VERSION ""

NS_ :

BS_:

BU_: SCCM RF_HUB PTS ORC OCM IC HCP HALF ETM ESM ESC EPS ECM EBCM DIAGNOST DASM CBC AirSusp TCM DTCM ELSDM

BO_ 1026 NM_IC: 8 IC
 SG_ WakeupRsn_IC m2 : 32|8@1+ (1,0) [0|0] ""  EBCM,HCP,ESM,ESC,SCCM,EPS,IC,CBC,RF_HUB
 SG_ WakeupCnt_IC m2 : 40|8@1+ (1,0) [0|254] ""  EBCM,HCP,ESM,ESC,SCCM,EPS,IC,CBC,RF_HUB
 SG_ Nw_Id_IC : 56|8@1+ (1,0) [0|0] ""  EBCM,HCP,ESM,ESC,SCCM,EPS,IC,CBC,RF_HUB
 SG_ NM_Ud_Srv_IC M : 24|8@1+ (1,0) [0|0] ""  EBCM,HCP,ESM,ESC,SCCM,EPS,IC,CBC,RF_HUB
 SG_ NM_Ud_Launch_IC : 16|6@1+ (1,0) [0|0] ""  EBCM,HCP,ESM,ESC,SCCM,EPS,IC,CBC,RF_HUB
 SG_ NM_Successor_IC : 8|8@1+ (1,0) [0|63] ""  EBCM,HCP,ESM,ESC,SCCM,EPS,IC,CBC,RF_HUB
 SG_ NM_Sleep_Ind_IC : 23|1@1+ (1,0) [0|0] ""  EBCM,HCP,ESM,ESC,SCCM,EPS,IC,CBC,RF_HUB
 SG_ NM_Sleep_Ack_IC : 22|1@1+ (1,0) [0|0] ""  EBCM,HCP,ESM,ESC,SCCM,EPS,IC,CBC,RF_HUB
 SG_ NM_Mode_IC : 0|8@1+ (1,0) [0|0] ""  EBCM,HCP,ESM,ESC,SCCM,EPS,IC,CBC,RF_HUB
 SG_ Awake_NwSt_IC m15 : 32|1@1+ (1,0) [0|0] ""  EBCM,HCP,ESM,ESC,SCCM,EPS,IC,CBC,RF_HUB
 SG_ Awake_Diag_Actv_IC m15 : 33|1@1+ (1,0) [0|0] ""  EBCM,HCP,ESM,ESC,SCCM,EPS,IC,CBC,RF_HUB

BO_ 1025 NM_CBC: 8 CBC
 SG_ WakeupRsn_CBC m2 : 32|8@1+ (1,0) [0|0] ""  EBCM,HCP,ESM,ESC,SCCM,EPS,IC,CBC,RF_HUB
 SG_ WakeupCnt_CBC m2 : 40|8@1+ (1,0) [0|254] ""  EBCM,HCP,ESM,ESC,SCCM,EPS,IC,CBC,RF_HUB
 SG_ Nw_Id_CBC : 56|8@1+ (1,0) [0|0] ""  EBCM,HCP,ESM,ESC,SCCM,EPS,IC,CBC,RF_HUB
 SG_ NM_Ud_Srv_CBC M : 24|8@1+ (1,0) [0|0] ""  EBCM,HCP,ESM,ESC,SCCM,EPS,IC,CBC,RF_HUB
 SG_ NM_Ud_Launch_CBC : 16|6@1+ (1,0) [0|0] ""  EBCM,HCP,ESM,ESC,SCCM,EPS,IC,CBC,RF_HUB
 SG_ NM_Successor_CBC : 8|8@1+ (1,0) [0|63] ""  EBCM,HCP,ESM,ESC,SCCM,EPS,IC,CBC,RF_HUB
 SG_ NM_Sleep_Ind_CBC : 23|1@1+ (1,0) [0|0] ""  EBCM,HCP,ESM,ESC,SCCM,EPS,IC,CBC,RF_HUB
 SG_ NM_Sleep_Ack_CBC : 22|1@1+ (1,0) [0|0] ""  EBCM,HCP,ESM,ESC,SCCM,EPS,IC,CBC,RF_HUB
 SG_ NM_Mode_CBC : 0|8@1+ (1,0) [0|0] ""  EBCM,HCP,ESM,ESC,SCCM,EPS,IC,CBC,RF_HUB
 SG_ Awake_NwSt_CBC m15 : 32|1@1+ (1,0) [0|0] ""  EBCM,HCP,ESM,ESC,SCCM,EPS,IC,CBC,RF_HUB
 SG_ Awake_Diag_Actv_CBC m15 : 33|1@1+ (1,0) [0|0] ""  EBCM,HCP,ESM,ESC,SCCM,EPS,IC,CBC,RF_HUB

BO_ 1024 NM_RF_HUB: 8 RF_HUB
 SG_ WakeupRsn_RF_HUB m2 : 32|8@1+ (1,0) [0|0] ""  EBCM,HCP,ESM,ESC,SCCM,EPS,IC,CBC,RF_HUB
 SG_ WakeupCnt_RF_HUB m2 : 40|8@1+ (1,0) [0|254] ""  EBCM,HCP,ESM,ESC,SCCM,EPS,IC,CBC,RF_HUB
 SG_ Nw_Id_RF_HUB : 56|8@1+ (1,0) [0|0] ""  EBCM,HCP,ESM,ESC,SCCM,EPS,IC,CBC,RF_HUB
 SG_ NM_Ud_Srv_RF_HUB M : 24|8@1+ (1,0) [0|0] ""  EBCM,HCP,ESM,ESC,SCCM,EPS,IC,CBC,RF_HUB
 SG_ NM_Ud_Launch_RF_HUB : 16|6@1+ (1,0) [0|0] ""  EBCM,HCP,ESM,ESC,SCCM,EPS,IC,CBC,RF_HUB
 SG_ NM_Successor_RF_HUB : 8|8@1+ (1,0) [0|63] ""  EBCM,HCP,ESM,ESC,SCCM,EPS,IC,CBC,RF_HUB
 SG_ NM_Sleep_Ind_RF_HUB : 23|1@1+ (1,0) [0|0] ""  EBCM,HCP,ESM,ESC,SCCM,EPS,IC,CBC,RF_HUB
 SG_ NM_Sleep_Ack_RF_HUB : 22|1@1+ (1,0) [0|0] ""  EBCM,HCP,ESM,ESC,SCCM,EPS,IC,CBC,RF_HUB
 SG_ NM_Mode_RF_HUB : 0|8@1+ (1,0) [0|0] ""  EBCM,HCP,ESM,ESC,SCCM,EPS,IC,CBC,RF_HUB
 SG_ Awake_NwSt_RF_HUB m15 : 32|1@1+ (1,0) [0|0] ""  EBCM,HCP,ESM,ESC,SCCM,EPS,IC,CBC,RF_HUB
 SG_ Awake_Diag_Actv_RF_HUB m15 : 33|1@1+ (1,0) [0|0] ""  EBCM,HCP,ESM,ESC,SCCM,EPS,IC,CBC,RF_HUB

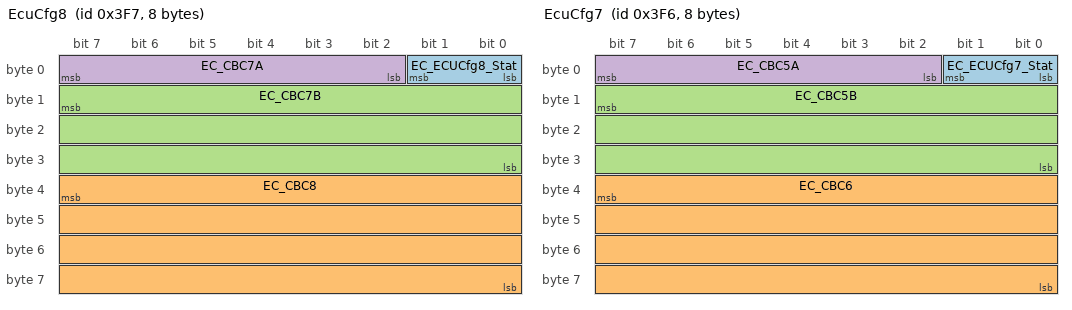
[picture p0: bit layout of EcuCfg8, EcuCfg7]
BO_ 1015 EcuCfg8: 8 CBC
 SG_ EC_ECUCfg8_Stat : 0|2@1+ (1,0) [0|0] ""  RF_HUB
 SG_ EC_CBC8 : 39|32@0+ (1,0) [0|0] ""  RF_HUB
 SG_ EC_CBC7B : 15|24@0+ (1,0) [0|0] ""  RF_HUB
 SG_ EC_CBC7A : 2|6@1+ (1,0) [0|0] ""  RF_HUB

BO_ 1014 EcuCfg7: 8 CBC
 SG_ EC_ECUCfg7_Stat : 0|2@1+ (1,0) [0|0] ""  RF_HUB
 SG_ EC_CBC6 : 39|32@0+ (1,0) [0|0] ""  RF_HUB
 SG_ EC_CBC5B : 15|24@0+ (1,0) [0|0] ""  RF_HUB
 SG_ EC_CBC5A : 2|6@1+ (1,0) [0|0] ""  RF_HUB

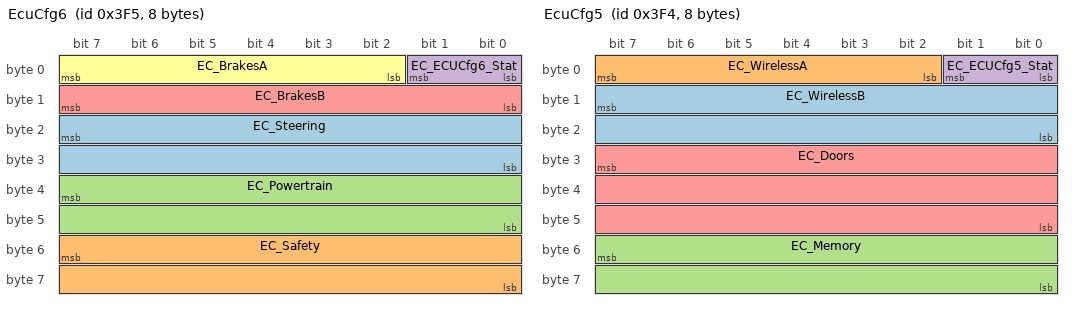
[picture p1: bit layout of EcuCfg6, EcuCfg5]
BO_ 1013 EcuCfg6: 8 CBC
 SG_ EC_Steering : 23|16@0+ (1,0) [0|0] ""  RF_HUB,EPS
 SG_ EC_Safety : 55|16@0+ (1,0) [0|0] ""  ORC,RF_HUB
 SG_ EC_Powertrain : 39|16@0+ (1,0) [0|0] ""  RF_HUB
 SG_ EC_ECUCfg6_Stat : 0|2@1+ (1,0) [0|0] ""  RF_HUB,ORC,ESC,ECM
 SG_ EC_BrakesB : 8|8@1+ (1,0) [0|0] ""  ESC,RF_HUB
 SG_ EC_BrakesA : 2|6@1+ (1,0) [0|0] ""  ESC,RF_HUB

BO_ 1012 EcuCfg5: 8 CBC
 SG_ EC_WirelessB : 15|16@0+ (1,0) [0|0] ""  RF_HUB
 SG_ EC_WirelessA : 2|6@1+ (1,0) [0|0] ""  RF_HUB
 SG_ EC_Memory : 55|16@0+ (1,0) [0|0] ""  RF_HUB,OCM
 SG_ EC_ECUCfg5_Stat : 0|2@1+ (1,0) [0|0] ""  RF_HUB,OCM
 SG_ EC_Doors : 31|24@0+ (1,0) [0|0] ""  RF_HUB

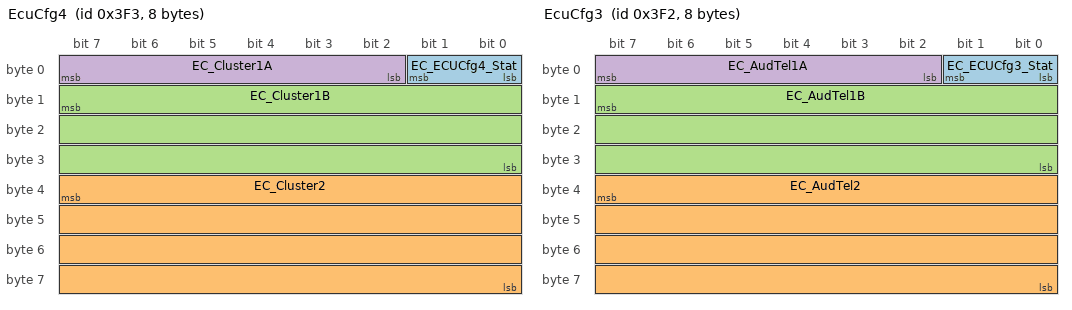
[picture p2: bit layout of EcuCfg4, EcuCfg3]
BO_ 1011 EcuCfg4: 8 CBC
 SG_ EC_ECUCfg4_Stat : 0|2@1+ (1,0) [0|0] ""  IC,RF_HUB
 SG_ EC_Cluster2 : 39|32@0+ (1,0) [0|0] ""  RF_HUB
 SG_ EC_Cluster1B : 15|24@0+ (1,0) [0|0] ""  RF_HUB,IC
 SG_ EC_Cluster1A : 2|6@1+ (1,0) [0|0] ""  IC,RF_HUB

BO_ 1010 EcuCfg3: 8 CBC
 SG_ EC_ECUCfg3_Stat : 0|2@1+ (1,0) [0|0] ""  RF_HUB
 SG_ EC_AudTel2 : 39|32@0+ (1,0) [0|0] ""  RF_HUB
 SG_ EC_AudTel1B : 15|24@0+ (1,0) [0|0] ""  RF_HUB
 SG_ EC_AudTel1A : 2|6@1+ (1,0) [0|0] ""  RF_HUB

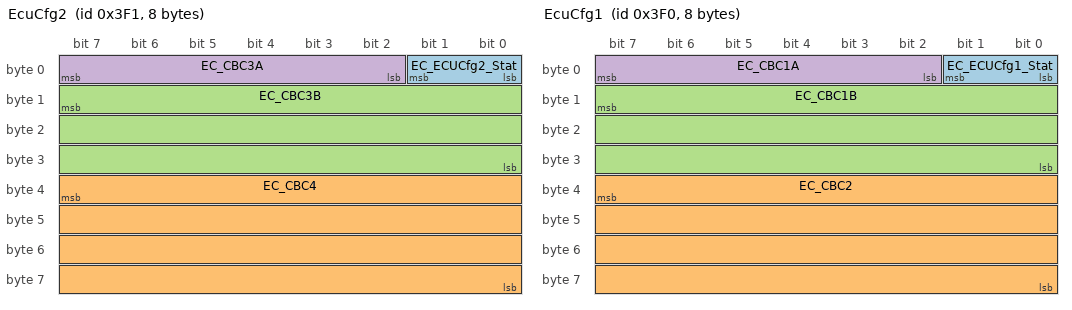
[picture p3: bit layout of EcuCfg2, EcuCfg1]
BO_ 1009 EcuCfg2: 8 CBC
 SG_ EC_ECUCfg2_Stat : 0|2@1+ (1,0) [0|0] ""  RF_HUB
 SG_ EC_CBC4 : 39|32@0+ (1,0) [0|0] ""  RF_HUB
 SG_ EC_CBC3B : 15|24@0+ (1,0) [0|0] ""  RF_HUB
 SG_ EC_CBC3A : 2|6@1+ (1,0) [0|0] ""  RF_HUB

BO_ 1008 EcuCfg1: 8 CBC
 SG_ EC_ECUCfg1_Stat : 0|2@1+ (1,0) [0|0] ""  RF_HUB
 SG_ EC_CBC2 : 39|32@0+ (1,0) [0|0] ""  RF_HUB
 SG_ EC_CBC1B : 15|24@0+ (1,0) [0|0] ""  RF_HUB
 SG_ EC_CBC1A : 2|6@1+ (1,0) [0|0] ""  RF_HUB

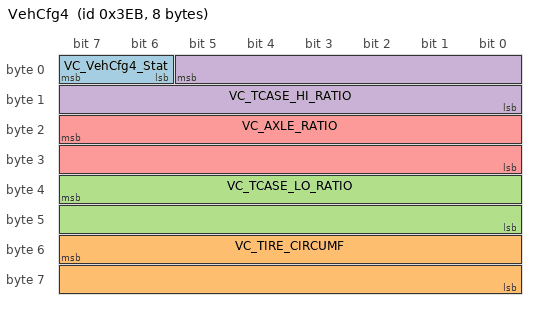
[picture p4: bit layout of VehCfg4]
BO_ 1003 VehCfg4: 8 CBC
 SG_ VC_VehCfg4_Stat : 6|2@1+ (1,0) [0|0] ""  RF_HUB,PTS,ORC,HCP,HALF,ESC,ECM,DASM
 SG_ VC_TIRE_CIRCUMF : 55|16@0+ (1,0) [0|65534] "mm"  RF_HUB,PTS,ORC,HALF,ESC,EPS
 SG_ VC_TCASE_LO_RATIO : 39|16@0+ (0.001,0) [0|65.534] ""  RF_HUB,ESC
 SG_ VC_TCASE_HI_RATIO : 5|14@0+ (0.001,0) [0|16.382] ""  RF_HUB,ESC
 SG_ VC_AXLE_RATIO : 23|16@0+ (0.001,0) [0|65.534] ""  RF_HUB,ESC,DASM

BO_ 1002 VehCfg3: 8 CBC
 SG_ VC_WIN_EXPR_FEAT : 24|2@1+ (1,0) [0|0] ""  RF_HUB
 SG_ VC_WHL_BASE : 12|2@1+ (1,0) [0|0] ""  RF_HUB,IC
 SG_ VC_VehCfg3_Stat : 0|2@1+ (1,0) [0|0] ""  SCCM,RF_HUB,PTS,ORC,IC,HCP,HALF,ESC,ECM,DASM
 SG_ VC_VEH_BRAND : 44|4@1+ (1,0) [0|0] ""  RF_HUB,PTS,HALF
 SG_ VC_TEMP_DISP : 39|1@1+ (1,0) [0|0] ""  IC,RF_HUB
 SG_ VC_TcaseTyp : 8|4@1+ (1,0) [0|0] ""  ESC,RF_HUB
 SG_ VC_SunShade_Present : 7|1@1+ (1,0) [0|0] ""  RF_HUB
 SG_ VC_SRT_PRSNT : 30|1@1+ (1,0) [0|0] ""  RF_HUB,ORC
 SG_ VC_SPORT_PRSNT : 60|1@1+ (1,0) [0|0] ""  RF_HUB
 SG_ VC_SecLkPrsnt : 52|1@1+ (1,0) [0|0] ""  RF_HUB
 SG_ VC_RKE_PRSNT : 6|1@1+ (1,0) [0|0] ""  RF_HUB
 SG_ VC_PWR_RT_SLDR : 4|1@1+ (1,0) [0|0] ""  RF_HUB
 SG_ VC_PWR_LT_SLDR : 5|1@1+ (1,0) [0|0] ""  RF_HUB
 SG_ VC_PWR_LFT_GT : 3|1@1+ (1,0) [0|0] ""  RF_HUB
 SG_ VC_Prem_TPM : 58|1@1+ (1,0) [0|0] ""  ORC,IC,RF_HUB
 SG_ VC_POLICE : 2|1@1+ (1,0) [0|0] ""  RF_HUB,ORC
 SG_ VC_PE_Prsnt : 62|1@1+ (1,0) [0|0] ""  RF_HUB
 SG_ VC_PDDL_PRSNT : 59|1@1+ (1,0) [0|0] ""  RF_HUB
 SG_ VC_Liftgate_Trunk : 53|2@1+ (1,0) [0|0] ""  IC,RF_HUB
 SG_ VC_KG_Prsnt : 63|1@1+ (1,0) [0|0] ""  RF_HUB,IC
 SG_ VC_IntEC_MIRR : 49|1@1+ (1,0) [0|0] ""  RF_HUB
 SG_ VC_HVAC_Config : 40|4@1+ (1,0) [0|0] ""  RF_HUB
 SG_ VC_HID_HL : 51|1@1+ (1,0) [0|0] ""  RF_HUB
 SG_ VC_FUEL_CAP : 16|8@1+ (1,36) [36|290] "liters"  IC,RF_HUB
 SG_ VC_FOBIKsafeENBL : 14|1@1+ (1,0) [0|0] ""  RF_HUB
 SG_ VC_FCW : 56|1@1+ (1,0) [0|0] ""  HALF,ORC,DASM,ESC,RF_HUB
 SG_ VC_ESCL_PRSNT : 50|1@1+ (1,0) [0|0] ""  RF_HUB
 SG_ VC_ELV_Prsnt : 15|1@1+ (1,0) [0|0] ""  RF_HUB
 SG_ VC_DualFuelSens : 29|1@1+ (1,0) [0|0] ""  IC,RF_HUB
 SG_ VC_DSBL_CLK_DISP : 31|1@1+ (1,0) [0|0] ""  RF_HUB
 SG_ VC_DrAlrPrsnt : 28|1@1+ (1,0) [0|0] ""  RF_HUB
 SG_ VC_CMS : 55|1@1+ (1,0) [0|0] ""  HALF,ORC,DASM,ESC,RF_HUB
 SG_ VC_CMP_DISP : 48|1@1+ (1,0) [0|0] ""  IC,RF_HUB
 SG_ VC_ChassisType : 32|7@1+ (1,0) [0|126] ""  RF_HUB,HALF,ESC
 SG_ VC_Base_TPM : 57|1@1+ (1,0) [0|0] ""  ORC,IC,RF_HUB
 SG_ VC_AutoParkPrsnt : 61|1@1+ (1,0) [0|0] ""  RF_HUB
 SG_ VC_AUTO_HL : 27|1@1+ (1,0) [0|0] ""  RF_HUB
 SG_ VC_ADJ_PDL_PRSNT : 26|1@1+ (1,0) [0|0] ""  RF_HUB

BO_ 1001 VehCfg2: 8 CBC
 SG_ VC_VehCfg2_Stat : 0|2@1+ (1,0) [0|0] ""  SCCM,RF_HUB,ORC,IC,HCP,ESC,ECM,DASM
 SG_ VC_ThatchamPrsnt : 4|1@1+ (1,0) [0|0] ""  RF_HUB
 SG_ VC_SpecialPKG_IC : 16|8@1+ (1,0) [0|0] ""  RF_HUB,ORC
 SG_ VC_SKIM_PRSNT : 10|1@1+ (1,0) [0|0] ""  RF_HUB
 SG_ VC_ShftInd_Prsnt : 30|2@1+ (1,0) [0|0] ""  RF_HUB
 SG_ VC_SecPrkPrsnt : 29|1@1+ (1,0) [0|0] ""  RF_HUB
 SG_ VC_RunFlatTirePrsnt : 5|1@1+ (1,0) [0|0] ""  RF_HUB
 SG_ VC_RainSnsPrsnt : 9|1@1+ (1,0) [0|0] ""  RF_HUB
 SG_ VC_PwrIvtrTyp : 2|2@1+ (1,0) [0|0] ""  RF_HUB
 SG_ VC_PADS_Prsnt : 8|1@1+ (1,0) [0|0] ""  ORC,RF_HUB
 SG_ VC_OffRoad : 15|1@1+ (1,0) [0|0] ""  RF_HUB
 SG_ VC_MemoryDRVMD_Prsnt : 26|1@1+ (1,0) [0|0] ""  RF_HUB
 SG_ VC_MaxLdPressRrTr : 32|8@1+ (1,0) [0|126] "psi"  IC,RF_HUB
 SG_ VC_MaxLdPressFtTr : 40|8@1+ (1,0) [0|126] "psi"  IC,RF_HUB
 SG_ VC_MaseratiMd : 6|2@1+ (1,0) [0|0] ""  RF_HUB
 SG_ VC_LgtLdPressRrTr : 48|8@1+ (1,0) [0|126] "psi"  RF_HUB
 SG_ VC_LgtLdPressFtTr : 56|8@1+ (1,0) [0|126] "psi"  RF_HUB
 SG_ VC_FULL_SPARE : 14|1@1+ (1,0) [0|0] ""  RF_HUB
 SG_ VC_FG_PRSNT : 13|1@1+ (1,0) [0|0] ""  RF_HUB
 SG_ VC_ESCDrvMd_Prsnt : 27|1@1+ (1,0) [0|0] ""  RF_HUB
 SG_ VC_EngPowerDrvMd_Prsnt : 28|1@1+ (1,0) [0|0] ""  RF_HUB
 SG_ VC_ECO_Indicator : 24|1@1+ (1,0) [0|0] ""  RF_HUB
 SG_ VC_DRVMD_Prsnt : 25|1@1+ (1,0) [0|0] ""  RF_HUB
 SG_ VC_CRUISE_PRSNT : 12|1@1+ (1,0) [0|0] ""  SCCM,RF_HUB,ORC,HCP,DASM
 SG_ VC_AC_Prsnt : 11|1@1+ (1,0) [0|0] ""  RF_HUB

BO_ 1000 VehCfg1: 8 CBC
 SG_ VC_XWD : 24|2@1+ (1,0) [0|0] ""  RF_HUB,ORC,HALF,ESM,ESC,DASM
 SG_ VC_VehCfg1_Stat : 0|2@1+ (1,0) [0|0] ""  EBCM,HCP,HALF,OCM,ORC,ESM,ECM,DASM,ESC,SCCM,EPS,PTS,IC,RF_HUB
 SG_ VC_VEH_LINE : 8|8@1+ (1,0) [0|0] ""  EBCM,HCP,HALF,OCM,ORC,ESM,ECM,DASM,ESC,SCCM,EPS,PTS,IC,RF_HUB
 SG_ VC_SSC_Prsnt : 63|1@1+ (1,0) [0|0] ""  RF_HUB
 SG_ VC_SpecialPKG : 48|8@1+ (1,0) [1|254] ""  RF_HUB
 SG_ VC_ShftrTyp : 40|4@1+ (1,0) [0|0] ""  RF_HUB,IC,HCP,ESM
 SG_ VC_SCR_Prsnt : 57|1@1+ (1,0) [0|0] ""  RF_HUB
 SG_ VC_RVCM_Prsnt : 60|1@1+ (1,0) [0|0] ""  RF_HUB
 SG_ VC_RemStPrsnt : 23|1@1+ (1,0) [0|0] ""  RF_HUB,IC,HCP
 SG_ VC_PTS_DispTyp : 44|3@1+ (1,0) [0|0] ""  RF_HUB
 SG_ VC_PTS_Config : 58|2@1+ (1,0) [0|0] ""  RF_HUB,IC
 SG_ VC_PP_Prsnt : 47|1@1+ (1,0) [0|0] ""  RF_HUB
 SG_ VC_MODEL_YEAR : 2|6@1+ (1,2000) [2000|2062] "model-year"  EBCM,HCP,HALF,OCM,ORC,ESM,ECM,DASM,ESC,SCCM,EPS,PTS,IC,RF_HUB
 SG_ VC_MAX_VEH_SPD : 32|8@1+ (2,0) [0|506] "kph"  RF_HUB
 SG_ VC_LHD_RHD : 21|2@1+ (1,0) [0|0] ""  RF_HUB,PTS,IC,HALF,ESM,ESC
 SG_ VC_HdRstPrsnt : 56|1@1+ (1,0) [0|0] ""  RF_HUB
 SG_ VC_HDC_Prsnt : 62|1@1+ (1,0) [0|0] ""  RF_HUB
 SG_ VC_EmodePrsnt : 26|1@1+ (1,0) [0|0] ""  RF_HUB
 SG_ VC_COUNTRY : 16|5@1+ (1,0) [0|0] ""  EBCM,HCP,HALF,OCM,ORC,ESM,ECM,DASM,ESC,SCCM,EPS,PTS,IC,RF_HUB
 SG_ VC_CHMCM_Prsnt : 61|1@1+ (1,0) [0|0] ""  RF_HUB
 SG_ VC_BODY_STYLE : 28|4@1+ (1,0) [0|0] ""  EBCM,HCP,HALF,OCM,ORC,ESM,ECM,DASM,ESC,SCCM,EPS,PTS,IC,RF_HUB
 SG_ VC_AUTO_HB : 27|1@1+ (1,0) [0|0] ""  RF_HUB,HALF

BO_ 996 NET_CFG_PT: 8 CBC
 SG_ NetCfg_VSIM_C : 5|1@1+ (1,0) [0|0] ""  RF_HUB
 SG_ NetCfg_TPM : 26|1@1+ (1,0) [0|0] ""  RF_HUB,IC
 SG_ NetCfg_TCM : 25|1@1+ (1,0) [0|0] ""  RF_HUB,ORC,ESM
 SG_ NetCfg_SCCM : 23|1@1+ (1,0) [0|0] ""  RF_HUB,EPS,DASM
 SG_ NetCfg_RF_HUB : 14|1@1+ (1,0) [0|0] ""  RF_HUB,IC
 SG_ NetCfg_PTS : 20|1@1+ (1,0) [0|0] ""  RF_HUB,IC,ESC,EPS
 SG_ NetCfg_PASS_PT : 27|1@1+ (1,0) [0|0] ""  RF_HUB
 SG_ NetCfg_ORC : 19|1@1+ (1,0) [0|0] ""  RF_HUB,DASM
 SG_ NetCfg_OCM : 30|1@1+ (1,0) [0|0] ""  ORC,RF_HUB
 SG_ NetCfg_ITBM : 29|1@1+ (1,0) [0|0] ""  RF_HUB
 SG_ NetCfg_IC : 15|1@1+ (1,0) [0|0] ""  RF_HUB,EPS,DASM
 SG_ NetCfg_HCP : 38|1@1+ (1,0) [0|0] ""  RF_HUB,PTS,EPS
 SG_ NetCfg_HaLF : 31|1@1+ (1,0) [0|0] ""  RF_HUB,HALF,DASM
 SG_ NetCfg_FDCM : 17|1@1+ (1,0) [0|0] ""  RF_HUB
 SG_ NetCfg_ESM : 11|1@1+ (1,0) [0|0] ""  RF_HUB
 SG_ NetCfg_ESL : 37|1@1+ (1,0) [0|0] ""  RF_HUB
 SG_ NetCfg_ESC : 12|1@1+ (1,0) [0|0] ""  RF_HUB
 SG_ NetCfg_EPS : 10|1@1+ (1,0) [0|0] ""  RF_HUB,ORC,IC,HALF
 SG_ NetCfg_EPPM : 18|1@1+ (1,0) [0|0] ""  RF_HUB
 SG_ NetCfg_EPB : 13|1@1+ (1,0) [0|0] ""  RF_HUB
 SG_ NetCfg_ELSD : 24|1@1+ (1,0) [0|0] ""  RF_HUB
 SG_ NetCfg_ECM : 9|1@1+ (1,0) [0|0] ""  RF_HUB,EPS,DASM
 SG_ NetCfg_DTCM : 8|1@1+ (1,0) [0|0] ""  RF_HUB,DASM
 SG_ NetCfg_DASM : 16|1@1+ (1,0) [0|0] ""  SCCM,RF_HUB,IC,ESC,ECM,DASM
 SG_ NetCfg_CBC_PT : 7|1@1+ (1,0) [0|0] ""  RF_HUB,EPS
 SG_ NetCfg_BSMO : 36|1@1+ (1,0) [0|0] ""  RF_HUB,IC,EPS
 SG_ NetCfg_ASCM : 6|1@1+ (1,0) [0|0] ""  RF_HUB,HALF,DASM
 SG_ NetCfg_ANC : 39|1@1+ (1,0) [0|0] ""  RF_HUB
 SG_ NetCfg_AHLM : 4|1@1+ (1,0) [0|0] ""  RF_HUB
 SG_ NetCfg_AFLS : 28|1@1+ (1,0) [0|0] ""  RF_HUB
 SG_ NetCfg_ADCM : 3|1@1+ (1,0) [0|0] ""  RF_HUB
 SG_ NetCfg_ACC : 2|1@1+ (1,0) [0|0] ""  RF_HUB
 SG_ NET_CFG_STAT_PT : 0|2@1+ (1,0) [0|0] ""  SCCM,RF_HUB,PTS,ORC,OCM,IC,HCP,HALF,ESC,ECM,EBCM,DASM

BO_ 995 NET_CFG_INT: 8 CBC
 SG_ NetCfg_VTM : 13|1@1+ (1,0) [0|0] ""  RF_HUB
 SG_ NetCfg_VSIM : 22|1@1+ (1,0) [0|0] ""  RF_HUB
 SG_ NetCfg_VRM : 36|1@1+ (1,0) [0|0] ""  RF_HUB
 SG_ NetCfg_VES3_I : 29|1@1+ (1,0) [0|0] ""  RF_HUB
 SG_ NetCfg_VES2_I : 28|1@1+ (1,0) [0|0] ""  RF_HUB
 SG_ NetCfg_TTM : 47|1@1+ (1,0) [0|0] ""  RF_HUB
 SG_ NetCfg_TMM : 33|1@1+ (1,0) [0|0] ""  RF_HUB
 SG_ NetCfg_TGW : 20|1@1+ (1,0) [0|0] ""  RF_HUB,HALF
 SG_ NetCfg_TBM : 38|1@1+ (1,0) [0|0] ""  RF_HUB
 SG_ NetCfg_RBSS : 2|1@1+ (1,0) [0|0] ""  RF_HUB
 SG_ NetCfg_RBC : 18|1@1+ (1,0) [0|0] ""  RF_HUB
 SG_ NetCfg_PTCM : 17|1@1+ (1,0) [0|0] ""  RF_HUB
 SG_ NetCfg_PSD_RT : 15|1@1+ (1,0) [0|0] ""  RF_HUB
 SG_ NetCfg_PSD_LT : 14|1@1+ (1,0) [0|0] ""  RF_HUB
 SG_ NetCfg_PLG : 12|1@1+ (1,0) [0|0] ""  RF_HUB
 SG_ NetCfg_MSM_PASS : 35|1@1+ (1,0) [0|0] ""  RF_HUB
 SG_ NetCfg_MSM : 11|1@1+ (1,0) [0|0] ""  RF_HUB
 SG_ NetCfg_ITM : 23|1@1+ (1,0) [0|0] ""  RF_HUB
 SG_ NetCfg_ICS_R : 34|1@1+ (1,0) [0|0] ""  RF_HUB
 SG_ NetCfg_ICS_I : 27|1@1+ (1,0) [0|0] ""  RF_HUB
 SG_ NetCfg_HVAC_R : 31|1@1+ (1,0) [0|0] ""  RF_HUB
 SG_ NetCfg_HVAC : 10|1@1+ (1,0) [0|0] ""  RF_HUB
 SG_ NetCfg_HFM_CTM : 26|1@1+ (1,0) [0|0] ""  RF_HUB
 SG_ NetCfg_FSM : 16|1@1+ (1,0) [0|0] ""  RF_HUB
 SG_ NetCfg_DVD_CDM : 25|1@1+ (1,0) [0|0] ""  RF_HUB
 SG_ NetCfg_DTV : 19|1@1+ (1,0) [0|0] ""  RF_HUB
 SG_ NetCfg_DCSD : 37|1@1+ (1,0) [0|0] ""  RF_HUB
 SG_ NetCfg_DCM_RR : 9|1@1+ (1,0) [0|0] ""  RF_HUB
 SG_ NetCfg_DCM_RL : 8|1@1+ (1,0) [0|0] ""  RF_HUB
 SG_ NetCfg_DCM_PASS : 7|1@1+ (1,0) [0|0] ""  RF_HUB
 SG_ NetCfg_DCM_DR : 6|1@1+ (1,0) [0|0] ""  RF_HUB
 SG_ NetCfg_CVPM : 32|1@1+ (1,0) [0|0] ""  RF_HUB
 SG_ NetCfg_CSWM : 5|1@1+ (1,0) [0|0] ""  RF_HUB
 SG_ NetCfg_CRSM : 30|1@1+ (1,0) [0|0] ""  RF_HUB
 SG_ NetCfg_CLOCK : 21|1@1+ (1,0) [0|0] ""  RF_HUB
 SG_ NetCfg_CBC_IN : 4|1@1+ (1,0) [0|0] ""  RF_HUB
 SG_ NetCfg_BSM : 3|1@1+ (1,0) [0|0] ""  RF_HUB,IC,DASM
 SG_ NetCfg_ANC_I : 39|1@1+ (1,0) [0|0] ""  RF_HUB
 SG_ NetCfg_AMP_I : 24|1@1+ (1,0) [0|0] ""  RF_HUB
 SG_ NET_CFG_STAT_INT : 0|2@1+ (1,0) [0|0] ""  IC,RF_HUB

CM_ SG_ 1026 WakeupRsn_IC "Wakeup reason IC";
CM_ SG_ 1026 WakeupCnt_IC "Counter for module wakeup states during network sleep";
CM_ SG_ 1026 Nw_Id_IC "Network identification no.";
CM_ SG_ 1026 NM_Ud_Srv_IC "Network management userdata service no.";
CM_ SG_ 1026 NM_Ud_Launch_IC "Network management userdata launch type";
CM_ SG_ 1026 NM_Successor_IC "Network management logical successor";
CM_ SG_ 1026 NM_Sleep_Ind_IC "Network management sleep indication; True = [1]";
CM_ SG_ 1026 NM_Sleep_Ack_IC "Network management sleep acknowledge; True = [1]";
CM_ SG_ 1026 NM_Mode_IC "Network management mode";
CM_ SG_ 1026 Awake_NwSt_IC "Stay awake for network startup; True = [1]";
CM_ SG_ 1026 Awake_Diag_Actv_IC "Stay awake for diagnostics active; True = [1]";
CM_ SG_ 1025 WakeupRsn_CBC "Wakeup reason CBC";
CM_ SG_ 1025 WakeupCnt_CBC "Counter for module wakeup states during network sleep";
CM_ SG_ 1025 Nw_Id_CBC "Network identification no.";
CM_ SG_ 1025 NM_Ud_Srv_CBC "Network management userdata service no.";
CM_ SG_ 1025 NM_Ud_Launch_CBC "Network management userdata launch type";
CM_ SG_ 1025 NM_Successor_CBC "Network management logical successor";
CM_ SG_ 1025 NM_Sleep_Ind_CBC "Network management sleep indication; True = [1]";
CM_ SG_ 1025 NM_Sleep_Ack_CBC "Network management sleep acknowledge; True = [1]";
CM_ SG_ 1025 NM_Mode_CBC "Network management mode";
CM_ SG_ 1025 Awake_NwSt_CBC "Stay awake for network startup; True = [1]";
CM_ SG_ 1025 Awake_Diag_Actv_CBC "Stay awake for diagnostics active; True = [1]";
CM_ SG_ 1024 WakeupRsn_RF_HUB "Wakeup reason RF_HUB";
CM_ SG_ 1024 WakeupCnt_RF_HUB "Counter for module wakeup states during network sleep";
CM_ SG_ 1024 Nw_Id_RF_HUB "Network identification no.";
CM_ SG_ 1024 NM_Ud_Srv_RF_HUB "Network management userdata service no.";
CM_ SG_ 1024 NM_Ud_Launch_RF_HUB "Network management userdata launch type";
CM_ SG_ 1024 NM_Successor_RF_HUB "Network management logical successor";
CM_ SG_ 1024 NM_Sleep_Ind_RF_HUB "Network management sleep indication; True = [1]";
CM_ SG_ 1024 NM_Sleep_Ack_RF_HUB "Network management sleep acknowledge; True = [1]";
CM_ SG_ 1024 NM_Mode_RF_HUB "Network management mode";
CM_ SG_ 1024 Awake_NwSt_RF_HUB "Stay awake for network startup; True = [1]";
CM_ SG_ 1024 Awake_Diag_Actv_RF_HUB "Stay awake for diagnostics active; True = [1]";
CM_ SG_ 1015 EC_ECUCfg8_Stat "ECU Configuration messages status 8";
CM_ SG_ 1015 EC_CBC8 "CBC ecu configuration 8";
CM_ SG_ 1015 EC_CBC7B "CBC ecu configuration 7B";
CM_ SG_ 1015 EC_CBC7A "CBC ecu configuration 7A";
CM_ SG_ 1014 EC_ECUCfg7_Stat "ECU Configuration messages status 7";
CM_ SG_ 1014 EC_CBC6 "CBC ecu configuration 6";
CM_ SG_ 1014 EC_CBC5B "CBC ecu configuration 5B";
CM_ SG_ 1014 EC_CBC5A "CBC ecu configuration 5A";
CM_ SG_ 1013 EC_Steering "Steering ecu configuration";
CM_ SG_ 1013 EC_Safety "Safety ecu configuration";
CM_ SG_ 1013 EC_Powertrain "Powertrain ecu configuration";
CM_ SG_ 1013 EC_ECUCfg6_Stat "ECU Configuration messages status 6";
CM_ SG_ 1013 EC_BrakesB "Brake system ecu configurationB";
CM_ SG_ 1013 EC_BrakesA "Brake system ecu configurationA";
CM_ SG_ 1012 EC_WirelessB "Wireless ecu configurationB";
CM_ SG_ 1012 EC_WirelessA "Wireless ecu configurationA";
CM_ SG_ 1012 EC_Memory "Memory ecu configuration";
CM_ SG_ 1012 EC_ECUCfg5_Stat "ECU Configuration messages status 5";
CM_ SG_ 1012 EC_Doors "Doors ecu configuration";
CM_ SG_ 1011 EC_ECUCfg4_Stat "ECU Configuration messages status 4";
CM_ SG_ 1011 EC_Cluster2 "Instrument cluster ecu configuration 2";
CM_ SG_ 1011 EC_Cluster1B "Instrument cluster ecu configuration 1B";
CM_ SG_ 1011 EC_Cluster1A "Instrument cluster ecu configuration 1A";
CM_ SG_ 1010 EC_ECUCfg3_Stat "ECU Configuration messages status 3";
CM_ SG_ 1010 EC_AudTel2 "Audio and telematics ecu configuration 2";
CM_ SG_ 1010 EC_AudTel1B "Audio and telematics ecu configuration 1B";
CM_ SG_ 1010 EC_AudTel1A "Audio and telematics ecu configuration 1A";
CM_ SG_ 1009 EC_ECUCfg2_Stat "ECU Configuration messages status 2";
CM_ SG_ 1009 EC_CBC4 "CBC ecu configuration 4";
CM_ SG_ 1009 EC_CBC3B "CBC ecu configuration 3B";
CM_ SG_ 1009 EC_CBC3A "CBC ecu configuration 3A";
CM_ SG_ 1008 EC_ECUCfg1_Stat "ECU Configuration messages status 1";
CM_ SG_ 1008 EC_CBC2 "CBC ecu configuration 2";
CM_ SG_ 1008 EC_CBC1B "CBC ecu configuration 1B";
CM_ SG_ 1008 EC_CBC1A "CBC ecu configuration 1A";
CM_ SG_ 1003 VC_VehCfg4_Stat "Configuration messages status 4";
CM_ SG_ 1003 VC_TIRE_CIRCUMF "Dynamic tire circumference (all or rear)";
CM_ SG_ 1003 VC_TCASE_LO_RATIO "Transfer case low range reduction ratio";
CM_ SG_ 1003 VC_TCASE_HI_RATIO "Transfer case high ratio";
CM_ SG_ 1003 VC_AXLE_RATIO "Axle ratio";
CM_ SG_ 1002 VC_WIN_EXPR_FEAT "Window express feature configuration";
CM_ SG_ 1002 VC_WHL_BASE "Wheel base";
CM_ SG_ 1002 VC_VehCfg3_Stat "Configuration messages status 3";
CM_ SG_ 1002 VC_VEH_BRAND "Vehicle brand type";
CM_ SG_ 1002 VC_TEMP_DISP "Display outside temperature present; present = [1]";
CM_ SG_ 1002 VC_TcaseTyp "Tcase type";
CM_ SG_ 1002 VC_SunShade_Present "Vehicle equipped w/SunShade (1=present)";
CM_ SG_ 1002 VC_SRT_PRSNT "Vehicle is an SRT; present = [1]";
CM_ SG_ 1002 VC_SPORT_PRSNT "Sport mode is present; present = [1]";
CM_ SG_ 1002 VC_SecLkPrsnt "Secondary Lock Present; [1] = True";
CM_ SG_ 1002 VC_RKE_PRSNT "RKE system present; present = [1]";
CM_ SG_ 1002 VC_PWR_RT_SLDR "Power right sliding door present; present = [1]";
CM_ SG_ 1002 VC_PWR_LT_SLDR "Power left sliding door present; present = [1]";
CM_ SG_ 1002 VC_PWR_LFT_GT "Power lift gate present; present = [1]";
CM_ SG_ 1002 VC_Prem_TPM "Premium TPM system present; present = [1]";
CM_ SG_ 1002 VC_POLICE "Police lighting feature; present = [1]";
CM_ SG_ 1002 VC_PE_Prsnt "Feature passive entry is present; present = [1]";
CM_ SG_ 1002 VC_PDDL_PRSNT "Paddle shift feature is present; present = [1]";
CM_ SG_ 1002 VC_Liftgate_Trunk "Liftgate or trunk";
CM_ SG_ 1002 VC_KG_Prsnt "Feature keyless go is present; present = [1]";
CM_ SG_ 1002 VC_IntEC_MIRR "Vehicle is equipped with an interior EC mirror; present = [1]";
CM_ SG_ 1002 VC_HVAC_Config "HVAC Configuration";
CM_ SG_ 1002 VC_HID_HL "High intensity discharge head lamps; present = [1]";
CM_ SG_ 1002 VC_FUEL_CAP "Fuel capacity";
CM_ SG_ 1002 VC_FOBIKsafeENBL "Feature FOBIK safe is enabled; present = [1]";
CM_ SG_ 1002 VC_FCW "Forward Collision Warning present; present = [1]";
CM_ SG_ 1002 VC_ESCL_PRSNT "ESCL system present; enabled=[1], disabled=[0]";
CM_ SG_ 1002 VC_ELV_Prsnt "ELV system present; enabled=[1], disabled=[0]";
CM_ SG_ 1002 VC_DualFuelSens "Vehicle equipped with two fuel sending units; present = [1]";
CM_ SG_ 1002 VC_DSBL_CLK_DISP "Disable display of radio clock; 1 = clock display disabled";
CM_ SG_ 1002 VC_DrAlrPrsnt "Door alert feature present; present = [1]";
CM_ SG_ 1002 VC_CMS "Collision Mitigation System present; present = [1]";
CM_ SG_ 1002 VC_CMP_DISP "Display compass heading present; present = [1]";
CM_ SG_ 1002 VC_ChassisType "Chassis type (including suspension, brakes, and tires)";
CM_ SG_ 1002 VC_Base_TPM "Base TPM system present; present = [1]";
CM_ SG_ 1002 VC_AutoParkPrsnt "Automatic transmission parking feature is present; present = [1]";
CM_ SG_ 1002 VC_AUTO_HL "Auto headlamp feature present; present = [1]";
CM_ SG_ 1002 VC_ADJ_PDL_PRSNT "Adjustable pedal system present (non-memory); present = [1]";
CM_ SG_ 1001 VC_VehCfg2_Stat "Configuration messages status 2";
CM_ SG_ 1001 VC_ThatchamPrsnt "Thatcham present; present = [1]";
CM_ SG_ 1001 VC_SpecialPKG_IC "Special sales code package";
CM_ SG_ 1001 VC_SKIM_PRSNT "SKIM system present; present = [1]";
CM_ SG_ 1001 VC_ShftInd_Prsnt "Configuration for performance & gear shift indication";
CM_ SG_ 1001 VC_SecPrkPrsnt "Secure park feature present; present = [1]";
CM_ SG_ 1001 VC_RunFlatTirePrsnt "Run flat tires present; present = [1]";
CM_ SG_ 1001 VC_RainSnsPrsnt "Rain sensor present; present = [1]";
CM_ SG_ 1001 VC_PwrIvtrTyp "Power inverter type";
CM_ SG_ 1001 VC_PADS_Prsnt "Pass. airbag disable switch present; present = [1]";
CM_ SG_ 1001 VC_OffRoad "Off road capable; present = [1]";
CM_ SG_ 1001 VC_MemoryDRVMD_Prsnt "Memory drive mode sub-feature configuration (1 = Present)";
CM_ SG_ 1001 VC_MaxLdPressRrTr "Max Load Inflation Pressure Rear Tire";
CM_ SG_ 1001 VC_MaxLdPressFtTr "Max Load Inflation Pressure Front Tire";
CM_ SG_ 1001 VC_MaseratiMd "Maserati vehicle mode";
CM_ SG_ 1001 VC_LgtLdPressRrTr "Light Load Inflation Pressure Rear Tire";
CM_ SG_ 1001 VC_LgtLdPressFtTr "Light Load Inflation Pressure Front Tire";
CM_ SG_ 1001 VC_FULL_SPARE "Full size spare; present = [1]";
CM_ SG_ 1001 VC_FG_PRSNT "Flipper glass present; present = [1]";
CM_ SG_ 1001 VC_ESCDrvMd_Prsnt "ESC drive mode sub-feature configuration (1 = Present)";
CM_ SG_ 1001 VC_EngPowerDrvMd_Prsnt "ECM drive mode sub-feature configuration (1 = Present)";
CM_ SG_ 1001 VC_ECO_Indicator "ECO Indicator present on vehicle; True = [1]";
CM_ SG_ 1001 VC_DRVMD_Prsnt "Drive mode feature configuration (1 = Present)";
CM_ SG_ 1001 VC_CRUISE_PRSNT "Cruise feature is present; present = [1]";
CM_ SG_ 1001 VC_AC_Prsnt "Vehicle is equipped with air conditioning; present = [1]";
CM_ SG_ 1000 VC_XWD "Drive configuration";
CM_ SG_ 1000 VC_VehCfg1_Stat "Configuration messages status 1";
CM_ SG_ 1000 VC_VEH_LINE "Vehicle line";
CM_ SG_ 1000 VC_SSC_Prsnt "Select speed control feature is present; present = [1]";
CM_ SG_ 1000 VC_SpecialPKG "Special sales code package";
CM_ SG_ 1000 VC_ShftrTyp "Shifter type";
CM_ SG_ 1000 VC_SCR_Prsnt "Urea/SCR system present; present = [1]";
CM_ SG_ 1000 VC_RVCM_Prsnt "Rear view camera (1=present)";
CM_ SG_ 1000 VC_RemStPrsnt "Remote start present; present = [1]";
CM_ SG_ 1000 VC_PTS_DispTyp "PTS display type and location";
CM_ SG_ 1000 VC_PTS_Config "Parktronics system configuration";
CM_ SG_ 1000 VC_PP_Prsnt "Performance Pages Present (1=present)";
CM_ SG_ 1000 VC_MODEL_YEAR "Model year";
CM_ SG_ 1000 VC_MAX_VEH_SPD "Maximum vehicle speed";
CM_ SG_ 1000 VC_LHD_RHD "Left/right hand drive";
CM_ SG_ 1000 VC_HdRstPrsnt "Headrest present; present = [1]";
CM_ SG_ 1000 VC_HDC_Prsnt "Hill descent feature is present; present = [1]";
CM_ SG_ 1000 VC_EmodePrsnt "E-Mode feature present; True = [1]";
CM_ SG_ 1000 VC_COUNTRY "Country Code";
CM_ SG_ 1000 VC_CHMCM_Prsnt "CHMSL camera (1=present)";
CM_ SG_ 1000 VC_BODY_STYLE "Body style";
CM_ SG_ 1000 VC_AUTO_HB "Auto Highbeam feature present; present = [1]";
CM_ SG_ 996 NetCfg_VSIM_C "Vehicle System Interface Module (1=present)";
CM_ SG_ 996 NetCfg_TPM "Tire Pressure Monitor (1=present)";
CM_ SG_ 996 NetCfg_TCM "Automatic Transmission Controller (1=present)";
CM_ SG_ 996 NetCfg_SCCM "Steering Column Control Module (1=present)";
CM_ SG_ 996 NetCfg_RF_HUB "RF Hub Node (1=present)";
CM_ SG_ 996 NetCfg_PTS "Parktronics System (1=present)";
CM_ SG_ 996 NetCfg_PASS_PT "Personal Assistant Safety System Module PT Bus (1=present)";
CM_ SG_ 996 NetCfg_ORC "Occupant Restraint Controller (1=present)";
CM_ SG_ 996 NetCfg_OCM "Occupant Classification Module (1=present)";
CM_ SG_ 996 NetCfg_ITBM "Integrated Trailer Brake Module (1=present)";
CM_ SG_ 996 NetCfg_IC "Instrument Cluster (1=present)";
CM_ SG_ 996 NetCfg_HCP "Hybrid Control Processor (1=present)";
CM_ SG_ 996 NetCfg_HaLF "Haptic Lane Feedback module (1=present)";
CM_ SG_ 996 NetCfg_FDCM "Final Drive Control Module (1=present)";
CM_ SG_ 996 NetCfg_ESM "Electronic Shift Module (1=present)";
CM_ SG_ 996 NetCfg_ESL "Electric Steering Lock (1=present)";
CM_ SG_ 996 NetCfg_ESC "Electronic Stability Module / Anti-Lock Brake (1=present)";
CM_ SG_ 996 NetCfg_EPS "Electric Power Steering (1=present)";
CM_ SG_ 996 NetCfg_EPPM "Elect. Pedestrian protection module (1=present)";
CM_ SG_ 996 NetCfg_EPB "Electric Park Brake Module (1=present)";
CM_ SG_ 996 NetCfg_ELSD "Electric Limited Slip Differential (1=present)";
CM_ SG_ 996 NetCfg_ECM "Engine Control Module (1=present)";
CM_ SG_ 996 NetCfg_DTCM "Drivetrain Control Module (1=present)";
CM_ SG_ 996 NetCfg_DASM "Driver Assistance System Module (1=present)";
CM_ SG_ 996 NetCfg_CBC_PT "Common Body Controller PT Bus (1=present)";
CM_ SG_ 996 NetCfg_BSMO "Brake System Module - OBD (1=present)";
CM_ SG_ 996 NetCfg_ASCM "Air Suspension Control Module (1=present)";
CM_ SG_ 996 NetCfg_ANC "Active Noise Cancellation (1=present)";
CM_ SG_ 996 NetCfg_AHLM "Automatic Headlamp Leveling Module (1=present)";
CM_ SG_ 996 NetCfg_AFLS "Advanced Front Lighting System (1=present)";
CM_ SG_ 996 NetCfg_ADCM "Active Damping Control Module (1=present)";
CM_ SG_ 996 NetCfg_ACC "Active Cruise Control (1=present)";
CM_ SG_ 996 NET_CFG_STAT_PT "Network configuration status";
CM_ SG_ 995 NetCfg_VTM "Vehicle theft / tax module (1=present)";
CM_ SG_ 995 NetCfg_VSIM "Vehicle System Interface Module (1=present)";
CM_ SG_ 995 NetCfg_VRM "Video Routing Module (1=present)";
CM_ SG_ 995 NetCfg_VES3_I "CAN I Video Ent. System screen 1 Module (1=present)";
CM_ SG_ 995 NetCfg_VES2_I "CAN I Video Ent. System screen 2 Module (1=present)";
CM_ SG_ 995 NetCfg_TTM "0= Not Present;  1= Present";
CM_ SG_ 995 NetCfg_TMM "CAN I Track Mapping Module (1=present)";
CM_ SG_ 995 NetCfg_TGW "Telematics gateway (1=present)";
CM_ SG_ 995 NetCfg_TBM "Telematics Box Module (1=present)";
CM_ SG_ 995 NetCfg_RBSS "Right Blind-Spot Module (1=present)";
CM_ SG_ 995 NetCfg_RBC "Rear Body Controller Module (1=present)";
CM_ SG_ 995 NetCfg_PTCM "Power Top Control Module (1=present)";
CM_ SG_ 995 NetCfg_PSD_RT "Power Sliding Door Right Module (1=present)";
CM_ SG_ 995 NetCfg_PSD_LT "Power Sliding Door Left Module (1=present)";
CM_ SG_ 995 NetCfg_PLG "Power Liftgate Module (1=present)";
CM_ SG_ 995 NetCfg_MSM_PASS "CAN I Memory Seat Module Passenger (1=present)";
CM_ SG_ 995 NetCfg_MSM "Memory Seat Module (1=present)";
CM_ SG_ 995 NetCfg_ITM "Intrusion module (1=present)";
CM_ SG_ 995 NetCfg_ICS_R "CAN I Integrated rear Center Stack Module (1=present)";
CM_ SG_ 995 NetCfg_ICS_I "CAN I Integrated Center Stack Module (1=present)";
CM_ SG_ 995 NetCfg_HVAC_R "CAN I Rear Heating Ventilation Air Conditioning (1=present)";
CM_ SG_ 995 NetCfg_HVAC "Heating Ventilation Air Conditioning (1=present)";
CM_ SG_ 995 NetCfg_HFM_CTM "Convergence Telematics Module (1=present)";
CM_ SG_ 995 NetCfg_FSM "Folding Seat Module (1=present)";
CM_ SG_ 995 NetCfg_DVD_CDM "CAN I in-dash disc player module (1=present)";
CM_ SG_ 995 NetCfg_DTV "Digital TV Module (1=present)";
CM_ SG_ 995 NetCfg_DCSD "Disassociated Center Stack Display Module (1=present)";
CM_ SG_ 995 NetCfg_DCM_RR "Door Control Module Rear Right (1=present)";
CM_ SG_ 995 NetCfg_DCM_RL "Door Control Module Rear Left (1=present)";
CM_ SG_ 995 NetCfg_DCM_PASS "Door Control Module Passenger (1=present)";
CM_ SG_ 995 NetCfg_DCM_DR "Door Control Module Driver (1=present)";
CM_ SG_ 995 NetCfg_CVPM "CAN I Central Vision Processing Module (1=present)";
CM_ SG_ 995 NetCfg_CSWM "Comfot Seats and Wheel Module (1=present)";
CM_ SG_ 995 NetCfg_CRSM "CAN I Comfort Rear Seat Module (1=present)";
CM_ SG_ 995 NetCfg_CLOCK "CAN I Clock Module (1=present)";
CM_ SG_ 995 NetCfg_CBC_IN "Common Body Controller Int Bus (1=present)";
CM_ SG_ 995 NetCfg_BSM "Blind-Spot Module (1=present)";
CM_ SG_ 995 NetCfg_ANC_I "Active Noise Cancellation interior (1=present)";
CM_ SG_ 995 NetCfg_AMP_I "CAN I Amplifier Module (1=present)";
CM_ SG_ 995 NET_CFG_STAT_INT "Network configuration status";
BA_DEF_ SG_  "GenSigTimeout_CBC" INT 0 65535;
BA_DEF_ SG_  "GenSigTimeout_EPS" INT 0 65535;
BA_DEF_ SG_  "GenSigTimeout_ESM" INT 0 65535;
BA_DEF_ SG_  "GenSigTimeout_ETM" INT 0 65535;
BA_DEF_ SG_  "GenSigTimeout_HaLF" INT 0 65535;
BA_DEF_ SG_  "GenSigTimeout_IC" INT 0 65535;
BA_DEF_ SG_  "GenSigTimeout_OCM" INT 0 65535;
BA_DEF_ SG_  "GenSigTimeout_ORC" INT 0 65535;
BA_DEF_ SG_  "GenSigTimeout_PTS" INT 0 65535;
BA_DEF_ SG_  "GenSigTimeout_RF_HUB" INT 0 65535;
BA_DEF_ SG_  "GenSigTimeout_SCCM" INT 0 65535;
BA_DEF_ BO_  "GenMsgStartValue" STRING ;
BA_DEF_ SG_  "GenSigSNA" STRING ;
BA_DEF_ SG_  "RID" STRING ;
BA_DEF_ SG_  "FlexKomIsMotorola" ENUM  "nein","ja";
BA_DEF_ SG_  "FlexKomSigLaenge" INT 0 64;
BA_DEF_ SG_  "FlexKomSigStartPos" INT 0 63;
BA_DEF_ SG_  "FlexKomComment" STRING ;
BA_DEF_ SG_  "FlexKomSigName" STRING ;
BA_DEF_ SG_  "FlexKomSID" INT 0 2147483647;
BA_DEF_ SG_  "GenSigStartValue" HEX 0 -1;
BA_DEF_ SG_  "FlexKomSigStartValue" STRING ;
BA_DEF_ SG_  "GenSigCycleTime" INT 0 65535;
BA_DEF_ SG_  "GenSigSendType" ENUM  "cyclicX","spontanX","cyclicIfActiveX","spontanWithDelay","cyclicAndSpontanX","cyclicAndSpontanWithDelay","spontanWithRepitition","cyclicIfActiveAndSpontanWD","cyclicIfActiveFast","cyclicWithRepeatOnDemand","none";
BA_DEF_ BO_  "GenMsgNrOfRepetitions" INT 0 65535;
BA_DEF_ BO_  "GenMsgDelayTime" INT 0 65535;
BA_DEF_ BO_  "GenMsgStartDelayTime" INT 0 65535;
BA_DEF_ BO_  "GenMsgCycleTime" INT 0 65535;
BA_DEF_ BO_  "GenMsgSendType" ENUM  "cyclicX","spontanX","cyclicIfActiveX","spontanWithDelay","cyclicAndSpontanX","cyclicAndSpontanWithDelay","spontanWithRepitition","cyclicIfActiveAndSpontanWD","cyclicIfActiveFast","cyclicWithRepeatOnDemand","none";
BA_DEF_ BO_  "DiagResponse" ENUM  "nein","ja";
BA_DEF_ BO_  "DiagRequest" ENUM  "nein","ja";
BA_DEF_ BO_  "DiagState" ENUM  "nein","ja";
BA_DEF_ BO_  "App-Botschaft" ENUM  "nein","ja";
BA_DEF_ BO_  "NWM-Botschaft" ENUM  "nein","ja";
BA_DEF_DEF_  "GenSigTimeout_CBC" 0;
BA_DEF_DEF_  "GenSigTimeout_EPS" 0;
BA_DEF_DEF_  "GenSigTimeout_ESM" 0;
BA_DEF_DEF_  "GenSigTimeout_ETM" 0;
BA_DEF_DEF_  "GenSigTimeout_HaLF" 0;
BA_DEF_DEF_  "GenSigTimeout_IC" 0;
BA_DEF_DEF_  "GenSigTimeout_OCM" 0;
BA_DEF_DEF_  "GenSigTimeout_ORC" 0;
BA_DEF_DEF_  "GenSigTimeout_PTS" 0;
BA_DEF_DEF_  "GenSigTimeout_RF_HUB" 0;
BA_DEF_DEF_  "GenSigTimeout_SCCM" 0;
BA_DEF_DEF_  "GenMsgStartValue" "";
BA_DEF_DEF_  "GenSigSNA" "";
BA_DEF_DEF_  "RID" "";
BA_DEF_DEF_  "FlexKomIsMotorola" "nein";
BA_DEF_DEF_  "FlexKomSigLaenge" 0;
BA_DEF_DEF_  "FlexKomSigStartPos" 0;
BA_DEF_DEF_  "FlexKomComment" "";
BA_DEF_DEF_  "FlexKomSigName" "";
BA_DEF_DEF_  "FlexKomSID" 0;
BA_DEF_DEF_  "GenSigStartValue" 0;
BA_DEF_DEF_  "FlexKomSigStartValue" "";
BA_DEF_DEF_  "GenSigCycleTime" 0;
BA_DEF_DEF_  "GenSigSendType" "cyclicX";
BA_DEF_DEF_  "GenMsgNrOfRepetitions" 0;
BA_DEF_DEF_  "GenMsgDelayTime" 0;
BA_DEF_DEF_  "GenMsgStartDelayTime" 0;
BA_DEF_DEF_  "GenMsgCycleTime" 0;
BA_DEF_DEF_  "GenMsgSendType" "cyclicX";
BA_DEF_DEF_  "DiagResponse" "nein";
BA_DEF_DEF_  "DiagRequest" "nein";
BA_DEF_DEF_  "DiagState" "nein";
BA_DEF_DEF_  "App-Botschaft" "nein";
BA_DEF_DEF_  "NWM-Botschaft" "nein";
BA_ "GenMsgStartValue" BO_ 1026 "FFFFFFFF000000FFh";
BA_ "GenMsgNrOfRepetitions" BO_ 1026 2;
BA_ "GenMsgDelayTime" BO_ 1026 20;
BA_ "NWM-Botschaft" BO_ 1026 1;
BA_ "GenSigSNA" SG_ 1026 WakeupRsn_IC "FFh";
BA_ "FlexKomIsMotorola" SG_ 1026 WakeupRsn_IC 1;
BA_ "FlexKomComment" SG_ 1026 WakeupRsn_IC "Mode 2 of NM_Ud_Srv";
BA_ "FlexKomSigName" SG_ 1026 WakeupRsn_IC "Wakeup_IC";
BA_ "FlexKomSigLaenge" SG_ 1026 WakeupRsn_IC 24;
BA_ "FlexKomSigStartPos" SG_ 1026 WakeupRsn_IC 39;
BA_ "FlexKomSID" SG_ 1026 WakeupRsn_IC 482;
BA_ "GenSigStartValue" SG_ 1026 WakeupRsn_IC 255;
BA_ "FlexKomSigStartValue" SG_ 1026 WakeupRsn_IC "FFFF00h";
BA_ "GenSigSNA" SG_ 1026 WakeupCnt_IC "FFh";
BA_ "FlexKomIsMotorola" SG_ 1026 WakeupCnt_IC 1;
BA_ "FlexKomComment" SG_ 1026 WakeupCnt_IC "Mode 2 of NM_Ud_Srv";
BA_ "FlexKomSigName" SG_ 1026 WakeupCnt_IC "Wakeup_IC";
BA_ "FlexKomSigLaenge" SG_ 1026 WakeupCnt_IC 24;
BA_ "FlexKomSigStartPos" SG_ 1026 WakeupCnt_IC 39;
BA_ "FlexKomSID" SG_ 1026 WakeupCnt_IC 482;
BA_ "GenSigStartValue" SG_ 1026 WakeupCnt_IC 255;
BA_ "FlexKomSigStartValue" SG_ 1026 WakeupCnt_IC "FFFF00h";
BA_ "GenSigSNA" SG_ 1026 Nw_Id_IC "FFh";
BA_ "FlexKomIsMotorola" SG_ 1026 Nw_Id_IC 1;
BA_ "FlexKomComment" SG_ 1026 Nw_Id_IC "Network identification no.";
BA_ "FlexKomSigName" SG_ 1026 Nw_Id_IC "Nw_Id";
BA_ "FlexKomSigLaenge" SG_ 1026 Nw_Id_IC 8;
BA_ "FlexKomSigStartPos" SG_ 1026 Nw_Id_IC 63;
BA_ "FlexKomSID" SG_ 1026 Nw_Id_IC 535;
BA_ "GenSigStartValue" SG_ 1026 Nw_Id_IC 255;
BA_ "FlexKomSigStartValue" SG_ 1026 Nw_Id_IC "FFh";
BA_ "GenSigSNA" SG_ 1026 NM_Ud_Srv_IC "FFh";
BA_ "FlexKomIsMotorola" SG_ 1026 NM_Ud_Srv_IC 1;
BA_ "FlexKomComment" SG_ 1026 NM_Ud_Srv_IC "Network management state";
BA_ "FlexKomSigName" SG_ 1026 NM_Ud_Srv_IC "NM";
BA_ "FlexKomSigLaenge" SG_ 1026 NM_Ud_Srv_IC 32;
BA_ "FlexKomSigStartPos" SG_ 1026 NM_Ud_Srv_IC 7;
BA_ "FlexKomSID" SG_ 1026 NM_Ud_Srv_IC 472;
BA_ "GenSigStartValue" SG_ 1026 NM_Ud_Srv_IC 255;
BA_ "FlexKomSigStartValue" SG_ 1026 NM_Ud_Srv_IC "FFFFFFFFh";
BA_ "GenSigSNA" SG_ 1026 NM_Ud_Launch_IC "3Fh";
BA_ "FlexKomIsMotorola" SG_ 1026 NM_Ud_Launch_IC 1;
BA_ "FlexKomComment" SG_ 1026 NM_Ud_Launch_IC "Network management state";
BA_ "FlexKomSigName" SG_ 1026 NM_Ud_Launch_IC "NM";
BA_ "FlexKomSigLaenge" SG_ 1026 NM_Ud_Launch_IC 32;
BA_ "FlexKomSigStartPos" SG_ 1026 NM_Ud_Launch_IC 7;
BA_ "FlexKomSID" SG_ 1026 NM_Ud_Launch_IC 472;
BA_ "GenSigStartValue" SG_ 1026 NM_Ud_Launch_IC 63;
BA_ "FlexKomSigStartValue" SG_ 1026 NM_Ud_Launch_IC "FFFFFFFFh";
BA_ "GenSigSNA" SG_ 1026 NM_Successor_IC "FFh";
BA_ "FlexKomIsMotorola" SG_ 1026 NM_Successor_IC 1;
BA_ "FlexKomComment" SG_ 1026 NM_Successor_IC "Network management state";
BA_ "FlexKomSigName" SG_ 1026 NM_Successor_IC "NM";
BA_ "FlexKomSigLaenge" SG_ 1026 NM_Successor_IC 32;
BA_ "FlexKomSigStartPos" SG_ 1026 NM_Successor_IC 7;
BA_ "FlexKomSID" SG_ 1026 NM_Successor_IC 472;
BA_ "GenSigStartValue" SG_ 1026 NM_Successor_IC 255;
BA_ "FlexKomSigStartValue" SG_ 1026 NM_Successor_IC "FFFFFFFFh";
BA_ "GenSigSNA" SG_ 1026 NM_Sleep_Ind_IC "1h";
BA_ "FlexKomIsMotorola" SG_ 1026 NM_Sleep_Ind_IC 1;
BA_ "FlexKomComment" SG_ 1026 NM_Sleep_Ind_IC "Network management state";
BA_ "FlexKomSigName" SG_ 1026 NM_Sleep_Ind_IC "NM";
BA_ "FlexKomSigLaenge" SG_ 1026 NM_Sleep_Ind_IC 32;
BA_ "FlexKomSigStartPos" SG_ 1026 NM_Sleep_Ind_IC 7;
BA_ "FlexKomSID" SG_ 1026 NM_Sleep_Ind_IC 472;
BA_ "GenSigStartValue" SG_ 1026 NM_Sleep_Ind_IC 1;
BA_ "FlexKomSigStartValue" SG_ 1026 NM_Sleep_Ind_IC "FFFFFFFFh";
BA_ "GenSigSNA" SG_ 1026 NM_Sleep_Ack_IC "1h";
BA_ "FlexKomIsMotorola" SG_ 1026 NM_Sleep_Ack_IC 1;
BA_ "FlexKomComment" SG_ 1026 NM_Sleep_Ack_IC "Network management state";
BA_ "FlexKomSigName" SG_ 1026 NM_Sleep_Ack_IC "NM";
BA_ "FlexKomSigLaenge" SG_ 1026 NM_Sleep_Ack_IC 32;
BA_ "FlexKomSigStartPos" SG_ 1026 NM_Sleep_Ack_IC 7;
BA_ "FlexKomSID" SG_ 1026 NM_Sleep_Ack_IC 472;
BA_ "GenSigStartValue" SG_ 1026 NM_Sleep_Ack_IC 1;
BA_ "FlexKomSigStartValue" SG_ 1026 NM_Sleep_Ack_IC "FFFFFFFFh";
BA_ "GenSigSNA" SG_ 1026 NM_Mode_IC "FFh";
BA_ "FlexKomIsMotorola" SG_ 1026 NM_Mode_IC 1;
BA_ "FlexKomComment" SG_ 1026 NM_Mode_IC "Network management state";
BA_ "FlexKomSigName" SG_ 1026 NM_Mode_IC "NM";
BA_ "FlexKomSigLaenge" SG_ 1026 NM_Mode_IC 32;
BA_ "FlexKomSigStartPos" SG_ 1026 NM_Mode_IC 7;
BA_ "FlexKomSID" SG_ 1026 NM_Mode_IC 472;
BA_ "GenSigStartValue" SG_ 1026 NM_Mode_IC 255;
BA_ "FlexKomSigStartValue" SG_ 1026 NM_Mode_IC "FFFFFFFFh";
BA_ "GenSigSNA" SG_ 1026 Awake_NwSt_IC "0h";
BA_ "FlexKomIsMotorola" SG_ 1026 Awake_NwSt_IC 1;
BA_ "FlexKomComment" SG_ 1026 Awake_NwSt_IC "Mode 15 of NM_Ud_Srv";
BA_ "FlexKomSigName" SG_ 1026 Awake_NwSt_IC "Awake_IC";
BA_ "FlexKomSigLaenge" SG_ 1026 Awake_NwSt_IC 24;
BA_ "FlexKomSigStartPos" SG_ 1026 Awake_NwSt_IC 39;
BA_ "FlexKomSID" SG_ 1026 Awake_NwSt_IC 512;
BA_ "FlexKomSigStartValue" SG_ 1026 Awake_NwSt_IC "000000h";
BA_ "GenSigSNA" SG_ 1026 Awake_Diag_Actv_IC "0h";
BA_ "FlexKomIsMotorola" SG_ 1026 Awake_Diag_Actv_IC 1;
BA_ "FlexKomComment" SG_ 1026 Awake_Diag_Actv_IC "Mode 15 of NM_Ud_Srv";
BA_ "FlexKomSigName" SG_ 1026 Awake_Diag_Actv_IC "Awake_IC";
BA_ "FlexKomSigLaenge" SG_ 1026 Awake_Diag_Actv_IC 24;
BA_ "FlexKomSigStartPos" SG_ 1026 Awake_Diag_Actv_IC 39;
BA_ "FlexKomSID" SG_ 1026 Awake_Diag_Actv_IC 512;
BA_ "FlexKomSigStartValue" SG_ 1026 Awake_Diag_Actv_IC "000000h";
BA_ "GenMsgStartValue" BO_ 1025 "FFFFFFFF000000FFh";
BA_ "GenMsgNrOfRepetitions" BO_ 1025 2;
BA_ "GenMsgDelayTime" BO_ 1025 20;
BA_ "NWM-Botschaft" BO_ 1025 1;
BA_ "GenSigSNA" SG_ 1025 WakeupRsn_CBC "FFh";
BA_ "FlexKomIsMotorola" SG_ 1025 WakeupRsn_CBC 1;
BA_ "FlexKomComment" SG_ 1025 WakeupRsn_CBC "Mode 2 of NM_Ud_Srv";
BA_ "FlexKomSigName" SG_ 1025 WakeupRsn_CBC "Wakeup_CBC";
BA_ "FlexKomSigLaenge" SG_ 1025 WakeupRsn_CBC 24;
BA_ "FlexKomSigStartPos" SG_ 1025 WakeupRsn_CBC 39;
BA_ "FlexKomSID" SG_ 1025 WakeupRsn_CBC 474;
BA_ "GenSigStartValue" SG_ 1025 WakeupRsn_CBC 255;
BA_ "FlexKomSigStartValue" SG_ 1025 WakeupRsn_CBC "FFFF00h";
BA_ "GenSigSNA" SG_ 1025 WakeupCnt_CBC "FFh";
BA_ "FlexKomIsMotorola" SG_ 1025 WakeupCnt_CBC 1;
BA_ "FlexKomComment" SG_ 1025 WakeupCnt_CBC "Mode 2 of NM_Ud_Srv";
BA_ "FlexKomSigName" SG_ 1025 WakeupCnt_CBC "Wakeup_CBC";
BA_ "FlexKomSigLaenge" SG_ 1025 WakeupCnt_CBC 24;
BA_ "FlexKomSigStartPos" SG_ 1025 WakeupCnt_CBC 39;
BA_ "FlexKomSID" SG_ 1025 WakeupCnt_CBC 474;
BA_ "GenSigStartValue" SG_ 1025 WakeupCnt_CBC 255;
BA_ "FlexKomSigStartValue" SG_ 1025 WakeupCnt_CBC "FFFF00h";
BA_ "GenSigSNA" SG_ 1025 Nw_Id_CBC "FFh";
BA_ "FlexKomIsMotorola" SG_ 1025 Nw_Id_CBC 1;
BA_ "FlexKomComment" SG_ 1025 Nw_Id_CBC "Network identification no.";
BA_ "FlexKomSigName" SG_ 1025 Nw_Id_CBC "Nw_Id";
BA_ "FlexKomSigLaenge" SG_ 1025 Nw_Id_CBC 8;
BA_ "FlexKomSigStartPos" SG_ 1025 Nw_Id_CBC 63;
BA_ "FlexKomSID" SG_ 1025 Nw_Id_CBC 535;
BA_ "GenSigStartValue" SG_ 1025 Nw_Id_CBC 255;
BA_ "FlexKomSigStartValue" SG_ 1025 Nw_Id_CBC "FFh";
BA_ "GenSigSNA" SG_ 1025 NM_Ud_Srv_CBC "FFh";
BA_ "FlexKomIsMotorola" SG_ 1025 NM_Ud_Srv_CBC 1;
BA_ "FlexKomComment" SG_ 1025 NM_Ud_Srv_CBC "Network management state";
BA_ "FlexKomSigName" SG_ 1025 NM_Ud_Srv_CBC "NM";
BA_ "FlexKomSigLaenge" SG_ 1025 NM_Ud_Srv_CBC 32;
BA_ "FlexKomSigStartPos" SG_ 1025 NM_Ud_Srv_CBC 7;
BA_ "FlexKomSID" SG_ 1025 NM_Ud_Srv_CBC 472;
BA_ "GenSigStartValue" SG_ 1025 NM_Ud_Srv_CBC 255;
BA_ "FlexKomSigStartValue" SG_ 1025 NM_Ud_Srv_CBC "FFFFFFFFh";
BA_ "GenSigSNA" SG_ 1025 NM_Ud_Launch_CBC "3Fh";
BA_ "FlexKomIsMotorola" SG_ 1025 NM_Ud_Launch_CBC 1;
BA_ "FlexKomComment" SG_ 1025 NM_Ud_Launch_CBC "Network management state";
BA_ "FlexKomSigName" SG_ 1025 NM_Ud_Launch_CBC "NM";
BA_ "FlexKomSigLaenge" SG_ 1025 NM_Ud_Launch_CBC 32;
BA_ "FlexKomSigStartPos" SG_ 1025 NM_Ud_Launch_CBC 7;
BA_ "FlexKomSID" SG_ 1025 NM_Ud_Launch_CBC 472;
BA_ "GenSigStartValue" SG_ 1025 NM_Ud_Launch_CBC 63;
BA_ "FlexKomSigStartValue" SG_ 1025 NM_Ud_Launch_CBC "FFFFFFFFh";
BA_ "GenSigSNA" SG_ 1025 NM_Successor_CBC "FFh";
BA_ "FlexKomIsMotorola" SG_ 1025 NM_Successor_CBC 1;
BA_ "FlexKomComment" SG_ 1025 NM_Successor_CBC "Network management state";
BA_ "FlexKomSigName" SG_ 1025 NM_Successor_CBC "NM";
BA_ "FlexKomSigLaenge" SG_ 1025 NM_Successor_CBC 32;
BA_ "FlexKomSigStartPos" SG_ 1025 NM_Successor_CBC 7;
BA_ "FlexKomSID" SG_ 1025 NM_Successor_CBC 472;
BA_ "GenSigStartValue" SG_ 1025 NM_Successor_CBC 255;
BA_ "FlexKomSigStartValue" SG_ 1025 NM_Successor_CBC "FFFFFFFFh";
BA_ "GenSigSNA" SG_ 1025 NM_Sleep_Ind_CBC "1h";
BA_ "FlexKomIsMotorola" SG_ 1025 NM_Sleep_Ind_CBC 1;
BA_ "FlexKomComment" SG_ 1025 NM_Sleep_Ind_CBC "Network management state";
BA_ "FlexKomSigName" SG_ 1025 NM_Sleep_Ind_CBC "NM";
BA_ "FlexKomSigLaenge" SG_ 1025 NM_Sleep_Ind_CBC 32;
BA_ "FlexKomSigStartPos" SG_ 1025 NM_Sleep_Ind_CBC 7;
BA_ "FlexKomSID" SG_ 1025 NM_Sleep_Ind_CBC 472;
BA_ "GenSigStartValue" SG_ 1025 NM_Sleep_Ind_CBC 1;
BA_ "FlexKomSigStartValue" SG_ 1025 NM_Sleep_Ind_CBC "FFFFFFFFh";
BA_ "GenSigSNA" SG_ 1025 NM_Sleep_Ack_CBC "1h";
BA_ "FlexKomIsMotorola" SG_ 1025 NM_Sleep_Ack_CBC 1;
BA_ "FlexKomComment" SG_ 1025 NM_Sleep_Ack_CBC "Network management state";
BA_ "FlexKomSigName" SG_ 1025 NM_Sleep_Ack_CBC "NM";
BA_ "FlexKomSigLaenge" SG_ 1025 NM_Sleep_Ack_CBC 32;
BA_ "FlexKomSigStartPos" SG_ 1025 NM_Sleep_Ack_CBC 7;
BA_ "FlexKomSID" SG_ 1025 NM_Sleep_Ack_CBC 472;
BA_ "GenSigStartValue" SG_ 1025 NM_Sleep_Ack_CBC 1;
BA_ "FlexKomSigStartValue" SG_ 1025 NM_Sleep_Ack_CBC "FFFFFFFFh";
BA_ "GenSigSNA" SG_ 1025 NM_Mode_CBC "FFh";
BA_ "FlexKomIsMotorola" SG_ 1025 NM_Mode_CBC 1;
BA_ "FlexKomComment" SG_ 1025 NM_Mode_CBC "Network management state";
BA_ "FlexKomSigName" SG_ 1025 NM_Mode_CBC "NM";
BA_ "FlexKomSigLaenge" SG_ 1025 NM_Mode_CBC 32;
BA_ "FlexKomSigStartPos" SG_ 1025 NM_Mode_CBC 7;
BA_ "FlexKomSID" SG_ 1025 NM_Mode_CBC 472;
BA_ "GenSigStartValue" SG_ 1025 NM_Mode_CBC 255;
BA_ "FlexKomSigStartValue" SG_ 1025 NM_Mode_CBC "FFFFFFFFh";
BA_ "GenSigSNA" SG_ 1025 Awake_NwSt_CBC "0h";
BA_ "FlexKomIsMotorola" SG_ 1025 Awake_NwSt_CBC 1;
BA_ "FlexKomComment" SG_ 1025 Awake_NwSt_CBC "Mode 15 of NM_Ud_Srv";
BA_ "FlexKomSigName" SG_ 1025 Awake_NwSt_CBC "Awake_CBC";
BA_ "FlexKomSigLaenge" SG_ 1025 Awake_NwSt_CBC 24;
BA_ "FlexKomSigStartPos" SG_ 1025 Awake_NwSt_CBC 39;
BA_ "FlexKomSID" SG_ 1025 Awake_NwSt_CBC 504;
BA_ "FlexKomSigStartValue" SG_ 1025 Awake_NwSt_CBC "000000h";
BA_ "GenSigSNA" SG_ 1025 Awake_Diag_Actv_CBC "0h";
BA_ "FlexKomIsMotorola" SG_ 1025 Awake_Diag_Actv_CBC 1;
BA_ "FlexKomComment" SG_ 1025 Awake_Diag_Actv_CBC "Mode 15 of NM_Ud_Srv";
BA_ "FlexKomSigName" SG_ 1025 Awake_Diag_Actv_CBC "Awake_CBC";
BA_ "FlexKomSigLaenge" SG_ 1025 Awake_Diag_Actv_CBC 24;
BA_ "FlexKomSigStartPos" SG_ 1025 Awake_Diag_Actv_CBC 39;
BA_ "FlexKomSID" SG_ 1025 Awake_Diag_Actv_CBC 504;
BA_ "FlexKomSigStartValue" SG_ 1025 Awake_Diag_Actv_CBC "000000h";
BA_ "GenMsgStartValue" BO_ 1024 "FFFFFFFF000000FFh";
BA_ "GenMsgNrOfRepetitions" BO_ 1024 2;
BA_ "GenMsgDelayTime" BO_ 1024 20;
BA_ "NWM-Botschaft" BO_ 1024 1;
BA_ "GenSigSNA" SG_ 1024 WakeupRsn_RF_HUB "FFh";
BA_ "FlexKomIsMotorola" SG_ 1024 WakeupRsn_RF_HUB 1;
BA_ "FlexKomComment" SG_ 1024 WakeupRsn_RF_HUB "Mode 2 of NM_Ud_Srv";
BA_ "FlexKomSigName" SG_ 1024 WakeupRsn_RF_HUB "Wakeup_RF_HUB";
BA_ "FlexKomSigLaenge" SG_ 1024 WakeupRsn_RF_HUB 24;
BA_ "FlexKomSigStartPos" SG_ 1024 WakeupRsn_RF_HUB 39;
BA_ "FlexKomSID" SG_ 1024 WakeupRsn_RF_HUB 620;
BA_ "GenSigStartValue" SG_ 1024 WakeupRsn_RF_HUB 255;
BA_ "FlexKomSigStartValue" SG_ 1024 WakeupRsn_RF_HUB "FFFF00h";
BA_ "GenSigSNA" SG_ 1024 WakeupCnt_RF_HUB "FFh";
BA_ "FlexKomIsMotorola" SG_ 1024 WakeupCnt_RF_HUB 1;
BA_ "FlexKomComment" SG_ 1024 WakeupCnt_RF_HUB "Mode 2 of NM_Ud_Srv";
BA_ "FlexKomSigName" SG_ 1024 WakeupCnt_RF_HUB "Wakeup_RF_HUB";
BA_ "FlexKomSigLaenge" SG_ 1024 WakeupCnt_RF_HUB 24;
BA_ "FlexKomSigStartPos" SG_ 1024 WakeupCnt_RF_HUB 39;
BA_ "FlexKomSID" SG_ 1024 WakeupCnt_RF_HUB 620;
BA_ "GenSigStartValue" SG_ 1024 WakeupCnt_RF_HUB 255;
BA_ "FlexKomSigStartValue" SG_ 1024 WakeupCnt_RF_HUB "FFFF00h";
BA_ "GenSigSNA" SG_ 1024 Nw_Id_RF_HUB "FFh";
BA_ "FlexKomIsMotorola" SG_ 1024 Nw_Id_RF_HUB 1;
BA_ "FlexKomComment" SG_ 1024 Nw_Id_RF_HUB "Network identification no.";
BA_ "FlexKomSigName" SG_ 1024 Nw_Id_RF_HUB "Nw_Id";
BA_ "FlexKomSigLaenge" SG_ 1024 Nw_Id_RF_HUB 8;
BA_ "FlexKomSigStartPos" SG_ 1024 Nw_Id_RF_HUB 63;
BA_ "FlexKomSID" SG_ 1024 Nw_Id_RF_HUB 535;
BA_ "GenSigStartValue" SG_ 1024 Nw_Id_RF_HUB 255;
BA_ "FlexKomSigStartValue" SG_ 1024 Nw_Id_RF_HUB "FFh";
BA_ "GenSigSNA" SG_ 1024 NM_Ud_Srv_RF_HUB "FFh";
BA_ "FlexKomIsMotorola" SG_ 1024 NM_Ud_Srv_RF_HUB 1;
BA_ "FlexKomComment" SG_ 1024 NM_Ud_Srv_RF_HUB "Network management state";
BA_ "FlexKomSigName" SG_ 1024 NM_Ud_Srv_RF_HUB "NM";
BA_ "FlexKomSigLaenge" SG_ 1024 NM_Ud_Srv_RF_HUB 32;
BA_ "FlexKomSigStartPos" SG_ 1024 NM_Ud_Srv_RF_HUB 7;
BA_ "FlexKomSID" SG_ 1024 NM_Ud_Srv_RF_HUB 472;
BA_ "GenSigStartValue" SG_ 1024 NM_Ud_Srv_RF_HUB 255;
BA_ "FlexKomSigStartValue" SG_ 1024 NM_Ud_Srv_RF_HUB "FFFFFFFFh";
BA_ "GenSigSNA" SG_ 1024 NM_Ud_Launch_RF_HUB "3Fh";
BA_ "FlexKomIsMotorola" SG_ 1024 NM_Ud_Launch_RF_HUB 1;
BA_ "FlexKomComment" SG_ 1024 NM_Ud_Launch_RF_HUB "Network management state";
BA_ "FlexKomSigName" SG_ 1024 NM_Ud_Launch_RF_HUB "NM";
BA_ "FlexKomSigLaenge" SG_ 1024 NM_Ud_Launch_RF_HUB 32;
BA_ "FlexKomSigStartPos" SG_ 1024 NM_Ud_Launch_RF_HUB 7;
BA_ "FlexKomSID" SG_ 1024 NM_Ud_Launch_RF_HUB 472;
BA_ "GenSigStartValue" SG_ 1024 NM_Ud_Launch_RF_HUB 63;
BA_ "FlexKomSigStartValue" SG_ 1024 NM_Ud_Launch_RF_HUB "FFFFFFFFh";
BA_ "GenSigSNA" SG_ 1024 NM_Successor_RF_HUB "FFh";
BA_ "FlexKomIsMotorola" SG_ 1024 NM_Successor_RF_HUB 1;
BA_ "FlexKomComment" SG_ 1024 NM_Successor_RF_HUB "Network management state";
BA_ "FlexKomSigName" SG_ 1024 NM_Successor_RF_HUB "NM";
BA_ "FlexKomSigLaenge" SG_ 1024 NM_Successor_RF_HUB 32;
BA_ "FlexKomSigStartPos" SG_ 1024 NM_Successor_RF_HUB 7;
BA_ "FlexKomSID" SG_ 1024 NM_Successor_RF_HUB 472;
BA_ "GenSigStartValue" SG_ 1024 NM_Successor_RF_HUB 255;
BA_ "FlexKomSigStartValue" SG_ 1024 NM_Successor_RF_HUB "FFFFFFFFh";
BA_ "GenSigSNA" SG_ 1024 NM_Sleep_Ind_RF_HUB "1h";
BA_ "FlexKomIsMotorola" SG_ 1024 NM_Sleep_Ind_RF_HUB 1;
BA_ "FlexKomComment" SG_ 1024 NM_Sleep_Ind_RF_HUB "Network management state";
BA_ "FlexKomSigName" SG_ 1024 NM_Sleep_Ind_RF_HUB "NM";
BA_ "FlexKomSigLaenge" SG_ 1024 NM_Sleep_Ind_RF_HUB 32;
BA_ "FlexKomSigStartPos" SG_ 1024 NM_Sleep_Ind_RF_HUB 7;
BA_ "FlexKomSID" SG_ 1024 NM_Sleep_Ind_RF_HUB 472;
BA_ "GenSigStartValue" SG_ 1024 NM_Sleep_Ind_RF_HUB 1;
BA_ "FlexKomSigStartValue" SG_ 1024 NM_Sleep_Ind_RF_HUB "FFFFFFFFh";
BA_ "GenSigSNA" SG_ 1024 NM_Sleep_Ack_RF_HUB "1h";
BA_ "FlexKomIsMotorola" SG_ 1024 NM_Sleep_Ack_RF_HUB 1;
BA_ "FlexKomComment" SG_ 1024 NM_Sleep_Ack_RF_HUB "Network management state";
BA_ "FlexKomSigName" SG_ 1024 NM_Sleep_Ack_RF_HUB "NM";
BA_ "FlexKomSigLaenge" SG_ 1024 NM_Sleep_Ack_RF_HUB 32;
BA_ "FlexKomSigStartPos" SG_ 1024 NM_Sleep_Ack_RF_HUB 7;
BA_ "FlexKomSID" SG_ 1024 NM_Sleep_Ack_RF_HUB 472;
BA_ "GenSigStartValue" SG_ 1024 NM_Sleep_Ack_RF_HUB 1;
BA_ "FlexKomSigStartValue" SG_ 1024 NM_Sleep_Ack_RF_HUB "FFFFFFFFh";
BA_ "GenSigSNA" SG_ 1024 NM_Mode_RF_HUB "FFh";
BA_ "FlexKomIsMotorola" SG_ 1024 NM_Mode_RF_HUB 1;
BA_ "FlexKomComment" SG_ 1024 NM_Mode_RF_HUB "Network management state";
BA_ "FlexKomSigName" SG_ 1024 NM_Mode_RF_HUB "NM";
BA_ "FlexKomSigLaenge" SG_ 1024 NM_Mode_RF_HUB 32;
BA_ "FlexKomSigStartPos" SG_ 1024 NM_Mode_RF_HUB 7;
BA_ "FlexKomSID" SG_ 1024 NM_Mode_RF_HUB 472;
BA_ "GenSigStartValue" SG_ 1024 NM_Mode_RF_HUB 255;
BA_ "FlexKomSigStartValue" SG_ 1024 NM_Mode_RF_HUB "FFFFFFFFh";
BA_ "GenSigSNA" SG_ 1024 Awake_NwSt_RF_HUB "0h";
BA_ "FlexKomIsMotorola" SG_ 1024 Awake_NwSt_RF_HUB 1;
BA_ "FlexKomComment" SG_ 1024 Awake_NwSt_RF_HUB "Mode 15 of NM_Ud_Srv";
BA_ "FlexKomSigName" SG_ 1024 Awake_NwSt_RF_HUB "Awake_RF_HUB";
BA_ "FlexKomSigLaenge" SG_ 1024 Awake_NwSt_RF_HUB 24;
BA_ "FlexKomSigStartPos" SG_ 1024 Awake_NwSt_RF_HUB 39;
BA_ "FlexKomSID" SG_ 1024 Awake_NwSt_RF_HUB 619;
BA_ "FlexKomSigStartValue" SG_ 1024 Awake_NwSt_RF_HUB "000000h";
BA_ "GenSigSNA" SG_ 1024 Awake_Diag_Actv_RF_HUB "0h";
BA_ "FlexKomIsMotorola" SG_ 1024 Awake_Diag_Actv_RF_HUB 1;
BA_ "FlexKomComment" SG_ 1024 Awake_Diag_Actv_RF_HUB "Mode 15 of NM_Ud_Srv";
BA_ "FlexKomSigName" SG_ 1024 Awake_Diag_Actv_RF_HUB "Awake_RF_HUB";
BA_ "FlexKomSigLaenge" SG_ 1024 Awake_Diag_Actv_RF_HUB 24;
BA_ "FlexKomSigStartPos" SG_ 1024 Awake_Diag_Actv_RF_HUB 39;
BA_ "FlexKomSID" SG_ 1024 Awake_Diag_Actv_RF_HUB 619;
BA_ "FlexKomSigStartValue" SG_ 1024 Awake_Diag_Actv_RF_HUB "000000h";
BA_ "GenMsgStartDelayTime" BO_ 1015 80;
BA_ "GenMsgStartValue" BO_ 1015 "0300000000000000h";
BA_ "GenMsgNrOfRepetitions" BO_ 1015 2;
BA_ "GenMsgDelayTime" BO_ 1015 20;
BA_ "GenMsgCycleTime" BO_ 1015 2000;
BA_ "GenSigSNA" SG_ 1015 EC_ECUCfg8_Stat "3h";
BA_ "FlexKomIsMotorola" SG_ 1015 EC_ECUCfg8_Stat 1;
BA_ "FlexKomComment" SG_ 1015 EC_ECUCfg8_Stat "ECU Configuration messages status 8";
BA_ "FlexKomSigName" SG_ 1015 EC_ECUCfg8_Stat "EC_ECUCfg8_Stat";
BA_ "FlexKomSigLaenge" SG_ 1015 EC_ECUCfg8_Stat 2;
BA_ "FlexKomSigStartPos" SG_ 1015 EC_ECUCfg8_Stat 1;
BA_ "FlexKomSID" SG_ 1015 EC_ECUCfg8_Stat 1101;
BA_ "GenSigStartValue" SG_ 1015 EC_ECUCfg8_Stat 3;
BA_ "FlexKomSigStartValue" SG_ 1015 EC_ECUCfg8_Stat "03h";
BA_ "GenSigCycleTime" SG_ 1015 EC_ECUCfg8_Stat 2000;
BA_ "GenSigSNA" SG_ 1015 EC_CBC8 "0h";
BA_ "FlexKomIsMotorola" SG_ 1015 EC_CBC8 1;
BA_ "FlexKomComment" SG_ 1015 EC_CBC8 "CBC ecu configuration 8";
BA_ "FlexKomSigName" SG_ 1015 EC_CBC8 "EC_CBC8";
BA_ "FlexKomSigLaenge" SG_ 1015 EC_CBC8 32;
BA_ "FlexKomSigStartPos" SG_ 1015 EC_CBC8 39;
BA_ "FlexKomSID" SG_ 1015 EC_CBC8 1104;
BA_ "FlexKomSigStartValue" SG_ 1015 EC_CBC8 "00000000h";
BA_ "GenSigCycleTime" SG_ 1015 EC_CBC8 2000;
BA_ "GenSigSNA" SG_ 1015 EC_CBC7B "0h";
BA_ "FlexKomIsMotorola" SG_ 1015 EC_CBC7B 1;
BA_ "FlexKomComment" SG_ 1015 EC_CBC7B "CBC ecu configuration 7";
BA_ "FlexKomSigName" SG_ 1015 EC_CBC7B "EC_CBC7";
BA_ "FlexKomSigLaenge" SG_ 1015 EC_CBC7B 32;
BA_ "FlexKomSigStartPos" SG_ 1015 EC_CBC7B 7;
BA_ "FlexKomSID" SG_ 1015 EC_CBC7B 1106;
BA_ "FlexKomSigStartValue" SG_ 1015 EC_CBC7B "00000000h";
BA_ "GenSigCycleTime" SG_ 1015 EC_CBC7B 2000;
BA_ "GenSigSNA" SG_ 1015 EC_CBC7A "0h";
BA_ "FlexKomIsMotorola" SG_ 1015 EC_CBC7A 1;
BA_ "FlexKomComment" SG_ 1015 EC_CBC7A "CBC ecu configuration 7";
BA_ "FlexKomSigName" SG_ 1015 EC_CBC7A "EC_CBC7";
BA_ "FlexKomSigLaenge" SG_ 1015 EC_CBC7A 32;
BA_ "FlexKomSigStartPos" SG_ 1015 EC_CBC7A 7;
BA_ "FlexKomSID" SG_ 1015 EC_CBC7A 1106;
BA_ "FlexKomSigStartValue" SG_ 1015 EC_CBC7A "00000000h";
BA_ "GenSigCycleTime" SG_ 1015 EC_CBC7A 2000;
BA_ "GenMsgStartDelayTime" BO_ 1014 150;
BA_ "GenMsgStartValue" BO_ 1014 "0300000000000000h";
BA_ "GenMsgNrOfRepetitions" BO_ 1014 2;
BA_ "GenMsgDelayTime" BO_ 1014 20;
BA_ "GenMsgCycleTime" BO_ 1014 2000;
BA_ "GenSigSNA" SG_ 1014 EC_ECUCfg7_Stat "3h";
BA_ "FlexKomIsMotorola" SG_ 1014 EC_ECUCfg7_Stat 1;
BA_ "FlexKomComment" SG_ 1014 EC_ECUCfg7_Stat "ECU Configuration messages status 7";
BA_ "FlexKomSigName" SG_ 1014 EC_ECUCfg7_Stat "EC_ECUCfg7_Stat";
BA_ "FlexKomSigLaenge" SG_ 1014 EC_ECUCfg7_Stat 2;
BA_ "FlexKomSigStartPos" SG_ 1014 EC_ECUCfg7_Stat 1;
BA_ "FlexKomSID" SG_ 1014 EC_ECUCfg7_Stat 1102;
BA_ "GenSigStartValue" SG_ 1014 EC_ECUCfg7_Stat 3;
BA_ "FlexKomSigStartValue" SG_ 1014 EC_ECUCfg7_Stat "03h";
BA_ "GenSigCycleTime" SG_ 1014 EC_ECUCfg7_Stat 2000;
BA_ "GenSigSNA" SG_ 1014 EC_CBC6 "0h";
BA_ "FlexKomIsMotorola" SG_ 1014 EC_CBC6 1;
BA_ "FlexKomComment" SG_ 1014 EC_CBC6 "CBC ecu configuration 6";
BA_ "FlexKomSigName" SG_ 1014 EC_CBC6 "EC_CBC6";
BA_ "FlexKomSigLaenge" SG_ 1014 EC_CBC6 32;
BA_ "FlexKomSigStartPos" SG_ 1014 EC_CBC6 39;
BA_ "FlexKomSID" SG_ 1014 EC_CBC6 1103;
BA_ "FlexKomSigStartValue" SG_ 1014 EC_CBC6 "00000000h";
BA_ "GenSigCycleTime" SG_ 1014 EC_CBC6 2000;
BA_ "GenSigSNA" SG_ 1014 EC_CBC5B "0h";
BA_ "FlexKomIsMotorola" SG_ 1014 EC_CBC5B 1;
BA_ "FlexKomComment" SG_ 1014 EC_CBC5B "CBC ecu configuration 5";
BA_ "FlexKomSigName" SG_ 1014 EC_CBC5B "EC_CBC5";
BA_ "FlexKomSigLaenge" SG_ 1014 EC_CBC5B 32;
BA_ "FlexKomSigStartPos" SG_ 1014 EC_CBC5B 7;
BA_ "FlexKomSID" SG_ 1014 EC_CBC5B 1105;
BA_ "FlexKomSigStartValue" SG_ 1014 EC_CBC5B "00000000h";
BA_ "GenSigCycleTime" SG_ 1014 EC_CBC5B 2000;
BA_ "GenSigSNA" SG_ 1014 EC_CBC5A "0h";
BA_ "FlexKomIsMotorola" SG_ 1014 EC_CBC5A 1;
BA_ "FlexKomComment" SG_ 1014 EC_CBC5A "CBC ecu configuration 5";
BA_ "FlexKomSigName" SG_ 1014 EC_CBC5A "EC_CBC5";
BA_ "FlexKomSigLaenge" SG_ 1014 EC_CBC5A 32;
BA_ "FlexKomSigStartPos" SG_ 1014 EC_CBC5A 7;
BA_ "FlexKomSID" SG_ 1014 EC_CBC5A 1105;
BA_ "FlexKomSigStartValue" SG_ 1014 EC_CBC5A "00000000h";
BA_ "GenSigCycleTime" SG_ 1014 EC_CBC5A 2000;
BA_ "GenMsgStartDelayTime" BO_ 1013 60;
BA_ "GenMsgStartValue" BO_ 1013 "0300000000000000h";
BA_ "GenMsgNrOfRepetitions" BO_ 1013 2;
BA_ "GenMsgDelayTime" BO_ 1013 20;
BA_ "GenMsgCycleTime" BO_ 1013 2000;
BA_ "GenMsgSendType" BO_ 1013 5;
BA_ "GenSigSNA" SG_ 1013 EC_Steering "0h";
BA_ "FlexKomIsMotorola" SG_ 1013 EC_Steering 1;
BA_ "FlexKomComment" SG_ 1013 EC_Steering "Steering ecu configuration";
BA_ "FlexKomSigName" SG_ 1013 EC_Steering "EC_Steering";
BA_ "FlexKomSigLaenge" SG_ 1013 EC_Steering 16;
BA_ "FlexKomSigStartPos" SG_ 1013 EC_Steering 23;
BA_ "FlexKomSID" SG_ 1013 EC_Steering 1982;
BA_ "GenSigTimeout_ORC" SG_ 1013 EC_Steering 7000;
BA_ "GenSigTimeout_EPS" SG_ 1013 EC_Steering 21000;
BA_ "FlexKomSigStartValue" SG_ 1013 EC_Steering "0000h";
BA_ "GenSigCycleTime" SG_ 1013 EC_Steering 2000;
BA_ "GenSigSendType" SG_ 1013 EC_Steering 5;
BA_ "GenSigSNA" SG_ 1013 EC_Safety "0h";
BA_ "FlexKomIsMotorola" SG_ 1013 EC_Safety 1;
BA_ "FlexKomComment" SG_ 1013 EC_Safety "Safety ecu configuration";
BA_ "FlexKomSigName" SG_ 1013 EC_Safety "EC_Safety";
BA_ "FlexKomSigLaenge" SG_ 1013 EC_Safety 16;
BA_ "FlexKomSigStartPos" SG_ 1013 EC_Safety 55;
BA_ "FlexKomSID" SG_ 1013 EC_Safety 892;
BA_ "GenSigTimeout_ORC" SG_ 1013 EC_Safety 7000;
BA_ "FlexKomSigStartValue" SG_ 1013 EC_Safety "0000h";
BA_ "GenSigCycleTime" SG_ 1013 EC_Safety 2000;
BA_ "GenSigSendType" SG_ 1013 EC_Safety 5;
BA_ "GenSigSNA" SG_ 1013 EC_Powertrain "0h";
BA_ "FlexKomIsMotorola" SG_ 1013 EC_Powertrain 1;
BA_ "FlexKomComment" SG_ 1013 EC_Powertrain "Powertrain ecu configuration";
BA_ "FlexKomSigName" SG_ 1013 EC_Powertrain "EC_Powertrain";
BA_ "FlexKomSigLaenge" SG_ 1013 EC_Powertrain 16;
BA_ "FlexKomSigStartPos" SG_ 1013 EC_Powertrain 39;
BA_ "FlexKomSID" SG_ 1013 EC_Powertrain 890;
BA_ "FlexKomSigStartValue" SG_ 1013 EC_Powertrain "0000h";
BA_ "GenSigCycleTime" SG_ 1013 EC_Powertrain 2000;
BA_ "GenSigSendType" SG_ 1013 EC_Powertrain 5;
BA_ "GenSigSNA" SG_ 1013 EC_ECUCfg6_Stat "3h";
BA_ "FlexKomIsMotorola" SG_ 1013 EC_ECUCfg6_Stat 1;
BA_ "FlexKomComment" SG_ 1013 EC_ECUCfg6_Stat "ECU Configuration messages status 6";
BA_ "FlexKomSigName" SG_ 1013 EC_ECUCfg6_Stat "EC_ECUCfg6_Stat";
BA_ "FlexKomSigLaenge" SG_ 1013 EC_ECUCfg6_Stat 2;
BA_ "FlexKomSigStartPos" SG_ 1013 EC_ECUCfg6_Stat 1;
BA_ "FlexKomSID" SG_ 1013 EC_ECUCfg6_Stat 1063;
BA_ "GenSigTimeout_ORC" SG_ 1013 EC_ECUCfg6_Stat 7000;
BA_ "GenSigTimeout_EPS" SG_ 1013 EC_ECUCfg6_Stat 21000;
BA_ "GenSigStartValue" SG_ 1013 EC_ECUCfg6_Stat 3;
BA_ "FlexKomSigStartValue" SG_ 1013 EC_ECUCfg6_Stat "03h";
BA_ "GenSigCycleTime" SG_ 1013 EC_ECUCfg6_Stat 2000;
BA_ "GenSigSendType" SG_ 1013 EC_ECUCfg6_Stat 5;
BA_ "GenSigSNA" SG_ 1013 EC_BrakesB "0h";
BA_ "FlexKomIsMotorola" SG_ 1013 EC_BrakesB 1;
BA_ "FlexKomComment" SG_ 1013 EC_BrakesB "Brake system ecu configuration";
BA_ "FlexKomSigName" SG_ 1013 EC_BrakesB "EC_Brakes";
BA_ "FlexKomSigLaenge" SG_ 1013 EC_BrakesB 16;
BA_ "FlexKomSigStartPos" SG_ 1013 EC_BrakesB 7;
BA_ "FlexKomSID" SG_ 1013 EC_BrakesB 889;
BA_ "FlexKomSigStartValue" SG_ 1013 EC_BrakesB "0000h";
BA_ "GenSigCycleTime" SG_ 1013 EC_BrakesB 2000;
BA_ "GenSigSendType" SG_ 1013 EC_BrakesB 5;
BA_ "GenSigSNA" SG_ 1013 EC_BrakesA "0h";
BA_ "FlexKomIsMotorola" SG_ 1013 EC_BrakesA 1;
BA_ "FlexKomComment" SG_ 1013 EC_BrakesA "Brake system ecu configuration";
BA_ "FlexKomSigName" SG_ 1013 EC_BrakesA "EC_Brakes";
BA_ "FlexKomSigLaenge" SG_ 1013 EC_BrakesA 16;
BA_ "FlexKomSigStartPos" SG_ 1013 EC_BrakesA 7;
BA_ "FlexKomSID" SG_ 1013 EC_BrakesA 889;
BA_ "FlexKomSigStartValue" SG_ 1013 EC_BrakesA "0000h";
BA_ "GenSigCycleTime" SG_ 1013 EC_BrakesA 2000;
BA_ "GenSigSendType" SG_ 1013 EC_BrakesA 5;
BA_ "GenMsgStartDelayTime" BO_ 1012 50;
BA_ "GenMsgStartValue" BO_ 1012 "0300000000000000h";
BA_ "GenMsgNrOfRepetitions" BO_ 1012 2;
BA_ "GenMsgDelayTime" BO_ 1012 20;
BA_ "GenMsgCycleTime" BO_ 1012 2000;
BA_ "GenMsgSendType" BO_ 1012 5;
BA_ "GenSigSNA" SG_ 1012 EC_WirelessB "0h";
BA_ "FlexKomIsMotorola" SG_ 1012 EC_WirelessB 1;
BA_ "FlexKomComment" SG_ 1012 EC_WirelessB "Wireless ecu configuration";
BA_ "FlexKomSigName" SG_ 1012 EC_WirelessB "EC_Wireless";
BA_ "FlexKomSigLaenge" SG_ 1012 EC_WirelessB 24;
BA_ "FlexKomSigStartPos" SG_ 1012 EC_WirelessB 7;
BA_ "FlexKomSID" SG_ 1012 EC_WirelessB 895;
BA_ "FlexKomSigStartValue" SG_ 1012 EC_WirelessB "000000h";
BA_ "GenSigCycleTime" SG_ 1012 EC_WirelessB 2000;
BA_ "GenSigSendType" SG_ 1012 EC_WirelessB 5;
BA_ "GenSigSNA" SG_ 1012 EC_WirelessA "0h";
BA_ "FlexKomIsMotorola" SG_ 1012 EC_WirelessA 1;
BA_ "FlexKomComment" SG_ 1012 EC_WirelessA "Wireless ecu configuration";
BA_ "FlexKomSigName" SG_ 1012 EC_WirelessA "EC_Wireless";
BA_ "FlexKomSigLaenge" SG_ 1012 EC_WirelessA 24;
BA_ "FlexKomSigStartPos" SG_ 1012 EC_WirelessA 7;
BA_ "FlexKomSID" SG_ 1012 EC_WirelessA 895;
BA_ "FlexKomSigStartValue" SG_ 1012 EC_WirelessA "000000h";
BA_ "GenSigCycleTime" SG_ 1012 EC_WirelessA 2000;
BA_ "GenSigSendType" SG_ 1012 EC_WirelessA 5;
BA_ "GenSigSNA" SG_ 1012 EC_Memory "0h";
BA_ "FlexKomIsMotorola" SG_ 1012 EC_Memory 1;
BA_ "FlexKomComment" SG_ 1012 EC_Memory "Memory ecu configuration";
BA_ "FlexKomSigName" SG_ 1012 EC_Memory "EC_Memory";
BA_ "FlexKomSigLaenge" SG_ 1012 EC_Memory 16;
BA_ "FlexKomSigStartPos" SG_ 1012 EC_Memory 55;
BA_ "FlexKomSID" SG_ 1012 EC_Memory 894;
BA_ "FlexKomSigStartValue" SG_ 1012 EC_Memory "0000h";
BA_ "GenSigCycleTime" SG_ 1012 EC_Memory 2000;
BA_ "GenSigSendType" SG_ 1012 EC_Memory 5;
BA_ "GenSigSNA" SG_ 1012 EC_ECUCfg5_Stat "3h";
BA_ "FlexKomIsMotorola" SG_ 1012 EC_ECUCfg5_Stat 1;
BA_ "FlexKomComment" SG_ 1012 EC_ECUCfg5_Stat "ECU Configuration messages status 5";
BA_ "FlexKomSigName" SG_ 1012 EC_ECUCfg5_Stat "EC_ECUCfg5_Stat";
BA_ "FlexKomSigLaenge" SG_ 1012 EC_ECUCfg5_Stat 2;
BA_ "FlexKomSigStartPos" SG_ 1012 EC_ECUCfg5_Stat 1;
BA_ "FlexKomSID" SG_ 1012 EC_ECUCfg5_Stat 1062;
BA_ "GenSigStartValue" SG_ 1012 EC_ECUCfg5_Stat 3;
BA_ "FlexKomSigStartValue" SG_ 1012 EC_ECUCfg5_Stat "03h";
BA_ "GenSigCycleTime" SG_ 1012 EC_ECUCfg5_Stat 2000;
BA_ "GenSigSendType" SG_ 1012 EC_ECUCfg5_Stat 5;
BA_ "GenSigSNA" SG_ 1012 EC_Doors "0h";
BA_ "FlexKomIsMotorola" SG_ 1012 EC_Doors 1;
BA_ "FlexKomComment" SG_ 1012 EC_Doors "Doors ecu configuration";
BA_ "FlexKomSigName" SG_ 1012 EC_Doors "EC_Doors";
BA_ "FlexKomSigLaenge" SG_ 1012 EC_Doors 24;
BA_ "FlexKomSigStartPos" SG_ 1012 EC_Doors 31;
BA_ "FlexKomSID" SG_ 1012 EC_Doors 893;
BA_ "FlexKomSigStartValue" SG_ 1012 EC_Doors "000000h";
BA_ "GenSigCycleTime" SG_ 1012 EC_Doors 2000;
BA_ "GenSigSendType" SG_ 1012 EC_Doors 5;
BA_ "GenMsgStartDelayTime" BO_ 1011 40;
BA_ "GenMsgStartValue" BO_ 1011 "0300000000000000h";
BA_ "GenMsgNrOfRepetitions" BO_ 1011 2;
BA_ "GenMsgDelayTime" BO_ 1011 20;
BA_ "GenMsgCycleTime" BO_ 1011 2000;
BA_ "GenMsgSendType" BO_ 1011 5;
BA_ "GenSigSNA" SG_ 1011 EC_ECUCfg4_Stat "3h";
BA_ "FlexKomIsMotorola" SG_ 1011 EC_ECUCfg4_Stat 1;
BA_ "FlexKomComment" SG_ 1011 EC_ECUCfg4_Stat "ECU Configuration messages status 4";
BA_ "FlexKomSigName" SG_ 1011 EC_ECUCfg4_Stat "EC_ECUCfg4_Stat";
BA_ "FlexKomSigLaenge" SG_ 1011 EC_ECUCfg4_Stat 2;
BA_ "FlexKomSigStartPos" SG_ 1011 EC_ECUCfg4_Stat 1;
BA_ "FlexKomSID" SG_ 1011 EC_ECUCfg4_Stat 1061;
BA_ "GenSigTimeout_IC" SG_ 1011 EC_ECUCfg4_Stat 21000;
BA_ "GenSigStartValue" SG_ 1011 EC_ECUCfg4_Stat 3;
BA_ "FlexKomSigStartValue" SG_ 1011 EC_ECUCfg4_Stat "03h";
BA_ "GenSigCycleTime" SG_ 1011 EC_ECUCfg4_Stat 2000;
BA_ "GenSigSendType" SG_ 1011 EC_ECUCfg4_Stat 5;
BA_ "GenSigSNA" SG_ 1011 EC_Cluster2 "0h";
BA_ "FlexKomIsMotorola" SG_ 1011 EC_Cluster2 1;
BA_ "FlexKomComment" SG_ 1011 EC_Cluster2 "Instrument cluster ecu configuration 2";
BA_ "FlexKomSigName" SG_ 1011 EC_Cluster2 "EC_Cluster2";
BA_ "FlexKomSigLaenge" SG_ 1011 EC_Cluster2 32;
BA_ "FlexKomSigStartPos" SG_ 1011 EC_Cluster2 39;
BA_ "FlexKomSID" SG_ 1011 EC_Cluster2 903;
BA_ "GenSigTimeout_IC" SG_ 1011 EC_Cluster2 21000;
BA_ "FlexKomSigStartValue" SG_ 1011 EC_Cluster2 "00000000h";
BA_ "GenSigCycleTime" SG_ 1011 EC_Cluster2 2000;
BA_ "GenSigSendType" SG_ 1011 EC_Cluster2 5;
BA_ "GenSigSNA" SG_ 1011 EC_Cluster1B "0h";
BA_ "FlexKomIsMotorola" SG_ 1011 EC_Cluster1B 1;
BA_ "FlexKomComment" SG_ 1011 EC_Cluster1B "Instrument cluster ecu configuration 1";
BA_ "FlexKomSigName" SG_ 1011 EC_Cluster1B "EC_Cluster1";
BA_ "FlexKomSigLaenge" SG_ 1011 EC_Cluster1B 32;
BA_ "FlexKomSigStartPos" SG_ 1011 EC_Cluster1B 7;
BA_ "FlexKomSID" SG_ 1011 EC_Cluster1B 896;
BA_ "GenSigTimeout_IC" SG_ 1011 EC_Cluster1B 21000;
BA_ "FlexKomSigStartValue" SG_ 1011 EC_Cluster1B "00000000h";
BA_ "GenSigCycleTime" SG_ 1011 EC_Cluster1B 2000;
BA_ "GenSigSendType" SG_ 1011 EC_Cluster1B 5;
BA_ "GenSigSNA" SG_ 1011 EC_Cluster1A "0h";
BA_ "FlexKomIsMotorola" SG_ 1011 EC_Cluster1A 1;
BA_ "FlexKomComment" SG_ 1011 EC_Cluster1A "Instrument cluster ecu configuration 1";
BA_ "FlexKomSigName" SG_ 1011 EC_Cluster1A "EC_Cluster1";
BA_ "FlexKomSigLaenge" SG_ 1011 EC_Cluster1A 32;
BA_ "FlexKomSigStartPos" SG_ 1011 EC_Cluster1A 7;
BA_ "FlexKomSID" SG_ 1011 EC_Cluster1A 896;
BA_ "GenSigTimeout_IC" SG_ 1011 EC_Cluster1A 21000;
BA_ "FlexKomSigStartValue" SG_ 1011 EC_Cluster1A "00000000h";
BA_ "GenSigCycleTime" SG_ 1011 EC_Cluster1A 2000;
BA_ "GenSigSendType" SG_ 1011 EC_Cluster1A 5;
BA_ "GenMsgStartDelayTime" BO_ 1010 30;
BA_ "GenMsgStartValue" BO_ 1010 "0300000000000000h";
BA_ "GenMsgNrOfRepetitions" BO_ 1010 2;
BA_ "GenMsgDelayTime" BO_ 1010 20;
BA_ "GenMsgCycleTime" BO_ 1010 2000;
BA_ "GenMsgSendType" BO_ 1010 5;
BA_ "GenSigSNA" SG_ 1010 EC_ECUCfg3_Stat "3h";
BA_ "FlexKomIsMotorola" SG_ 1010 EC_ECUCfg3_Stat 1;
BA_ "FlexKomComment" SG_ 1010 EC_ECUCfg3_Stat "ECU Configuration messages status 3";
BA_ "FlexKomSigName" SG_ 1010 EC_ECUCfg3_Stat "EC_ECUCfg3_Stat";
BA_ "FlexKomSigLaenge" SG_ 1010 EC_ECUCfg3_Stat 2;
BA_ "FlexKomSigStartPos" SG_ 1010 EC_ECUCfg3_Stat 1;
BA_ "FlexKomSID" SG_ 1010 EC_ECUCfg3_Stat 1060;
BA_ "GenSigStartValue" SG_ 1010 EC_ECUCfg3_Stat 3;
BA_ "FlexKomSigStartValue" SG_ 1010 EC_ECUCfg3_Stat "03h";
BA_ "GenSigCycleTime" SG_ 1010 EC_ECUCfg3_Stat 2000;
BA_ "GenSigSendType" SG_ 1010 EC_ECUCfg3_Stat 5;
BA_ "GenSigSNA" SG_ 1010 EC_AudTel2 "0h";
BA_ "FlexKomIsMotorola" SG_ 1010 EC_AudTel2 1;
BA_ "FlexKomComment" SG_ 1010 EC_AudTel2 "Audio and telematics ecu configuration 2";
BA_ "FlexKomSigName" SG_ 1010 EC_AudTel2 "EC_AudTel2";
BA_ "FlexKomSigLaenge" SG_ 1010 EC_AudTel2 32;
BA_ "FlexKomSigStartPos" SG_ 1010 EC_AudTel2 39;
BA_ "FlexKomSID" SG_ 1010 EC_AudTel2 898;
BA_ "FlexKomSigStartValue" SG_ 1010 EC_AudTel2 "00000000h";
BA_ "GenSigCycleTime" SG_ 1010 EC_AudTel2 2000;
BA_ "GenSigSendType" SG_ 1010 EC_AudTel2 5;
BA_ "GenSigSNA" SG_ 1010 EC_AudTel1B "0h";
BA_ "FlexKomIsMotorola" SG_ 1010 EC_AudTel1B 1;
BA_ "FlexKomComment" SG_ 1010 EC_AudTel1B "Audio and telematics ecu configuration 1";
BA_ "FlexKomSigName" SG_ 1010 EC_AudTel1B "EC_AudTel1";
BA_ "FlexKomSigLaenge" SG_ 1010 EC_AudTel1B 32;
BA_ "FlexKomSigStartPos" SG_ 1010 EC_AudTel1B 7;
BA_ "FlexKomSID" SG_ 1010 EC_AudTel1B 897;
BA_ "FlexKomSigStartValue" SG_ 1010 EC_AudTel1B "00000000h";
BA_ "GenSigCycleTime" SG_ 1010 EC_AudTel1B 2000;
BA_ "GenSigSendType" SG_ 1010 EC_AudTel1B 5;
BA_ "GenSigSNA" SG_ 1010 EC_AudTel1A "0h";
BA_ "FlexKomIsMotorola" SG_ 1010 EC_AudTel1A 1;
BA_ "FlexKomComment" SG_ 1010 EC_AudTel1A "Audio and telematics ecu configuration 1";
BA_ "FlexKomSigName" SG_ 1010 EC_AudTel1A "EC_AudTel1";
BA_ "FlexKomSigLaenge" SG_ 1010 EC_AudTel1A 32;
BA_ "FlexKomSigStartPos" SG_ 1010 EC_AudTel1A 7;
BA_ "FlexKomSID" SG_ 1010 EC_AudTel1A 897;
BA_ "FlexKomSigStartValue" SG_ 1010 EC_AudTel1A "00000000h";
BA_ "GenSigCycleTime" SG_ 1010 EC_AudTel1A 2000;
BA_ "GenSigSendType" SG_ 1010 EC_AudTel1A 5;
BA_ "GenMsgStartDelayTime" BO_ 1009 150;
BA_ "GenMsgStartValue" BO_ 1009 "0300000000000000h";
BA_ "GenMsgNrOfRepetitions" BO_ 1009 2;
BA_ "GenMsgDelayTime" BO_ 1009 20;
BA_ "GenMsgCycleTime" BO_ 1009 2000;
BA_ "GenSigSNA" SG_ 1009 EC_ECUCfg2_Stat "3h";
BA_ "FlexKomIsMotorola" SG_ 1009 EC_ECUCfg2_Stat 1;
BA_ "FlexKomComment" SG_ 1009 EC_ECUCfg2_Stat "ECU Configuration messages status 2";
BA_ "FlexKomSigName" SG_ 1009 EC_ECUCfg2_Stat "EC_ECUCfg2_Stat";
BA_ "FlexKomSigLaenge" SG_ 1009 EC_ECUCfg2_Stat 2;
BA_ "FlexKomSigStartPos" SG_ 1009 EC_ECUCfg2_Stat 1;
BA_ "FlexKomSID" SG_ 1009 EC_ECUCfg2_Stat 1059;
BA_ "GenSigStartValue" SG_ 1009 EC_ECUCfg2_Stat 3;
BA_ "FlexKomSigStartValue" SG_ 1009 EC_ECUCfg2_Stat "03h";
BA_ "GenSigCycleTime" SG_ 1009 EC_ECUCfg2_Stat 2000;
BA_ "GenSigSNA" SG_ 1009 EC_CBC4 "0h";
BA_ "FlexKomIsMotorola" SG_ 1009 EC_CBC4 1;
BA_ "FlexKomComment" SG_ 1009 EC_CBC4 "CBC ecu configuration 4";
BA_ "FlexKomSigName" SG_ 1009 EC_CBC4 "EC_CBC4";
BA_ "FlexKomSigLaenge" SG_ 1009 EC_CBC4 32;
BA_ "FlexKomSigStartPos" SG_ 1009 EC_CBC4 39;
BA_ "FlexKomSID" SG_ 1009 EC_CBC4 902;
BA_ "FlexKomSigStartValue" SG_ 1009 EC_CBC4 "00000000h";
BA_ "GenSigCycleTime" SG_ 1009 EC_CBC4 2000;
BA_ "GenSigSNA" SG_ 1009 EC_CBC3B "0h";
BA_ "FlexKomIsMotorola" SG_ 1009 EC_CBC3B 1;
BA_ "FlexKomComment" SG_ 1009 EC_CBC3B "CBC ecu configuration 3";
BA_ "FlexKomSigName" SG_ 1009 EC_CBC3B "EC_CBC3";
BA_ "FlexKomSigLaenge" SG_ 1009 EC_CBC3B 32;
BA_ "FlexKomSigStartPos" SG_ 1009 EC_CBC3B 7;
BA_ "FlexKomSID" SG_ 1009 EC_CBC3B 901;
BA_ "FlexKomSigStartValue" SG_ 1009 EC_CBC3B "00000000h";
BA_ "GenSigCycleTime" SG_ 1009 EC_CBC3B 2000;
BA_ "GenSigSNA" SG_ 1009 EC_CBC3A "0h";
BA_ "FlexKomIsMotorola" SG_ 1009 EC_CBC3A 1;
BA_ "FlexKomComment" SG_ 1009 EC_CBC3A "CBC ecu configuration 3";
BA_ "FlexKomSigName" SG_ 1009 EC_CBC3A "EC_CBC3";
BA_ "FlexKomSigLaenge" SG_ 1009 EC_CBC3A 32;
BA_ "FlexKomSigStartPos" SG_ 1009 EC_CBC3A 7;
BA_ "FlexKomSID" SG_ 1009 EC_CBC3A 901;
BA_ "FlexKomSigStartValue" SG_ 1009 EC_CBC3A "00000000h";
BA_ "GenSigCycleTime" SG_ 1009 EC_CBC3A 2000;
BA_ "GenMsgStartDelayTime" BO_ 1008 140;
BA_ "GenMsgStartValue" BO_ 1008 "0300000000000000h";
BA_ "GenMsgNrOfRepetitions" BO_ 1008 2;
BA_ "GenMsgDelayTime" BO_ 1008 20;
BA_ "GenMsgCycleTime" BO_ 1008 2000;
BA_ "GenSigSNA" SG_ 1008 EC_ECUCfg1_Stat "3h";
BA_ "FlexKomIsMotorola" SG_ 1008 EC_ECUCfg1_Stat 1;
BA_ "FlexKomComment" SG_ 1008 EC_ECUCfg1_Stat "ECU Configuration messages status 1";
BA_ "FlexKomSigName" SG_ 1008 EC_ECUCfg1_Stat "EC_ECUCfg1_Stat";
BA_ "FlexKomSigLaenge" SG_ 1008 EC_ECUCfg1_Stat 2;
BA_ "FlexKomSigStartPos" SG_ 1008 EC_ECUCfg1_Stat 1;
BA_ "FlexKomSID" SG_ 1008 EC_ECUCfg1_Stat 1058;
BA_ "GenSigStartValue" SG_ 1008 EC_ECUCfg1_Stat 3;
BA_ "FlexKomSigStartValue" SG_ 1008 EC_ECUCfg1_Stat "03h";
BA_ "GenSigCycleTime" SG_ 1008 EC_ECUCfg1_Stat 2000;
BA_ "GenSigSNA" SG_ 1008 EC_CBC2 "0h";
BA_ "FlexKomIsMotorola" SG_ 1008 EC_CBC2 1;
BA_ "FlexKomComment" SG_ 1008 EC_CBC2 "CBC ecu configuration 2";
BA_ "FlexKomSigName" SG_ 1008 EC_CBC2 "EC_CBC2";
BA_ "FlexKomSigLaenge" SG_ 1008 EC_CBC2 32;
BA_ "FlexKomSigStartPos" SG_ 1008 EC_CBC2 39;
BA_ "FlexKomSID" SG_ 1008 EC_CBC2 900;
BA_ "FlexKomSigStartValue" SG_ 1008 EC_CBC2 "00000000h";
BA_ "GenSigCycleTime" SG_ 1008 EC_CBC2 2000;
BA_ "GenSigSNA" SG_ 1008 EC_CBC1B "0h";
BA_ "FlexKomIsMotorola" SG_ 1008 EC_CBC1B 1;
BA_ "FlexKomComment" SG_ 1008 EC_CBC1B "CBC ecu configuration 1";
BA_ "FlexKomSigName" SG_ 1008 EC_CBC1B "EC_CBC1";
BA_ "FlexKomSigLaenge" SG_ 1008 EC_CBC1B 32;
BA_ "FlexKomSigStartPos" SG_ 1008 EC_CBC1B 7;
BA_ "FlexKomSID" SG_ 1008 EC_CBC1B 899;
BA_ "FlexKomSigStartValue" SG_ 1008 EC_CBC1B "00000000h";
BA_ "GenSigCycleTime" SG_ 1008 EC_CBC1B 2000;
BA_ "GenSigSNA" SG_ 1008 EC_CBC1A "0h";
BA_ "FlexKomIsMotorola" SG_ 1008 EC_CBC1A 1;
BA_ "FlexKomComment" SG_ 1008 EC_CBC1A "CBC ecu configuration 1";
BA_ "FlexKomSigName" SG_ 1008 EC_CBC1A "EC_CBC1";
BA_ "FlexKomSigLaenge" SG_ 1008 EC_CBC1A 32;
BA_ "FlexKomSigStartPos" SG_ 1008 EC_CBC1A 7;
BA_ "FlexKomSID" SG_ 1008 EC_CBC1A 899;
BA_ "FlexKomSigStartValue" SG_ 1008 EC_CBC1A "00000000h";
BA_ "GenSigCycleTime" SG_ 1008 EC_CBC1A 2000;
BA_ "GenMsgStartDelayTime" BO_ 1003 120;
BA_ "GenMsgStartValue" BO_ 1003 "FFFFFFFFFFFFFFFFh";
BA_ "GenMsgNrOfRepetitions" BO_ 1003 2;
BA_ "GenMsgDelayTime" BO_ 1003 20;
BA_ "GenMsgCycleTime" BO_ 1003 1000;
BA_ "GenMsgSendType" BO_ 1003 5;
BA_ "GenSigSNA" SG_ 1003 VC_VehCfg4_Stat "3h";
BA_ "FlexKomIsMotorola" SG_ 1003 VC_VehCfg4_Stat 1;
BA_ "FlexKomComment" SG_ 1003 VC_VehCfg4_Stat "Vehicle Configuration 4 Packet";
BA_ "FlexKomSigName" SG_ 1003 VC_VehCfg4_Stat "VehCfg4_Pkt";
BA_ "FlexKomSigLaenge" SG_ 1003 VC_VehCfg4_Stat 64;
BA_ "FlexKomSigStartPos" SG_ 1003 VC_VehCfg4_Stat 7;
BA_ "FlexKomSID" SG_ 1003 VC_VehCfg4_Stat 1035;
BA_ "GenSigTimeout_ORC" SG_ 1003 VC_VehCfg4_Stat 3500;
BA_ "GenSigTimeout_RF_HUB" SG_ 1003 VC_VehCfg4_Stat 10500;
BA_ "GenSigStartValue" SG_ 1003 VC_VehCfg4_Stat 3;
BA_ "FlexKomSigStartValue" SG_ 1003 VC_VehCfg4_Stat "FFFFFFFFFFFFFFFFh";
BA_ "GenSigCycleTime" SG_ 1003 VC_VehCfg4_Stat 1000;
BA_ "GenSigSendType" SG_ 1003 VC_VehCfg4_Stat 5;
BA_ "GenSigSNA" SG_ 1003 VC_TIRE_CIRCUMF "FFFFh";
BA_ "FlexKomIsMotorola" SG_ 1003 VC_TIRE_CIRCUMF 1;
BA_ "FlexKomComment" SG_ 1003 VC_TIRE_CIRCUMF "Vehicle Configuration 4 Packet";
BA_ "FlexKomSigName" SG_ 1003 VC_TIRE_CIRCUMF "VehCfg4_Pkt";
BA_ "FlexKomSigLaenge" SG_ 1003 VC_TIRE_CIRCUMF 64;
BA_ "FlexKomSigStartPos" SG_ 1003 VC_TIRE_CIRCUMF 7;
BA_ "FlexKomSID" SG_ 1003 VC_TIRE_CIRCUMF 1035;
BA_ "GenSigTimeout_ORC" SG_ 1003 VC_TIRE_CIRCUMF 3500;
BA_ "GenSigStartValue" SG_ 1003 VC_TIRE_CIRCUMF 65535;
BA_ "FlexKomSigStartValue" SG_ 1003 VC_TIRE_CIRCUMF "FFFFFFFFFFFFFFFFh";
BA_ "GenSigCycleTime" SG_ 1003 VC_TIRE_CIRCUMF 1000;
BA_ "GenSigSendType" SG_ 1003 VC_TIRE_CIRCUMF 5;
BA_ "GenSigSNA" SG_ 1003 VC_TCASE_LO_RATIO "FFFFh";
BA_ "FlexKomIsMotorola" SG_ 1003 VC_TCASE_LO_RATIO 1;
BA_ "FlexKomComment" SG_ 1003 VC_TCASE_LO_RATIO "Vehicle Configuration 4 Packet";
BA_ "FlexKomSigName" SG_ 1003 VC_TCASE_LO_RATIO "VehCfg4_Pkt";
BA_ "FlexKomSigLaenge" SG_ 1003 VC_TCASE_LO_RATIO 64;
BA_ "FlexKomSigStartPos" SG_ 1003 VC_TCASE_LO_RATIO 7;
BA_ "FlexKomSID" SG_ 1003 VC_TCASE_LO_RATIO 1035;
BA_ "GenSigStartValue" SG_ 1003 VC_TCASE_LO_RATIO 65535;
BA_ "FlexKomSigStartValue" SG_ 1003 VC_TCASE_LO_RATIO "FFFFFFFFFFFFFFFFh";
BA_ "GenSigCycleTime" SG_ 1003 VC_TCASE_LO_RATIO 1000;
BA_ "GenSigSendType" SG_ 1003 VC_TCASE_LO_RATIO 5;
BA_ "GenSigSNA" SG_ 1003 VC_TCASE_HI_RATIO "3FFFh";
BA_ "FlexKomIsMotorola" SG_ 1003 VC_TCASE_HI_RATIO 1;
BA_ "FlexKomComment" SG_ 1003 VC_TCASE_HI_RATIO "Vehicle Configuration 4 Packet";
BA_ "FlexKomSigName" SG_ 1003 VC_TCASE_HI_RATIO "VehCfg4_Pkt";
BA_ "FlexKomSigLaenge" SG_ 1003 VC_TCASE_HI_RATIO 64;
BA_ "FlexKomSigStartPos" SG_ 1003 VC_TCASE_HI_RATIO 7;
BA_ "FlexKomSID" SG_ 1003 VC_TCASE_HI_RATIO 1035;
BA_ "GenSigStartValue" SG_ 1003 VC_TCASE_HI_RATIO 16383;
BA_ "FlexKomSigStartValue" SG_ 1003 VC_TCASE_HI_RATIO "FFFFFFFFFFFFFFFFh";
BA_ "GenSigCycleTime" SG_ 1003 VC_TCASE_HI_RATIO 1000;
BA_ "GenSigSendType" SG_ 1003 VC_TCASE_HI_RATIO 5;
BA_ "GenSigSNA" SG_ 1003 VC_AXLE_RATIO "FFFFh";
BA_ "FlexKomIsMotorola" SG_ 1003 VC_AXLE_RATIO 1;
BA_ "FlexKomComment" SG_ 1003 VC_AXLE_RATIO "Vehicle Configuration 4 Packet";
BA_ "FlexKomSigName" SG_ 1003 VC_AXLE_RATIO "VehCfg4_Pkt";
BA_ "FlexKomSigLaenge" SG_ 1003 VC_AXLE_RATIO 64;
BA_ "FlexKomSigStartPos" SG_ 1003 VC_AXLE_RATIO 7;
BA_ "FlexKomSID" SG_ 1003 VC_AXLE_RATIO 1035;
BA_ "GenSigStartValue" SG_ 1003 VC_AXLE_RATIO 65535;
BA_ "FlexKomSigStartValue" SG_ 1003 VC_AXLE_RATIO "FFFFFFFFFFFFFFFFh";
BA_ "GenSigCycleTime" SG_ 1003 VC_AXLE_RATIO 1000;
BA_ "GenSigSendType" SG_ 1003 VC_AXLE_RATIO 5;
BA_ "GenMsgStartDelayTime" BO_ 1002 50;
BA_ "GenMsgStartValue" BO_ 1002 "0370FF037FFF0000h";
BA_ "GenMsgNrOfRepetitions" BO_ 1002 2;
BA_ "GenMsgDelayTime" BO_ 1002 20;
BA_ "GenMsgCycleTime" BO_ 1002 2000;
BA_ "GenMsgSendType" BO_ 1002 5;
BA_ "GenSigSNA" SG_ 1002 VC_WIN_EXPR_FEAT "3h";
BA_ "FlexKomIsMotorola" SG_ 1002 VC_WIN_EXPR_FEAT 1;
BA_ "FlexKomComment" SG_ 1002 VC_WIN_EXPR_FEAT "Vehicle Configuration 3 Packet";
BA_ "FlexKomSigName" SG_ 1002 VC_WIN_EXPR_FEAT "VehCfg3_Pkt";
BA_ "FlexKomSigLaenge" SG_ 1002 VC_WIN_EXPR_FEAT 64;
BA_ "FlexKomSigStartPos" SG_ 1002 VC_WIN_EXPR_FEAT 7;
BA_ "FlexKomSID" SG_ 1002 VC_WIN_EXPR_FEAT 888;
BA_ "GenSigStartValue" SG_ 1002 VC_WIN_EXPR_FEAT 3;
BA_ "FlexKomSigStartValue" SG_ 1002 VC_WIN_EXPR_FEAT "0370FF037FFF0000h";
BA_ "GenSigCycleTime" SG_ 1002 VC_WIN_EXPR_FEAT 2000;
BA_ "GenSigSendType" SG_ 1002 VC_WIN_EXPR_FEAT 5;
BA_ "GenSigSNA" SG_ 1002 VC_WHL_BASE "3h";
BA_ "FlexKomIsMotorola" SG_ 1002 VC_WHL_BASE 1;
BA_ "FlexKomComment" SG_ 1002 VC_WHL_BASE "Vehicle Configuration 3 Packet";
BA_ "FlexKomSigName" SG_ 1002 VC_WHL_BASE "VehCfg3_Pkt";
BA_ "FlexKomSigLaenge" SG_ 1002 VC_WHL_BASE 64;
BA_ "FlexKomSigStartPos" SG_ 1002 VC_WHL_BASE 7;
BA_ "FlexKomSID" SG_ 1002 VC_WHL_BASE 888;
BA_ "GenSigTimeout_ORC" SG_ 1002 VC_WHL_BASE 7000;
BA_ "GenSigStartValue" SG_ 1002 VC_WHL_BASE 3;
BA_ "FlexKomSigStartValue" SG_ 1002 VC_WHL_BASE "0370FF037FFF0000h";
BA_ "GenSigCycleTime" SG_ 1002 VC_WHL_BASE 2000;
BA_ "GenSigSendType" SG_ 1002 VC_WHL_BASE 5;
BA_ "GenSigSNA" SG_ 1002 VC_VehCfg3_Stat "3h";
BA_ "FlexKomIsMotorola" SG_ 1002 VC_VehCfg3_Stat 1;
BA_ "FlexKomComment" SG_ 1002 VC_VehCfg3_Stat "Vehicle Configuration 3 Packet";
BA_ "FlexKomSigName" SG_ 1002 VC_VehCfg3_Stat "VehCfg3_Pkt";
BA_ "FlexKomSigLaenge" SG_ 1002 VC_VehCfg3_Stat 64;
BA_ "FlexKomSigStartPos" SG_ 1002 VC_VehCfg3_Stat 7;
BA_ "FlexKomSID" SG_ 1002 VC_VehCfg3_Stat 888;
BA_ "GenSigTimeout_ORC" SG_ 1002 VC_VehCfg3_Stat 7000;
BA_ "GenSigTimeout_EPS" SG_ 1002 VC_VehCfg3_Stat 21000;
BA_ "GenSigTimeout_IC" SG_ 1002 VC_VehCfg3_Stat 21000;
BA_ "GenSigStartValue" SG_ 1002 VC_VehCfg3_Stat 3;
BA_ "FlexKomSigStartValue" SG_ 1002 VC_VehCfg3_Stat "0370FF037FFF0000h";
BA_ "GenSigCycleTime" SG_ 1002 VC_VehCfg3_Stat 2000;
BA_ "GenSigSendType" SG_ 1002 VC_VehCfg3_Stat 5;
BA_ "GenSigSNA" SG_ 1002 VC_VEH_BRAND "Fh";
BA_ "FlexKomIsMotorola" SG_ 1002 VC_VEH_BRAND 1;
BA_ "FlexKomComment" SG_ 1002 VC_VEH_BRAND "Vehicle Configuration 3 Packet";
BA_ "FlexKomSigName" SG_ 1002 VC_VEH_BRAND "VehCfg3_Pkt";
BA_ "FlexKomSigLaenge" SG_ 1002 VC_VEH_BRAND 64;
BA_ "FlexKomSigStartPos" SG_ 1002 VC_VEH_BRAND 7;
BA_ "FlexKomSID" SG_ 1002 VC_VEH_BRAND 888;
BA_ "GenSigTimeout_IC" SG_ 1002 VC_VEH_BRAND 21000;
BA_ "GenSigStartValue" SG_ 1002 VC_VEH_BRAND 15;
BA_ "FlexKomSigStartValue" SG_ 1002 VC_VEH_BRAND "0370FF037FFF0000h";
BA_ "GenSigCycleTime" SG_ 1002 VC_VEH_BRAND 2000;
BA_ "GenSigSendType" SG_ 1002 VC_VEH_BRAND 5;
BA_ "GenSigSNA" SG_ 1002 VC_TEMP_DISP "0h";
BA_ "FlexKomIsMotorola" SG_ 1002 VC_TEMP_DISP 1;
BA_ "FlexKomComment" SG_ 1002 VC_TEMP_DISP "Vehicle Configuration 3 Packet";
BA_ "FlexKomSigName" SG_ 1002 VC_TEMP_DISP "VehCfg3_Pkt";
BA_ "FlexKomSigLaenge" SG_ 1002 VC_TEMP_DISP 64;
BA_ "FlexKomSigStartPos" SG_ 1002 VC_TEMP_DISP 7;
BA_ "FlexKomSID" SG_ 1002 VC_TEMP_DISP 888;
BA_ "GenSigTimeout_IC" SG_ 1002 VC_TEMP_DISP 21000;
BA_ "FlexKomSigStartValue" SG_ 1002 VC_TEMP_DISP "0370FF037FFF0000h";
BA_ "GenSigCycleTime" SG_ 1002 VC_TEMP_DISP 2000;
BA_ "GenSigSendType" SG_ 1002 VC_TEMP_DISP 5;
BA_ "GenSigSNA" SG_ 1002 VC_TcaseTyp "0h";
BA_ "FlexKomIsMotorola" SG_ 1002 VC_TcaseTyp 1;
BA_ "FlexKomComment" SG_ 1002 VC_TcaseTyp "Vehicle Configuration 3 Packet";
BA_ "FlexKomSigName" SG_ 1002 VC_TcaseTyp "VehCfg3_Pkt";
BA_ "FlexKomSigLaenge" SG_ 1002 VC_TcaseTyp 64;
BA_ "FlexKomSigStartPos" SG_ 1002 VC_TcaseTyp 7;
BA_ "FlexKomSID" SG_ 1002 VC_TcaseTyp 888;
BA_ "FlexKomSigStartValue" SG_ 1002 VC_TcaseTyp "0370FF037FFF0000h";
BA_ "GenSigCycleTime" SG_ 1002 VC_TcaseTyp 2000;
BA_ "GenSigSendType" SG_ 1002 VC_TcaseTyp 5;
BA_ "GenSigSNA" SG_ 1002 VC_SunShade_Present "0h";
BA_ "FlexKomIsMotorola" SG_ 1002 VC_SunShade_Present 1;
BA_ "FlexKomComment" SG_ 1002 VC_SunShade_Present "Vehicle Configuration 3 Packet";
BA_ "FlexKomSigName" SG_ 1002 VC_SunShade_Present "VehCfg3_Pkt";
BA_ "FlexKomSigLaenge" SG_ 1002 VC_SunShade_Present 64;
BA_ "FlexKomSigStartPos" SG_ 1002 VC_SunShade_Present 7;
BA_ "FlexKomSID" SG_ 1002 VC_SunShade_Present 888;
BA_ "FlexKomSigStartValue" SG_ 1002 VC_SunShade_Present "0370FF037FFF0000h";
BA_ "GenSigCycleTime" SG_ 1002 VC_SunShade_Present 2000;
BA_ "GenSigSendType" SG_ 1002 VC_SunShade_Present 5;
BA_ "GenSigSNA" SG_ 1002 VC_SRT_PRSNT "0h";
BA_ "FlexKomIsMotorola" SG_ 1002 VC_SRT_PRSNT 1;
BA_ "FlexKomComment" SG_ 1002 VC_SRT_PRSNT "Vehicle Configuration 3 Packet";
BA_ "FlexKomSigName" SG_ 1002 VC_SRT_PRSNT "VehCfg3_Pkt";
BA_ "FlexKomSigLaenge" SG_ 1002 VC_SRT_PRSNT 64;
BA_ "FlexKomSigStartPos" SG_ 1002 VC_SRT_PRSNT 7;
BA_ "FlexKomSID" SG_ 1002 VC_SRT_PRSNT 888;
BA_ "GenSigTimeout_ORC" SG_ 1002 VC_SRT_PRSNT 7000;
BA_ "GenSigTimeout_IC" SG_ 1002 VC_SRT_PRSNT 21000;
BA_ "FlexKomSigStartValue" SG_ 1002 VC_SRT_PRSNT "0370FF037FFF0000h";
BA_ "GenSigCycleTime" SG_ 1002 VC_SRT_PRSNT 2000;
BA_ "GenSigSendType" SG_ 1002 VC_SRT_PRSNT 5;
BA_ "GenSigSNA" SG_ 1002 VC_SPORT_PRSNT "0h";
BA_ "FlexKomIsMotorola" SG_ 1002 VC_SPORT_PRSNT 1;
BA_ "FlexKomComment" SG_ 1002 VC_SPORT_PRSNT "Vehicle Configuration 3 Packet";
BA_ "FlexKomSigName" SG_ 1002 VC_SPORT_PRSNT "VehCfg3_Pkt";
BA_ "FlexKomSigLaenge" SG_ 1002 VC_SPORT_PRSNT 64;
BA_ "FlexKomSigStartPos" SG_ 1002 VC_SPORT_PRSNT 7;
BA_ "FlexKomSID" SG_ 1002 VC_SPORT_PRSNT 888;
BA_ "GenSigTimeout_IC" SG_ 1002 VC_SPORT_PRSNT 21000;
BA_ "FlexKomSigStartValue" SG_ 1002 VC_SPORT_PRSNT "0370FF037FFF0000h";
BA_ "GenSigCycleTime" SG_ 1002 VC_SPORT_PRSNT 2000;
BA_ "GenSigSendType" SG_ 1002 VC_SPORT_PRSNT 5;
BA_ "GenSigSNA" SG_ 1002 VC_SecLkPrsnt "0h";
BA_ "FlexKomIsMotorola" SG_ 1002 VC_SecLkPrsnt 1;
BA_ "FlexKomComment" SG_ 1002 VC_SecLkPrsnt "Vehicle Configuration 3 Packet";
BA_ "FlexKomSigName" SG_ 1002 VC_SecLkPrsnt "VehCfg3_Pkt";
BA_ "FlexKomSigLaenge" SG_ 1002 VC_SecLkPrsnt 64;
BA_ "FlexKomSigStartPos" SG_ 1002 VC_SecLkPrsnt 7;
BA_ "FlexKomSID" SG_ 1002 VC_SecLkPrsnt 888;
BA_ "FlexKomSigStartValue" SG_ 1002 VC_SecLkPrsnt "0370FF037FFF0000h";
BA_ "GenSigCycleTime" SG_ 1002 VC_SecLkPrsnt 2000;
BA_ "GenSigSendType" SG_ 1002 VC_SecLkPrsnt 5;
BA_ "GenSigSNA" SG_ 1002 VC_RKE_PRSNT "0h";
BA_ "FlexKomIsMotorola" SG_ 1002 VC_RKE_PRSNT 1;
BA_ "FlexKomComment" SG_ 1002 VC_RKE_PRSNT "Vehicle Configuration 3 Packet";
BA_ "FlexKomSigName" SG_ 1002 VC_RKE_PRSNT "VehCfg3_Pkt";
BA_ "FlexKomSigLaenge" SG_ 1002 VC_RKE_PRSNT 64;
BA_ "FlexKomSigStartPos" SG_ 1002 VC_RKE_PRSNT 7;
BA_ "FlexKomSID" SG_ 1002 VC_RKE_PRSNT 888;
BA_ "GenSigTimeout_IC" SG_ 1002 VC_RKE_PRSNT 21000;
BA_ "FlexKomSigStartValue" SG_ 1002 VC_RKE_PRSNT "0370FF037FFF0000h";
BA_ "GenSigCycleTime" SG_ 1002 VC_RKE_PRSNT 2000;
BA_ "GenSigSendType" SG_ 1002 VC_RKE_PRSNT 5;
BA_ "GenSigSNA" SG_ 1002 VC_PWR_RT_SLDR "0h";
BA_ "FlexKomIsMotorola" SG_ 1002 VC_PWR_RT_SLDR 1;
BA_ "FlexKomComment" SG_ 1002 VC_PWR_RT_SLDR "Vehicle Configuration 3 Packet";
BA_ "FlexKomSigName" SG_ 1002 VC_PWR_RT_SLDR "VehCfg3_Pkt";
BA_ "FlexKomSigLaenge" SG_ 1002 VC_PWR_RT_SLDR 64;
BA_ "FlexKomSigStartPos" SG_ 1002 VC_PWR_RT_SLDR 7;
BA_ "FlexKomSID" SG_ 1002 VC_PWR_RT_SLDR 888;
BA_ "FlexKomSigStartValue" SG_ 1002 VC_PWR_RT_SLDR "0370FF037FFF0000h";
BA_ "GenSigCycleTime" SG_ 1002 VC_PWR_RT_SLDR 2000;
BA_ "GenSigSendType" SG_ 1002 VC_PWR_RT_SLDR 5;
BA_ "GenSigSNA" SG_ 1002 VC_PWR_LT_SLDR "0h";
BA_ "FlexKomIsMotorola" SG_ 1002 VC_PWR_LT_SLDR 1;
BA_ "FlexKomComment" SG_ 1002 VC_PWR_LT_SLDR "Vehicle Configuration 3 Packet";
BA_ "FlexKomSigName" SG_ 1002 VC_PWR_LT_SLDR "VehCfg3_Pkt";
BA_ "FlexKomSigLaenge" SG_ 1002 VC_PWR_LT_SLDR 64;
BA_ "FlexKomSigStartPos" SG_ 1002 VC_PWR_LT_SLDR 7;
BA_ "FlexKomSID" SG_ 1002 VC_PWR_LT_SLDR 888;
BA_ "FlexKomSigStartValue" SG_ 1002 VC_PWR_LT_SLDR "0370FF037FFF0000h";
BA_ "GenSigCycleTime" SG_ 1002 VC_PWR_LT_SLDR 2000;
BA_ "GenSigSendType" SG_ 1002 VC_PWR_LT_SLDR 5;
BA_ "GenSigSNA" SG_ 1002 VC_PWR_LFT_GT "0h";
BA_ "FlexKomIsMotorola" SG_ 1002 VC_PWR_LFT_GT 1;
BA_ "FlexKomComment" SG_ 1002 VC_PWR_LFT_GT "Vehicle Configuration 3 Packet";
BA_ "FlexKomSigName" SG_ 1002 VC_PWR_LFT_GT "VehCfg3_Pkt";
BA_ "FlexKomSigLaenge" SG_ 1002 VC_PWR_LFT_GT 64;
BA_ "FlexKomSigStartPos" SG_ 1002 VC_PWR_LFT_GT 7;
BA_ "FlexKomSID" SG_ 1002 VC_PWR_LFT_GT 888;
BA_ "FlexKomSigStartValue" SG_ 1002 VC_PWR_LFT_GT "0370FF037FFF0000h";
BA_ "GenSigCycleTime" SG_ 1002 VC_PWR_LFT_GT 2000;
BA_ "GenSigSendType" SG_ 1002 VC_PWR_LFT_GT 5;
BA_ "GenSigSNA" SG_ 1002 VC_Prem_TPM "0h";
BA_ "FlexKomIsMotorola" SG_ 1002 VC_Prem_TPM 1;
BA_ "FlexKomComment" SG_ 1002 VC_Prem_TPM "Vehicle Configuration 3 Packet";
BA_ "FlexKomSigName" SG_ 1002 VC_Prem_TPM "VehCfg3_Pkt";
BA_ "FlexKomSigLaenge" SG_ 1002 VC_Prem_TPM 64;
BA_ "FlexKomSigStartPos" SG_ 1002 VC_Prem_TPM 7;
BA_ "FlexKomSID" SG_ 1002 VC_Prem_TPM 888;
BA_ "GenSigTimeout_ORC" SG_ 1002 VC_Prem_TPM 7000;
BA_ "GenSigTimeout_IC" SG_ 1002 VC_Prem_TPM 21000;
BA_ "FlexKomSigStartValue" SG_ 1002 VC_Prem_TPM "0370FF037FFF0000h";
BA_ "GenSigCycleTime" SG_ 1002 VC_Prem_TPM 2000;
BA_ "GenSigSendType" SG_ 1002 VC_Prem_TPM 5;
BA_ "GenSigSNA" SG_ 1002 VC_POLICE "0h";
BA_ "FlexKomIsMotorola" SG_ 1002 VC_POLICE 1;
BA_ "FlexKomComment" SG_ 1002 VC_POLICE "Vehicle Configuration 3 Packet";
BA_ "FlexKomSigName" SG_ 1002 VC_POLICE "VehCfg3_Pkt";
BA_ "FlexKomSigLaenge" SG_ 1002 VC_POLICE 64;
BA_ "FlexKomSigStartPos" SG_ 1002 VC_POLICE 7;
BA_ "FlexKomSID" SG_ 1002 VC_POLICE 888;
BA_ "GenSigTimeout_ORC" SG_ 1002 VC_POLICE 7000;
BA_ "GenSigTimeout_IC" SG_ 1002 VC_POLICE 21000;
BA_ "FlexKomSigStartValue" SG_ 1002 VC_POLICE "0370FF037FFF0000h";
BA_ "GenSigCycleTime" SG_ 1002 VC_POLICE 2000;
BA_ "GenSigSendType" SG_ 1002 VC_POLICE 5;
BA_ "GenSigSNA" SG_ 1002 VC_PE_Prsnt "0h";
BA_ "FlexKomIsMotorola" SG_ 1002 VC_PE_Prsnt 1;
BA_ "FlexKomComment" SG_ 1002 VC_PE_Prsnt "Vehicle Configuration 3 Packet";
BA_ "FlexKomSigName" SG_ 1002 VC_PE_Prsnt "VehCfg3_Pkt";
BA_ "FlexKomSigLaenge" SG_ 1002 VC_PE_Prsnt 64;
BA_ "FlexKomSigStartPos" SG_ 1002 VC_PE_Prsnt 7;
BA_ "FlexKomSID" SG_ 1002 VC_PE_Prsnt 888;
BA_ "GenSigTimeout_IC" SG_ 1002 VC_PE_Prsnt 21000;
BA_ "FlexKomSigStartValue" SG_ 1002 VC_PE_Prsnt "0370FF037FFF0000h";
BA_ "GenSigCycleTime" SG_ 1002 VC_PE_Prsnt 2000;
BA_ "GenSigSendType" SG_ 1002 VC_PE_Prsnt 5;
BA_ "GenSigSNA" SG_ 1002 VC_PDDL_PRSNT "0h";
BA_ "FlexKomIsMotorola" SG_ 1002 VC_PDDL_PRSNT 1;
BA_ "FlexKomComment" SG_ 1002 VC_PDDL_PRSNT "Vehicle Configuration 3 Packet";
BA_ "FlexKomSigName" SG_ 1002 VC_PDDL_PRSNT "VehCfg3_Pkt";
BA_ "FlexKomSigLaenge" SG_ 1002 VC_PDDL_PRSNT 64;
BA_ "FlexKomSigStartPos" SG_ 1002 VC_PDDL_PRSNT 7;
BA_ "FlexKomSID" SG_ 1002 VC_PDDL_PRSNT 888;
BA_ "GenSigTimeout_IC" SG_ 1002 VC_PDDL_PRSNT 21000;
BA_ "FlexKomSigStartValue" SG_ 1002 VC_PDDL_PRSNT "0370FF037FFF0000h";
BA_ "GenSigCycleTime" SG_ 1002 VC_PDDL_PRSNT 2000;
BA_ "GenSigSendType" SG_ 1002 VC_PDDL_PRSNT 5;
BA_ "GenSigSNA" SG_ 1002 VC_Liftgate_Trunk "3h";
BA_ "FlexKomIsMotorola" SG_ 1002 VC_Liftgate_Trunk 1;
BA_ "FlexKomComment" SG_ 1002 VC_Liftgate_Trunk "Vehicle Configuration 3 Packet";
BA_ "FlexKomSigName" SG_ 1002 VC_Liftgate_Trunk "VehCfg3_Pkt";
BA_ "FlexKomSigLaenge" SG_ 1002 VC_Liftgate_Trunk 64;
BA_ "FlexKomSigStartPos" SG_ 1002 VC_Liftgate_Trunk 7;
BA_ "FlexKomSID" SG_ 1002 VC_Liftgate_Trunk 888;
BA_ "GenSigTimeout_IC" SG_ 1002 VC_Liftgate_Trunk 21000;
BA_ "FlexKomSigStartValue" SG_ 1002 VC_Liftgate_Trunk "0370FF037FFF0000h";
BA_ "GenSigCycleTime" SG_ 1002 VC_Liftgate_Trunk 2000;
BA_ "GenSigSendType" SG_ 1002 VC_Liftgate_Trunk 5;
BA_ "GenSigSNA" SG_ 1002 VC_KG_Prsnt "0h";
BA_ "FlexKomIsMotorola" SG_ 1002 VC_KG_Prsnt 1;
BA_ "FlexKomComment" SG_ 1002 VC_KG_Prsnt "Vehicle Configuration 3 Packet";
BA_ "FlexKomSigName" SG_ 1002 VC_KG_Prsnt "VehCfg3_Pkt";
BA_ "FlexKomSigLaenge" SG_ 1002 VC_KG_Prsnt 64;
BA_ "FlexKomSigStartPos" SG_ 1002 VC_KG_Prsnt 7;
BA_ "FlexKomSID" SG_ 1002 VC_KG_Prsnt 888;
BA_ "GenSigTimeout_IC" SG_ 1002 VC_KG_Prsnt 21000;
BA_ "FlexKomSigStartValue" SG_ 1002 VC_KG_Prsnt "0370FF037FFF0000h";
BA_ "GenSigCycleTime" SG_ 1002 VC_KG_Prsnt 2000;
BA_ "GenSigSendType" SG_ 1002 VC_KG_Prsnt 5;
BA_ "GenSigSNA" SG_ 1002 VC_IntEC_MIRR "0h";
BA_ "FlexKomIsMotorola" SG_ 1002 VC_IntEC_MIRR 1;
BA_ "FlexKomComment" SG_ 1002 VC_IntEC_MIRR "Vehicle Configuration 3 Packet";
BA_ "FlexKomSigName" SG_ 1002 VC_IntEC_MIRR "VehCfg3_Pkt";
BA_ "FlexKomSigLaenge" SG_ 1002 VC_IntEC_MIRR 64;
BA_ "FlexKomSigStartPos" SG_ 1002 VC_IntEC_MIRR 7;
BA_ "FlexKomSID" SG_ 1002 VC_IntEC_MIRR 888;
BA_ "FlexKomSigStartValue" SG_ 1002 VC_IntEC_MIRR "0370FF037FFF0000h";
BA_ "GenSigCycleTime" SG_ 1002 VC_IntEC_MIRR 2000;
BA_ "GenSigSendType" SG_ 1002 VC_IntEC_MIRR 5;
BA_ "GenSigSNA" SG_ 1002 VC_HVAC_Config "Fh";
BA_ "FlexKomIsMotorola" SG_ 1002 VC_HVAC_Config 1;
BA_ "FlexKomComment" SG_ 1002 VC_HVAC_Config "Vehicle Configuration 3 Packet";
BA_ "FlexKomSigName" SG_ 1002 VC_HVAC_Config "VehCfg3_Pkt";
BA_ "FlexKomSigLaenge" SG_ 1002 VC_HVAC_Config 64;
BA_ "FlexKomSigStartPos" SG_ 1002 VC_HVAC_Config 7;
BA_ "FlexKomSID" SG_ 1002 VC_HVAC_Config 888;
BA_ "GenSigTimeout_IC" SG_ 1002 VC_HVAC_Config 21000;
BA_ "GenSigStartValue" SG_ 1002 VC_HVAC_Config 15;
BA_ "FlexKomSigStartValue" SG_ 1002 VC_HVAC_Config "0370FF037FFF0000h";
BA_ "GenSigCycleTime" SG_ 1002 VC_HVAC_Config 2000;
BA_ "GenSigSendType" SG_ 1002 VC_HVAC_Config 5;
BA_ "GenSigSNA" SG_ 1002 VC_HID_HL "0h";
BA_ "FlexKomIsMotorola" SG_ 1002 VC_HID_HL 1;
BA_ "FlexKomComment" SG_ 1002 VC_HID_HL "Vehicle Configuration 3 Packet";
BA_ "FlexKomSigName" SG_ 1002 VC_HID_HL "VehCfg3_Pkt";
BA_ "FlexKomSigLaenge" SG_ 1002 VC_HID_HL 64;
BA_ "FlexKomSigStartPos" SG_ 1002 VC_HID_HL 7;
BA_ "FlexKomSID" SG_ 1002 VC_HID_HL 888;
BA_ "FlexKomSigStartValue" SG_ 1002 VC_HID_HL "0370FF037FFF0000h";
BA_ "GenSigCycleTime" SG_ 1002 VC_HID_HL 2000;
BA_ "GenSigSendType" SG_ 1002 VC_HID_HL 5;
BA_ "GenSigSNA" SG_ 1002 VC_FUEL_CAP "FFh";
BA_ "FlexKomIsMotorola" SG_ 1002 VC_FUEL_CAP 1;
BA_ "FlexKomComment" SG_ 1002 VC_FUEL_CAP "Vehicle Configuration 3 Packet";
BA_ "FlexKomSigName" SG_ 1002 VC_FUEL_CAP "VehCfg3_Pkt";
BA_ "FlexKomSigLaenge" SG_ 1002 VC_FUEL_CAP 64;
BA_ "FlexKomSigStartPos" SG_ 1002 VC_FUEL_CAP 7;
BA_ "FlexKomSID" SG_ 1002 VC_FUEL_CAP 888;
BA_ "GenSigTimeout_IC" SG_ 1002 VC_FUEL_CAP 21000;
BA_ "GenSigStartValue" SG_ 1002 VC_FUEL_CAP 255;
BA_ "FlexKomSigStartValue" SG_ 1002 VC_FUEL_CAP "0370FF037FFF0000h";
BA_ "GenSigCycleTime" SG_ 1002 VC_FUEL_CAP 2000;
BA_ "GenSigSendType" SG_ 1002 VC_FUEL_CAP 5;
BA_ "GenSigSNA" SG_ 1002 VC_FOBIKsafeENBL "1h";
BA_ "FlexKomIsMotorola" SG_ 1002 VC_FOBIKsafeENBL 1;
BA_ "FlexKomComment" SG_ 1002 VC_FOBIKsafeENBL "Vehicle Configuration 3 Packet";
BA_ "FlexKomSigName" SG_ 1002 VC_FOBIKsafeENBL "VehCfg3_Pkt";
BA_ "FlexKomSigLaenge" SG_ 1002 VC_FOBIKsafeENBL 64;
BA_ "FlexKomSigStartPos" SG_ 1002 VC_FOBIKsafeENBL 7;
BA_ "FlexKomSID" SG_ 1002 VC_FOBIKsafeENBL 888;
BA_ "GenSigStartValue" SG_ 1002 VC_FOBIKsafeENBL 1;
BA_ "FlexKomSigStartValue" SG_ 1002 VC_FOBIKsafeENBL "0370FF037FFF0000h";
BA_ "GenSigCycleTime" SG_ 1002 VC_FOBIKsafeENBL 2000;
BA_ "GenSigSendType" SG_ 1002 VC_FOBIKsafeENBL 5;
BA_ "GenSigSNA" SG_ 1002 VC_FCW "0h";
BA_ "FlexKomIsMotorola" SG_ 1002 VC_FCW 1;
BA_ "FlexKomComment" SG_ 1002 VC_FCW "Vehicle Configuration 3 Packet";
BA_ "FlexKomSigName" SG_ 1002 VC_FCW "VehCfg3_Pkt";
BA_ "FlexKomSigLaenge" SG_ 1002 VC_FCW 64;
BA_ "FlexKomSigStartPos" SG_ 1002 VC_FCW 7;
BA_ "FlexKomSID" SG_ 1002 VC_FCW 888;
BA_ "GenSigTimeout_ORC" SG_ 1002 VC_FCW 7000;
BA_ "FlexKomSigStartValue" SG_ 1002 VC_FCW "0370FF037FFF0000h";
BA_ "GenSigCycleTime" SG_ 1002 VC_FCW 2000;
BA_ "GenSigSendType" SG_ 1002 VC_FCW 5;
BA_ "GenSigSNA" SG_ 1002 VC_ESCL_PRSNT "0h";
BA_ "FlexKomIsMotorola" SG_ 1002 VC_ESCL_PRSNT 1;
BA_ "FlexKomComment" SG_ 1002 VC_ESCL_PRSNT "Vehicle Configuration 3 Packet";
BA_ "FlexKomSigName" SG_ 1002 VC_ESCL_PRSNT "VehCfg3_Pkt";
BA_ "FlexKomSigLaenge" SG_ 1002 VC_ESCL_PRSNT 64;
BA_ "FlexKomSigStartPos" SG_ 1002 VC_ESCL_PRSNT 7;
BA_ "FlexKomSID" SG_ 1002 VC_ESCL_PRSNT 888;
BA_ "FlexKomSigStartValue" SG_ 1002 VC_ESCL_PRSNT "0370FF037FFF0000h";
BA_ "GenSigCycleTime" SG_ 1002 VC_ESCL_PRSNT 2000;
BA_ "GenSigSendType" SG_ 1002 VC_ESCL_PRSNT 5;
BA_ "GenSigSNA" SG_ 1002 VC_ELV_Prsnt "0h";
BA_ "FlexKomIsMotorola" SG_ 1002 VC_ELV_Prsnt 1;
BA_ "FlexKomComment" SG_ 1002 VC_ELV_Prsnt "Vehicle Configuration 3 Packet";
BA_ "FlexKomSigName" SG_ 1002 VC_ELV_Prsnt "VehCfg3_Pkt";
BA_ "FlexKomSigLaenge" SG_ 1002 VC_ELV_Prsnt 64;
BA_ "FlexKomSigStartPos" SG_ 1002 VC_ELV_Prsnt 7;
BA_ "FlexKomSID" SG_ 1002 VC_ELV_Prsnt 888;
BA_ "FlexKomSigStartValue" SG_ 1002 VC_ELV_Prsnt "0370FF037FFF0000h";
BA_ "GenSigCycleTime" SG_ 1002 VC_ELV_Prsnt 2000;
BA_ "GenSigSendType" SG_ 1002 VC_ELV_Prsnt 5;
BA_ "GenSigSNA" SG_ 1002 VC_DualFuelSens "0h";
BA_ "FlexKomIsMotorola" SG_ 1002 VC_DualFuelSens 1;
BA_ "FlexKomComment" SG_ 1002 VC_DualFuelSens "Vehicle Configuration 3 Packet";
BA_ "FlexKomSigName" SG_ 1002 VC_DualFuelSens "VehCfg3_Pkt";
BA_ "FlexKomSigLaenge" SG_ 1002 VC_DualFuelSens 64;
BA_ "FlexKomSigStartPos" SG_ 1002 VC_DualFuelSens 7;
BA_ "FlexKomSID" SG_ 1002 VC_DualFuelSens 888;
BA_ "GenSigTimeout_IC" SG_ 1002 VC_DualFuelSens 21000;
BA_ "FlexKomSigStartValue" SG_ 1002 VC_DualFuelSens "0370FF037FFF0000h";
BA_ "GenSigCycleTime" SG_ 1002 VC_DualFuelSens 2000;
BA_ "GenSigSendType" SG_ 1002 VC_DualFuelSens 5;
BA_ "GenSigSNA" SG_ 1002 VC_DSBL_CLK_DISP "0h";
BA_ "FlexKomIsMotorola" SG_ 1002 VC_DSBL_CLK_DISP 1;
BA_ "FlexKomComment" SG_ 1002 VC_DSBL_CLK_DISP "Vehicle Configuration 3 Packet";
BA_ "FlexKomSigName" SG_ 1002 VC_DSBL_CLK_DISP "VehCfg3_Pkt";
BA_ "FlexKomSigLaenge" SG_ 1002 VC_DSBL_CLK_DISP 64;
BA_ "FlexKomSigStartPos" SG_ 1002 VC_DSBL_CLK_DISP 7;
BA_ "FlexKomSID" SG_ 1002 VC_DSBL_CLK_DISP 888;
BA_ "GenSigTimeout_IC" SG_ 1002 VC_DSBL_CLK_DISP 21000;
BA_ "FlexKomSigStartValue" SG_ 1002 VC_DSBL_CLK_DISP "0370FF037FFF0000h";
BA_ "GenSigCycleTime" SG_ 1002 VC_DSBL_CLK_DISP 2000;
BA_ "GenSigSendType" SG_ 1002 VC_DSBL_CLK_DISP 5;
BA_ "GenSigSNA" SG_ 1002 VC_DrAlrPrsnt "0h";
BA_ "FlexKomIsMotorola" SG_ 1002 VC_DrAlrPrsnt 1;
BA_ "FlexKomComment" SG_ 1002 VC_DrAlrPrsnt "Vehicle Configuration 3 Packet";
BA_ "FlexKomSigName" SG_ 1002 VC_DrAlrPrsnt "VehCfg3_Pkt";
BA_ "FlexKomSigLaenge" SG_ 1002 VC_DrAlrPrsnt 64;
BA_ "FlexKomSigStartPos" SG_ 1002 VC_DrAlrPrsnt 7;
BA_ "FlexKomSID" SG_ 1002 VC_DrAlrPrsnt 888;
BA_ "GenSigTimeout_IC" SG_ 1002 VC_DrAlrPrsnt 21000;
BA_ "FlexKomSigStartValue" SG_ 1002 VC_DrAlrPrsnt "0370FF037FFF0000h";
BA_ "GenSigCycleTime" SG_ 1002 VC_DrAlrPrsnt 2000;
BA_ "GenSigSendType" SG_ 1002 VC_DrAlrPrsnt 5;
BA_ "GenSigSNA" SG_ 1002 VC_CMS "0h";
BA_ "FlexKomIsMotorola" SG_ 1002 VC_CMS 1;
BA_ "FlexKomComment" SG_ 1002 VC_CMS "Vehicle Configuration 3 Packet";
BA_ "FlexKomSigName" SG_ 1002 VC_CMS "VehCfg3_Pkt";
BA_ "FlexKomSigLaenge" SG_ 1002 VC_CMS 64;
BA_ "FlexKomSigStartPos" SG_ 1002 VC_CMS 7;
BA_ "FlexKomSID" SG_ 1002 VC_CMS 888;
BA_ "GenSigTimeout_ORC" SG_ 1002 VC_CMS 7000;
BA_ "FlexKomSigStartValue" SG_ 1002 VC_CMS "0370FF037FFF0000h";
BA_ "GenSigCycleTime" SG_ 1002 VC_CMS 2000;
BA_ "GenSigSendType" SG_ 1002 VC_CMS 5;
BA_ "GenSigSNA" SG_ 1002 VC_CMP_DISP "0h";
BA_ "FlexKomIsMotorola" SG_ 1002 VC_CMP_DISP 1;
BA_ "FlexKomComment" SG_ 1002 VC_CMP_DISP "Vehicle Configuration 3 Packet";
BA_ "FlexKomSigName" SG_ 1002 VC_CMP_DISP "VehCfg3_Pkt";
BA_ "FlexKomSigLaenge" SG_ 1002 VC_CMP_DISP 64;
BA_ "FlexKomSigStartPos" SG_ 1002 VC_CMP_DISP 7;
BA_ "FlexKomSID" SG_ 1002 VC_CMP_DISP 888;
BA_ "GenSigTimeout_IC" SG_ 1002 VC_CMP_DISP 21000;
BA_ "FlexKomSigStartValue" SG_ 1002 VC_CMP_DISP "0370FF037FFF0000h";
BA_ "GenSigCycleTime" SG_ 1002 VC_CMP_DISP 2000;
BA_ "GenSigSendType" SG_ 1002 VC_CMP_DISP 5;
BA_ "GenSigSNA" SG_ 1002 VC_ChassisType "7Fh";
BA_ "FlexKomIsMotorola" SG_ 1002 VC_ChassisType 1;
BA_ "FlexKomComment" SG_ 1002 VC_ChassisType "Vehicle Configuration 3 Packet";
BA_ "FlexKomSigName" SG_ 1002 VC_ChassisType "VehCfg3_Pkt";
BA_ "FlexKomSigLaenge" SG_ 1002 VC_ChassisType 64;
BA_ "FlexKomSigStartPos" SG_ 1002 VC_ChassisType 7;
BA_ "FlexKomSID" SG_ 1002 VC_ChassisType 888;
BA_ "GenSigTimeout_ORC" SG_ 1002 VC_ChassisType 7000;
BA_ "GenSigTimeout_EPS" SG_ 1002 VC_ChassisType 21000;
BA_ "GenSigTimeout_PTS" SG_ 1002 VC_ChassisType 21000;
BA_ "GenSigStartValue" SG_ 1002 VC_ChassisType 127;
BA_ "FlexKomSigStartValue" SG_ 1002 VC_ChassisType "0370FF037FFF0000h";
BA_ "GenSigCycleTime" SG_ 1002 VC_ChassisType 2000;
BA_ "GenSigSendType" SG_ 1002 VC_ChassisType 5;
BA_ "GenSigSNA" SG_ 1002 VC_Base_TPM "0h";
BA_ "FlexKomIsMotorola" SG_ 1002 VC_Base_TPM 1;
BA_ "FlexKomComment" SG_ 1002 VC_Base_TPM "Vehicle Configuration 3 Packet";
BA_ "FlexKomSigName" SG_ 1002 VC_Base_TPM "VehCfg3_Pkt";
BA_ "FlexKomSigLaenge" SG_ 1002 VC_Base_TPM 64;
BA_ "FlexKomSigStartPos" SG_ 1002 VC_Base_TPM 7;
BA_ "FlexKomSID" SG_ 1002 VC_Base_TPM 888;
BA_ "GenSigTimeout_ORC" SG_ 1002 VC_Base_TPM 7000;
BA_ "GenSigTimeout_IC" SG_ 1002 VC_Base_TPM 21000;
BA_ "FlexKomSigStartValue" SG_ 1002 VC_Base_TPM "0370FF037FFF0000h";
BA_ "GenSigCycleTime" SG_ 1002 VC_Base_TPM 2000;
BA_ "GenSigSendType" SG_ 1002 VC_Base_TPM 5;
BA_ "GenSigSNA" SG_ 1002 VC_AutoParkPrsnt "0h";
BA_ "FlexKomIsMotorola" SG_ 1002 VC_AutoParkPrsnt 1;
BA_ "FlexKomComment" SG_ 1002 VC_AutoParkPrsnt "Vehicle Configuration 3 Packet";
BA_ "FlexKomSigName" SG_ 1002 VC_AutoParkPrsnt "VehCfg3_Pkt";
BA_ "FlexKomSigLaenge" SG_ 1002 VC_AutoParkPrsnt 64;
BA_ "FlexKomSigStartPos" SG_ 1002 VC_AutoParkPrsnt 7;
BA_ "FlexKomSID" SG_ 1002 VC_AutoParkPrsnt 888;
BA_ "GenSigTimeout_IC" SG_ 1002 VC_AutoParkPrsnt 21000;
BA_ "FlexKomSigStartValue" SG_ 1002 VC_AutoParkPrsnt "0370FF037FFF0000h";
BA_ "GenSigCycleTime" SG_ 1002 VC_AutoParkPrsnt 2000;
BA_ "GenSigSendType" SG_ 1002 VC_AutoParkPrsnt 5;
BA_ "GenSigSNA" SG_ 1002 VC_AUTO_HL "0h";
BA_ "FlexKomIsMotorola" SG_ 1002 VC_AUTO_HL 1;
BA_ "FlexKomComment" SG_ 1002 VC_AUTO_HL "Vehicle Configuration 3 Packet";
BA_ "FlexKomSigName" SG_ 1002 VC_AUTO_HL "VehCfg3_Pkt";
BA_ "FlexKomSigLaenge" SG_ 1002 VC_AUTO_HL 64;
BA_ "FlexKomSigStartPos" SG_ 1002 VC_AUTO_HL 7;
BA_ "FlexKomSID" SG_ 1002 VC_AUTO_HL 888;
BA_ "GenSigTimeout_IC" SG_ 1002 VC_AUTO_HL 21000;
BA_ "FlexKomSigStartValue" SG_ 1002 VC_AUTO_HL "0370FF037FFF0000h";
BA_ "GenSigCycleTime" SG_ 1002 VC_AUTO_HL 2000;
BA_ "GenSigSendType" SG_ 1002 VC_AUTO_HL 5;
BA_ "GenSigSNA" SG_ 1002 VC_ADJ_PDL_PRSNT "0h";
BA_ "FlexKomIsMotorola" SG_ 1002 VC_ADJ_PDL_PRSNT 1;
BA_ "FlexKomComment" SG_ 1002 VC_ADJ_PDL_PRSNT "Vehicle Configuration 3 Packet";
BA_ "FlexKomSigName" SG_ 1002 VC_ADJ_PDL_PRSNT "VehCfg3_Pkt";
BA_ "FlexKomSigLaenge" SG_ 1002 VC_ADJ_PDL_PRSNT 64;
BA_ "FlexKomSigStartPos" SG_ 1002 VC_ADJ_PDL_PRSNT 7;
BA_ "FlexKomSID" SG_ 1002 VC_ADJ_PDL_PRSNT 888;
BA_ "FlexKomSigStartValue" SG_ 1002 VC_ADJ_PDL_PRSNT "0370FF037FFF0000h";
BA_ "GenSigCycleTime" SG_ 1002 VC_ADJ_PDL_PRSNT 2000;
BA_ "GenSigSendType" SG_ 1002 VC_ADJ_PDL_PRSNT 5;
BA_ "GenMsgStartDelayTime" BO_ 1001 40;
BA_ "GenMsgStartValue" BO_ 1001 "0300FF00FFFFFFFFh";
BA_ "GenMsgNrOfRepetitions" BO_ 1001 2;
BA_ "GenMsgDelayTime" BO_ 1001 20;
BA_ "GenMsgCycleTime" BO_ 1001 2000;
BA_ "GenMsgSendType" BO_ 1001 5;
BA_ "GenSigSNA" SG_ 1001 VC_VehCfg2_Stat "3h";
BA_ "FlexKomIsMotorola" SG_ 1001 VC_VehCfg2_Stat 1;
BA_ "FlexKomComment" SG_ 1001 VC_VehCfg2_Stat "Vehicle Configuration 2 Packet";
BA_ "FlexKomSigName" SG_ 1001 VC_VehCfg2_Stat "VehCfg2_Pkt";
BA_ "FlexKomSigLaenge" SG_ 1001 VC_VehCfg2_Stat 64;
BA_ "FlexKomSigStartPos" SG_ 1001 VC_VehCfg2_Stat 7;
BA_ "FlexKomSID" SG_ 1001 VC_VehCfg2_Stat 887;
BA_ "GenSigTimeout_ORC" SG_ 1001 VC_VehCfg2_Stat 7000;
BA_ "GenSigTimeout_EPS" SG_ 1001 VC_VehCfg2_Stat 21000;
BA_ "GenSigTimeout_IC" SG_ 1001 VC_VehCfg2_Stat 21000;
BA_ "GenSigStartValue" SG_ 1001 VC_VehCfg2_Stat 3;
BA_ "FlexKomSigStartValue" SG_ 1001 VC_VehCfg2_Stat "0300FF00FFFFFFFFh";
BA_ "GenSigCycleTime" SG_ 1001 VC_VehCfg2_Stat 2000;
BA_ "GenSigSendType" SG_ 1001 VC_VehCfg2_Stat 5;
BA_ "GenSigSNA" SG_ 1001 VC_ThatchamPrsnt "0h";
BA_ "FlexKomIsMotorola" SG_ 1001 VC_ThatchamPrsnt 1;
BA_ "FlexKomComment" SG_ 1001 VC_ThatchamPrsnt "Vehicle Configuration 2 Packet";
BA_ "FlexKomSigName" SG_ 1001 VC_ThatchamPrsnt "VehCfg2_Pkt";
BA_ "FlexKomSigLaenge" SG_ 1001 VC_ThatchamPrsnt 64;
BA_ "FlexKomSigStartPos" SG_ 1001 VC_ThatchamPrsnt 7;
BA_ "FlexKomSID" SG_ 1001 VC_ThatchamPrsnt 887;
BA_ "GenSigTimeout_IC" SG_ 1001 VC_ThatchamPrsnt 21000;
BA_ "FlexKomSigStartValue" SG_ 1001 VC_ThatchamPrsnt "0300FF00FFFFFFFFh";
BA_ "GenSigCycleTime" SG_ 1001 VC_ThatchamPrsnt 2000;
BA_ "GenSigSendType" SG_ 1001 VC_ThatchamPrsnt 5;
BA_ "GenSigSNA" SG_ 1001 VC_SpecialPKG_IC "FFh";
BA_ "FlexKomIsMotorola" SG_ 1001 VC_SpecialPKG_IC 1;
BA_ "FlexKomComment" SG_ 1001 VC_SpecialPKG_IC "Vehicle Configuration 2 Packet";
BA_ "FlexKomSigName" SG_ 1001 VC_SpecialPKG_IC "VehCfg2_Pkt";
BA_ "FlexKomSigLaenge" SG_ 1001 VC_SpecialPKG_IC 64;
BA_ "FlexKomSigStartPos" SG_ 1001 VC_SpecialPKG_IC 7;
BA_ "FlexKomSID" SG_ 1001 VC_SpecialPKG_IC 887;
BA_ "GenSigTimeout_ORC" SG_ 1001 VC_SpecialPKG_IC 7000;
BA_ "GenSigTimeout_IC" SG_ 1001 VC_SpecialPKG_IC 21000;
BA_ "GenSigStartValue" SG_ 1001 VC_SpecialPKG_IC 255;
BA_ "FlexKomSigStartValue" SG_ 1001 VC_SpecialPKG_IC "0300FF00FFFFFFFFh";
BA_ "GenSigCycleTime" SG_ 1001 VC_SpecialPKG_IC 2000;
BA_ "GenSigSendType" SG_ 1001 VC_SpecialPKG_IC 5;
BA_ "GenSigSNA" SG_ 1001 VC_SKIM_PRSNT "0h";
BA_ "FlexKomIsMotorola" SG_ 1001 VC_SKIM_PRSNT 1;
BA_ "FlexKomComment" SG_ 1001 VC_SKIM_PRSNT "Vehicle Configuration 2 Packet";
BA_ "FlexKomSigName" SG_ 1001 VC_SKIM_PRSNT "VehCfg2_Pkt";
BA_ "FlexKomSigLaenge" SG_ 1001 VC_SKIM_PRSNT 64;
BA_ "FlexKomSigStartPos" SG_ 1001 VC_SKIM_PRSNT 7;
BA_ "FlexKomSID" SG_ 1001 VC_SKIM_PRSNT 887;
BA_ "FlexKomSigStartValue" SG_ 1001 VC_SKIM_PRSNT "0300FF00FFFFFFFFh";
BA_ "GenSigCycleTime" SG_ 1001 VC_SKIM_PRSNT 2000;
BA_ "GenSigSendType" SG_ 1001 VC_SKIM_PRSNT 5;
BA_ "GenSigSNA" SG_ 1001 VC_ShftInd_Prsnt "0h";
BA_ "FlexKomIsMotorola" SG_ 1001 VC_ShftInd_Prsnt 1;
BA_ "FlexKomComment" SG_ 1001 VC_ShftInd_Prsnt "Vehicle Configuration 2 Packet";
BA_ "FlexKomSigName" SG_ 1001 VC_ShftInd_Prsnt "VehCfg2_Pkt";
BA_ "FlexKomSigLaenge" SG_ 1001 VC_ShftInd_Prsnt 64;
BA_ "FlexKomSigStartPos" SG_ 1001 VC_ShftInd_Prsnt 7;
BA_ "FlexKomSID" SG_ 1001 VC_ShftInd_Prsnt 887;
BA_ "GenSigTimeout_IC" SG_ 1001 VC_ShftInd_Prsnt 21000;
BA_ "FlexKomSigStartValue" SG_ 1001 VC_ShftInd_Prsnt "0300FF00FFFFFFFFh";
BA_ "GenSigCycleTime" SG_ 1001 VC_ShftInd_Prsnt 2000;
BA_ "GenSigSendType" SG_ 1001 VC_ShftInd_Prsnt 5;
BA_ "GenSigSNA" SG_ 1001 VC_SecPrkPrsnt "0h";
BA_ "FlexKomIsMotorola" SG_ 1001 VC_SecPrkPrsnt 1;
BA_ "FlexKomComment" SG_ 1001 VC_SecPrkPrsnt "Vehicle Configuration 2 Packet";
BA_ "FlexKomSigName" SG_ 1001 VC_SecPrkPrsnt "VehCfg2_Pkt";
BA_ "FlexKomSigLaenge" SG_ 1001 VC_SecPrkPrsnt 64;
BA_ "FlexKomSigStartPos" SG_ 1001 VC_SecPrkPrsnt 7;
BA_ "FlexKomSID" SG_ 1001 VC_SecPrkPrsnt 887;
BA_ "GenSigTimeout_IC" SG_ 1001 VC_SecPrkPrsnt 21000;
BA_ "FlexKomSigStartValue" SG_ 1001 VC_SecPrkPrsnt "0300FF00FFFFFFFFh";
BA_ "GenSigCycleTime" SG_ 1001 VC_SecPrkPrsnt 2000;
BA_ "GenSigSendType" SG_ 1001 VC_SecPrkPrsnt 5;
BA_ "GenSigSNA" SG_ 1001 VC_RunFlatTirePrsnt "0h";
BA_ "FlexKomIsMotorola" SG_ 1001 VC_RunFlatTirePrsnt 1;
BA_ "FlexKomComment" SG_ 1001 VC_RunFlatTirePrsnt "Vehicle Configuration 2 Packet";
BA_ "FlexKomSigName" SG_ 1001 VC_RunFlatTirePrsnt "VehCfg2_Pkt";
BA_ "FlexKomSigLaenge" SG_ 1001 VC_RunFlatTirePrsnt 64;
BA_ "FlexKomSigStartPos" SG_ 1001 VC_RunFlatTirePrsnt 7;
BA_ "FlexKomSID" SG_ 1001 VC_RunFlatTirePrsnt 887;
BA_ "GenSigTimeout_IC" SG_ 1001 VC_RunFlatTirePrsnt 21000;
BA_ "FlexKomSigStartValue" SG_ 1001 VC_RunFlatTirePrsnt "0300FF00FFFFFFFFh";
BA_ "GenSigCycleTime" SG_ 1001 VC_RunFlatTirePrsnt 2000;
BA_ "GenSigSendType" SG_ 1001 VC_RunFlatTirePrsnt 5;
BA_ "GenSigSNA" SG_ 1001 VC_RainSnsPrsnt "0h";
BA_ "FlexKomIsMotorola" SG_ 1001 VC_RainSnsPrsnt 1;
BA_ "FlexKomComment" SG_ 1001 VC_RainSnsPrsnt "Vehicle Configuration 2 Packet";
BA_ "FlexKomSigName" SG_ 1001 VC_RainSnsPrsnt "VehCfg2_Pkt";
BA_ "FlexKomSigLaenge" SG_ 1001 VC_RainSnsPrsnt 64;
BA_ "FlexKomSigStartPos" SG_ 1001 VC_RainSnsPrsnt 7;
BA_ "FlexKomSID" SG_ 1001 VC_RainSnsPrsnt 887;
BA_ "GenSigTimeout_IC" SG_ 1001 VC_RainSnsPrsnt 21000;
BA_ "FlexKomSigStartValue" SG_ 1001 VC_RainSnsPrsnt "0300FF00FFFFFFFFh";
BA_ "GenSigCycleTime" SG_ 1001 VC_RainSnsPrsnt 2000;
BA_ "GenSigSendType" SG_ 1001 VC_RainSnsPrsnt 5;
BA_ "GenSigSNA" SG_ 1001 VC_PwrIvtrTyp "0h";
BA_ "FlexKomIsMotorola" SG_ 1001 VC_PwrIvtrTyp 1;
BA_ "FlexKomComment" SG_ 1001 VC_PwrIvtrTyp "Vehicle Configuration 2 Packet";
BA_ "FlexKomSigName" SG_ 1001 VC_PwrIvtrTyp "VehCfg2_Pkt";
BA_ "FlexKomSigLaenge" SG_ 1001 VC_PwrIvtrTyp 64;
BA_ "FlexKomSigStartPos" SG_ 1001 VC_PwrIvtrTyp 7;
BA_ "FlexKomSID" SG_ 1001 VC_PwrIvtrTyp 887;
BA_ "FlexKomSigStartValue" SG_ 1001 VC_PwrIvtrTyp "0300FF00FFFFFFFFh";
BA_ "GenSigCycleTime" SG_ 1001 VC_PwrIvtrTyp 2000;
BA_ "GenSigSendType" SG_ 1001 VC_PwrIvtrTyp 5;
BA_ "GenSigSNA" SG_ 1001 VC_PADS_Prsnt "0h";
BA_ "FlexKomIsMotorola" SG_ 1001 VC_PADS_Prsnt 1;
BA_ "FlexKomComment" SG_ 1001 VC_PADS_Prsnt "Vehicle Configuration 2 Packet";
BA_ "FlexKomSigName" SG_ 1001 VC_PADS_Prsnt "VehCfg2_Pkt";
BA_ "FlexKomSigLaenge" SG_ 1001 VC_PADS_Prsnt 64;
BA_ "FlexKomSigStartPos" SG_ 1001 VC_PADS_Prsnt 7;
BA_ "FlexKomSID" SG_ 1001 VC_PADS_Prsnt 887;
BA_ "GenSigTimeout_ORC" SG_ 1001 VC_PADS_Prsnt 7000;
BA_ "FlexKomSigStartValue" SG_ 1001 VC_PADS_Prsnt "0300FF00FFFFFFFFh";
BA_ "GenSigCycleTime" SG_ 1001 VC_PADS_Prsnt 2000;
BA_ "GenSigSendType" SG_ 1001 VC_PADS_Prsnt 5;
BA_ "GenSigSNA" SG_ 1001 VC_OffRoad "0h";
BA_ "FlexKomIsMotorola" SG_ 1001 VC_OffRoad 1;
BA_ "FlexKomComment" SG_ 1001 VC_OffRoad "Vehicle Configuration 2 Packet";
BA_ "FlexKomSigName" SG_ 1001 VC_OffRoad "VehCfg2_Pkt";
BA_ "FlexKomSigLaenge" SG_ 1001 VC_OffRoad 64;
BA_ "FlexKomSigStartPos" SG_ 1001 VC_OffRoad 7;
BA_ "FlexKomSID" SG_ 1001 VC_OffRoad 887;
BA_ "GenSigTimeout_IC" SG_ 1001 VC_OffRoad 21000;
BA_ "FlexKomSigStartValue" SG_ 1001 VC_OffRoad "0300FF00FFFFFFFFh";
BA_ "GenSigCycleTime" SG_ 1001 VC_OffRoad 2000;
BA_ "GenSigSendType" SG_ 1001 VC_OffRoad 5;
BA_ "GenSigSNA" SG_ 1001 VC_MemoryDRVMD_Prsnt "0h";
BA_ "FlexKomIsMotorola" SG_ 1001 VC_MemoryDRVMD_Prsnt 1;
BA_ "FlexKomComment" SG_ 1001 VC_MemoryDRVMD_Prsnt "Vehicle Configuration 2 Packet";
BA_ "FlexKomSigName" SG_ 1001 VC_MemoryDRVMD_Prsnt "VehCfg2_Pkt";
BA_ "FlexKomSigLaenge" SG_ 1001 VC_MemoryDRVMD_Prsnt 64;
BA_ "FlexKomSigStartPos" SG_ 1001 VC_MemoryDRVMD_Prsnt 7;
BA_ "FlexKomSID" SG_ 1001 VC_MemoryDRVMD_Prsnt 887;
BA_ "GenSigTimeout_EPS" SG_ 1001 VC_MemoryDRVMD_Prsnt 21000;
BA_ "FlexKomSigStartValue" SG_ 1001 VC_MemoryDRVMD_Prsnt "0300FF00FFFFFFFFh";
BA_ "GenSigCycleTime" SG_ 1001 VC_MemoryDRVMD_Prsnt 2000;
BA_ "GenSigSendType" SG_ 1001 VC_MemoryDRVMD_Prsnt 5;
BA_ "GenSigSNA" SG_ 1001 VC_MaxLdPressRrTr "FFh";
BA_ "FlexKomIsMotorola" SG_ 1001 VC_MaxLdPressRrTr 1;
BA_ "FlexKomComment" SG_ 1001 VC_MaxLdPressRrTr "Vehicle Configuration 2 Packet";
BA_ "FlexKomSigName" SG_ 1001 VC_MaxLdPressRrTr "VehCfg2_Pkt";
BA_ "FlexKomSigLaenge" SG_ 1001 VC_MaxLdPressRrTr 64;
BA_ "FlexKomSigStartPos" SG_ 1001 VC_MaxLdPressRrTr 7;
BA_ "FlexKomSID" SG_ 1001 VC_MaxLdPressRrTr 887;
BA_ "GenSigTimeout_IC" SG_ 1001 VC_MaxLdPressRrTr 21000;
BA_ "GenSigStartValue" SG_ 1001 VC_MaxLdPressRrTr 255;
BA_ "FlexKomSigStartValue" SG_ 1001 VC_MaxLdPressRrTr "0300FF00FFFFFFFFh";
BA_ "GenSigCycleTime" SG_ 1001 VC_MaxLdPressRrTr 2000;
BA_ "GenSigSendType" SG_ 1001 VC_MaxLdPressRrTr 5;
BA_ "GenSigSNA" SG_ 1001 VC_MaxLdPressFtTr "FFh";
BA_ "FlexKomIsMotorola" SG_ 1001 VC_MaxLdPressFtTr 1;
BA_ "FlexKomComment" SG_ 1001 VC_MaxLdPressFtTr "Vehicle Configuration 2 Packet";
BA_ "FlexKomSigName" SG_ 1001 VC_MaxLdPressFtTr "VehCfg2_Pkt";
BA_ "FlexKomSigLaenge" SG_ 1001 VC_MaxLdPressFtTr 64;
BA_ "FlexKomSigStartPos" SG_ 1001 VC_MaxLdPressFtTr 7;
BA_ "FlexKomSID" SG_ 1001 VC_MaxLdPressFtTr 887;
BA_ "GenSigTimeout_IC" SG_ 1001 VC_MaxLdPressFtTr 21000;
BA_ "GenSigStartValue" SG_ 1001 VC_MaxLdPressFtTr 255;
BA_ "FlexKomSigStartValue" SG_ 1001 VC_MaxLdPressFtTr "0300FF00FFFFFFFFh";
BA_ "GenSigCycleTime" SG_ 1001 VC_MaxLdPressFtTr 2000;
BA_ "GenSigSendType" SG_ 1001 VC_MaxLdPressFtTr 5;
BA_ "GenSigSNA" SG_ 1001 VC_MaseratiMd "3h";
BA_ "FlexKomIsMotorola" SG_ 1001 VC_MaseratiMd 1;
BA_ "FlexKomComment" SG_ 1001 VC_MaseratiMd "Vehicle Configuration 2 Packet";
BA_ "FlexKomSigName" SG_ 1001 VC_MaseratiMd "VehCfg2_Pkt";
BA_ "FlexKomSigLaenge" SG_ 1001 VC_MaseratiMd 64;
BA_ "FlexKomSigStartPos" SG_ 1001 VC_MaseratiMd 7;
BA_ "FlexKomSID" SG_ 1001 VC_MaseratiMd 887;
BA_ "FlexKomSigStartValue" SG_ 1001 VC_MaseratiMd "0300FF00FFFFFFFFh";
BA_ "GenSigCycleTime" SG_ 1001 VC_MaseratiMd 2000;
BA_ "GenSigSendType" SG_ 1001 VC_MaseratiMd 5;
BA_ "GenSigSNA" SG_ 1001 VC_LgtLdPressRrTr "FFh";
BA_ "FlexKomIsMotorola" SG_ 1001 VC_LgtLdPressRrTr 1;
BA_ "FlexKomComment" SG_ 1001 VC_LgtLdPressRrTr "Vehicle Configuration 2 Packet";
BA_ "FlexKomSigName" SG_ 1001 VC_LgtLdPressRrTr "VehCfg2_Pkt";
BA_ "FlexKomSigLaenge" SG_ 1001 VC_LgtLdPressRrTr 64;
BA_ "FlexKomSigStartPos" SG_ 1001 VC_LgtLdPressRrTr 7;
BA_ "FlexKomSID" SG_ 1001 VC_LgtLdPressRrTr 887;
BA_ "GenSigTimeout_IC" SG_ 1001 VC_LgtLdPressRrTr 21000;
BA_ "GenSigStartValue" SG_ 1001 VC_LgtLdPressRrTr 255;
BA_ "FlexKomSigStartValue" SG_ 1001 VC_LgtLdPressRrTr "0300FF00FFFFFFFFh";
BA_ "GenSigCycleTime" SG_ 1001 VC_LgtLdPressRrTr 2000;
BA_ "GenSigSendType" SG_ 1001 VC_LgtLdPressRrTr 5;
BA_ "GenSigSNA" SG_ 1001 VC_LgtLdPressFtTr "FFh";
BA_ "FlexKomIsMotorola" SG_ 1001 VC_LgtLdPressFtTr 1;
BA_ "FlexKomComment" SG_ 1001 VC_LgtLdPressFtTr "Vehicle Configuration 2 Packet";
BA_ "FlexKomSigName" SG_ 1001 VC_LgtLdPressFtTr "VehCfg2_Pkt";
BA_ "FlexKomSigLaenge" SG_ 1001 VC_LgtLdPressFtTr 64;
BA_ "FlexKomSigStartPos" SG_ 1001 VC_LgtLdPressFtTr 7;
BA_ "FlexKomSID" SG_ 1001 VC_LgtLdPressFtTr 887;
BA_ "GenSigTimeout_IC" SG_ 1001 VC_LgtLdPressFtTr 21000;
BA_ "GenSigStartValue" SG_ 1001 VC_LgtLdPressFtTr 255;
BA_ "FlexKomSigStartValue" SG_ 1001 VC_LgtLdPressFtTr "0300FF00FFFFFFFFh";
BA_ "GenSigCycleTime" SG_ 1001 VC_LgtLdPressFtTr 2000;
BA_ "GenSigSendType" SG_ 1001 VC_LgtLdPressFtTr 5;
BA_ "GenSigSNA" SG_ 1001 VC_FULL_SPARE "0h";
BA_ "FlexKomIsMotorola" SG_ 1001 VC_FULL_SPARE 1;
BA_ "FlexKomComment" SG_ 1001 VC_FULL_SPARE "Vehicle Configuration 2 Packet";
BA_ "FlexKomSigName" SG_ 1001 VC_FULL_SPARE "VehCfg2_Pkt";
BA_ "FlexKomSigLaenge" SG_ 1001 VC_FULL_SPARE 64;
BA_ "FlexKomSigStartPos" SG_ 1001 VC_FULL_SPARE 7;
BA_ "FlexKomSID" SG_ 1001 VC_FULL_SPARE 887;
BA_ "FlexKomSigStartValue" SG_ 1001 VC_FULL_SPARE "0300FF00FFFFFFFFh";
BA_ "GenSigCycleTime" SG_ 1001 VC_FULL_SPARE 2000;
BA_ "GenSigSendType" SG_ 1001 VC_FULL_SPARE 5;
BA_ "GenSigSNA" SG_ 1001 VC_FG_PRSNT "0h";
BA_ "FlexKomIsMotorola" SG_ 1001 VC_FG_PRSNT 1;
BA_ "FlexKomComment" SG_ 1001 VC_FG_PRSNT "Vehicle Configuration 2 Packet";
BA_ "FlexKomSigName" SG_ 1001 VC_FG_PRSNT "VehCfg2_Pkt";
BA_ "FlexKomSigLaenge" SG_ 1001 VC_FG_PRSNT 64;
BA_ "FlexKomSigStartPos" SG_ 1001 VC_FG_PRSNT 7;
BA_ "FlexKomSID" SG_ 1001 VC_FG_PRSNT 887;
BA_ "GenSigTimeout_IC" SG_ 1001 VC_FG_PRSNT 21000;
BA_ "FlexKomSigStartValue" SG_ 1001 VC_FG_PRSNT "0300FF00FFFFFFFFh";
BA_ "GenSigCycleTime" SG_ 1001 VC_FG_PRSNT 2000;
BA_ "GenSigSendType" SG_ 1001 VC_FG_PRSNT 5;
BA_ "GenSigSNA" SG_ 1001 VC_ESCDrvMd_Prsnt "0h";
BA_ "FlexKomIsMotorola" SG_ 1001 VC_ESCDrvMd_Prsnt 1;
BA_ "FlexKomComment" SG_ 1001 VC_ESCDrvMd_Prsnt "Vehicle Configuration 2 Packet";
BA_ "FlexKomSigName" SG_ 1001 VC_ESCDrvMd_Prsnt "VehCfg2_Pkt";
BA_ "FlexKomSigLaenge" SG_ 1001 VC_ESCDrvMd_Prsnt 64;
BA_ "FlexKomSigStartPos" SG_ 1001 VC_ESCDrvMd_Prsnt 7;
BA_ "FlexKomSID" SG_ 1001 VC_ESCDrvMd_Prsnt 887;
BA_ "GenSigTimeout_IC" SG_ 1001 VC_ESCDrvMd_Prsnt 21000;
BA_ "FlexKomSigStartValue" SG_ 1001 VC_ESCDrvMd_Prsnt "0300FF00FFFFFFFFh";
BA_ "GenSigCycleTime" SG_ 1001 VC_ESCDrvMd_Prsnt 2000;
BA_ "GenSigSendType" SG_ 1001 VC_ESCDrvMd_Prsnt 5;
BA_ "GenSigSNA" SG_ 1001 VC_EngPowerDrvMd_Prsnt "0h";
BA_ "FlexKomIsMotorola" SG_ 1001 VC_EngPowerDrvMd_Prsnt 1;
BA_ "FlexKomComment" SG_ 1001 VC_EngPowerDrvMd_Prsnt "Vehicle Configuration 2 Packet";
BA_ "FlexKomSigName" SG_ 1001 VC_EngPowerDrvMd_Prsnt "VehCfg2_Pkt";
BA_ "FlexKomSigLaenge" SG_ 1001 VC_EngPowerDrvMd_Prsnt 64;
BA_ "FlexKomSigStartPos" SG_ 1001 VC_EngPowerDrvMd_Prsnt 7;
BA_ "FlexKomSID" SG_ 1001 VC_EngPowerDrvMd_Prsnt 887;
BA_ "GenSigTimeout_IC" SG_ 1001 VC_EngPowerDrvMd_Prsnt 21000;
BA_ "FlexKomSigStartValue" SG_ 1001 VC_EngPowerDrvMd_Prsnt "0300FF00FFFFFFFFh";
BA_ "GenSigCycleTime" SG_ 1001 VC_EngPowerDrvMd_Prsnt 2000;
BA_ "GenSigSendType" SG_ 1001 VC_EngPowerDrvMd_Prsnt 5;
BA_ "GenSigSNA" SG_ 1001 VC_ECO_Indicator "0h";
BA_ "FlexKomIsMotorola" SG_ 1001 VC_ECO_Indicator 1;
BA_ "FlexKomComment" SG_ 1001 VC_ECO_Indicator "Vehicle Configuration 2 Packet";
BA_ "FlexKomSigName" SG_ 1001 VC_ECO_Indicator "VehCfg2_Pkt";
BA_ "FlexKomSigLaenge" SG_ 1001 VC_ECO_Indicator 64;
BA_ "FlexKomSigStartPos" SG_ 1001 VC_ECO_Indicator 7;
BA_ "FlexKomSID" SG_ 1001 VC_ECO_Indicator 887;
BA_ "GenSigTimeout_IC" SG_ 1001 VC_ECO_Indicator 21000;
BA_ "FlexKomSigStartValue" SG_ 1001 VC_ECO_Indicator "0300FF00FFFFFFFFh";
BA_ "GenSigCycleTime" SG_ 1001 VC_ECO_Indicator 2000;
BA_ "GenSigSendType" SG_ 1001 VC_ECO_Indicator 5;
BA_ "GenSigSNA" SG_ 1001 VC_DRVMD_Prsnt "0h";
BA_ "FlexKomIsMotorola" SG_ 1001 VC_DRVMD_Prsnt 1;
BA_ "FlexKomComment" SG_ 1001 VC_DRVMD_Prsnt "Vehicle Configuration 2 Packet";
BA_ "FlexKomSigName" SG_ 1001 VC_DRVMD_Prsnt "VehCfg2_Pkt";
BA_ "FlexKomSigLaenge" SG_ 1001 VC_DRVMD_Prsnt 64;
BA_ "FlexKomSigStartPos" SG_ 1001 VC_DRVMD_Prsnt 7;
BA_ "FlexKomSID" SG_ 1001 VC_DRVMD_Prsnt 887;
BA_ "GenSigTimeout_EPS" SG_ 1001 VC_DRVMD_Prsnt 21000;
BA_ "FlexKomSigStartValue" SG_ 1001 VC_DRVMD_Prsnt "0300FF00FFFFFFFFh";
BA_ "GenSigCycleTime" SG_ 1001 VC_DRVMD_Prsnt 2000;
BA_ "GenSigSendType" SG_ 1001 VC_DRVMD_Prsnt 5;
BA_ "GenSigSNA" SG_ 1001 VC_CRUISE_PRSNT "0h";
BA_ "FlexKomIsMotorola" SG_ 1001 VC_CRUISE_PRSNT 1;
BA_ "FlexKomComment" SG_ 1001 VC_CRUISE_PRSNT "Vehicle Configuration 2 Packet";
BA_ "FlexKomSigName" SG_ 1001 VC_CRUISE_PRSNT "VehCfg2_Pkt";
BA_ "FlexKomSigLaenge" SG_ 1001 VC_CRUISE_PRSNT 64;
BA_ "FlexKomSigStartPos" SG_ 1001 VC_CRUISE_PRSNT 7;
BA_ "FlexKomSID" SG_ 1001 VC_CRUISE_PRSNT 887;
BA_ "GenSigTimeout_ORC" SG_ 1001 VC_CRUISE_PRSNT 7000;
BA_ "GenSigTimeout_IC" SG_ 1001 VC_CRUISE_PRSNT 21000;
BA_ "FlexKomSigStartValue" SG_ 1001 VC_CRUISE_PRSNT "0300FF00FFFFFFFFh";
BA_ "GenSigCycleTime" SG_ 1001 VC_CRUISE_PRSNT 2000;
BA_ "GenSigSendType" SG_ 1001 VC_CRUISE_PRSNT 5;
BA_ "GenSigSNA" SG_ 1001 VC_AC_Prsnt "0h";
BA_ "FlexKomIsMotorola" SG_ 1001 VC_AC_Prsnt 1;
BA_ "FlexKomComment" SG_ 1001 VC_AC_Prsnt "Vehicle Configuration 2 Packet";
BA_ "FlexKomSigName" SG_ 1001 VC_AC_Prsnt "VehCfg2_Pkt";
BA_ "FlexKomSigLaenge" SG_ 1001 VC_AC_Prsnt 64;
BA_ "FlexKomSigStartPos" SG_ 1001 VC_AC_Prsnt 7;
BA_ "FlexKomSID" SG_ 1001 VC_AC_Prsnt 887;
BA_ "FlexKomSigStartValue" SG_ 1001 VC_AC_Prsnt "0300FF00FFFFFFFFh";
BA_ "GenSigCycleTime" SG_ 1001 VC_AC_Prsnt 2000;
BA_ "GenSigSendType" SG_ 1001 VC_AC_Prsnt 5;
BA_ "GenMsgStartDelayTime" BO_ 1000 50;
BA_ "GenMsgStartValue" BO_ 1000 "FFFF7FF0FF0FFF00h";
BA_ "GenMsgNrOfRepetitions" BO_ 1000 2;
BA_ "GenMsgDelayTime" BO_ 1000 20;
BA_ "GenMsgCycleTime" BO_ 1000 500;
BA_ "GenMsgSendType" BO_ 1000 5;
BA_ "GenSigSNA" SG_ 1000 VC_XWD "0h";
BA_ "FlexKomIsMotorola" SG_ 1000 VC_XWD 1;
BA_ "FlexKomComment" SG_ 1000 VC_XWD "Vehicle Configuration 1 Packet";
BA_ "FlexKomSigName" SG_ 1000 VC_XWD "VehCfg1_Pkt";
BA_ "FlexKomSigLaenge" SG_ 1000 VC_XWD 64;
BA_ "FlexKomSigStartPos" SG_ 1000 VC_XWD 7;
BA_ "FlexKomSID" SG_ 1000 VC_XWD 886;
BA_ "GenSigTimeout_ORC" SG_ 1000 VC_XWD 1750;
BA_ "GenSigTimeout_ESM" SG_ 1000 VC_XWD 5250;
BA_ "GenSigTimeout_IC" SG_ 1000 VC_XWD 5250;
BA_ "FlexKomSigStartValue" SG_ 1000 VC_XWD "FFFF7FF0FF0FFF00h";
BA_ "GenSigCycleTime" SG_ 1000 VC_XWD 500;
BA_ "GenSigSendType" SG_ 1000 VC_XWD 5;
BA_ "GenSigSNA" SG_ 1000 VC_VehCfg1_Stat "3h";
BA_ "FlexKomIsMotorola" SG_ 1000 VC_VehCfg1_Stat 1;
BA_ "FlexKomComment" SG_ 1000 VC_VehCfg1_Stat "Vehicle Configuration 1 Packet";
BA_ "FlexKomSigName" SG_ 1000 VC_VehCfg1_Stat "VehCfg1_Pkt";
BA_ "FlexKomSigLaenge" SG_ 1000 VC_VehCfg1_Stat 64;
BA_ "FlexKomSigStartPos" SG_ 1000 VC_VehCfg1_Stat 7;
BA_ "FlexKomSID" SG_ 1000 VC_VehCfg1_Stat 886;
BA_ "GenSigTimeout_OCM" SG_ 1000 VC_VehCfg1_Stat 5250;
BA_ "GenSigTimeout_ORC" SG_ 1000 VC_VehCfg1_Stat 1750;
BA_ "GenSigTimeout_ESM" SG_ 1000 VC_VehCfg1_Stat 5250;
BA_ "GenSigTimeout_SCCM" SG_ 1000 VC_VehCfg1_Stat 5250;
BA_ "GenSigTimeout_EPS" SG_ 1000 VC_VehCfg1_Stat 5250;
BA_ "GenSigTimeout_IC" SG_ 1000 VC_VehCfg1_Stat 5250;
BA_ "GenSigStartValue" SG_ 1000 VC_VehCfg1_Stat 3;
BA_ "FlexKomSigStartValue" SG_ 1000 VC_VehCfg1_Stat "FFFF7FF0FF0FFF00h";
BA_ "GenSigCycleTime" SG_ 1000 VC_VehCfg1_Stat 500;
BA_ "GenSigSendType" SG_ 1000 VC_VehCfg1_Stat 5;
BA_ "GenSigSNA" SG_ 1000 VC_VEH_LINE "FFh";
BA_ "FlexKomIsMotorola" SG_ 1000 VC_VEH_LINE 1;
BA_ "FlexKomComment" SG_ 1000 VC_VEH_LINE "Vehicle Configuration 1 Packet";
BA_ "FlexKomSigName" SG_ 1000 VC_VEH_LINE "VehCfg1_Pkt";
BA_ "FlexKomSigLaenge" SG_ 1000 VC_VEH_LINE 64;
BA_ "FlexKomSigStartPos" SG_ 1000 VC_VEH_LINE 7;
BA_ "FlexKomSID" SG_ 1000 VC_VEH_LINE 886;
BA_ "GenSigTimeout_OCM" SG_ 1000 VC_VEH_LINE 2750;
BA_ "GenSigTimeout_ORC" SG_ 1000 VC_VEH_LINE 1750;
BA_ "GenSigTimeout_ESM" SG_ 1000 VC_VEH_LINE 5250;
BA_ "GenSigTimeout_SCCM" SG_ 1000 VC_VEH_LINE 5250;
BA_ "GenSigTimeout_EPS" SG_ 1000 VC_VEH_LINE 5250;
BA_ "GenSigTimeout_IC" SG_ 1000 VC_VEH_LINE 5250;
BA_ "GenSigStartValue" SG_ 1000 VC_VEH_LINE 255;
BA_ "FlexKomSigStartValue" SG_ 1000 VC_VEH_LINE "FFFF7FF0FF0FFF00h";
BA_ "GenSigCycleTime" SG_ 1000 VC_VEH_LINE 500;
BA_ "GenSigSendType" SG_ 1000 VC_VEH_LINE 5;
BA_ "GenSigSNA" SG_ 1000 VC_SSC_Prsnt "0h";
BA_ "FlexKomIsMotorola" SG_ 1000 VC_SSC_Prsnt 1;
BA_ "FlexKomComment" SG_ 1000 VC_SSC_Prsnt "Vehicle Configuration 1 Packet";
BA_ "FlexKomSigName" SG_ 1000 VC_SSC_Prsnt "VehCfg1_Pkt";
BA_ "FlexKomSigLaenge" SG_ 1000 VC_SSC_Prsnt 64;
BA_ "FlexKomSigStartPos" SG_ 1000 VC_SSC_Prsnt 7;
BA_ "FlexKomSID" SG_ 1000 VC_SSC_Prsnt 886;
BA_ "GenSigTimeout_IC" SG_ 1000 VC_SSC_Prsnt 5250;
BA_ "FlexKomSigStartValue" SG_ 1000 VC_SSC_Prsnt "FFFF7FF0FF0FFF00h";
BA_ "GenSigCycleTime" SG_ 1000 VC_SSC_Prsnt 500;
BA_ "GenSigSendType" SG_ 1000 VC_SSC_Prsnt 5;
BA_ "GenSigSNA" SG_ 1000 VC_SpecialPKG "FFh";
BA_ "FlexKomIsMotorola" SG_ 1000 VC_SpecialPKG 1;
BA_ "FlexKomComment" SG_ 1000 VC_SpecialPKG "Vehicle Configuration 1 Packet";
BA_ "FlexKomSigName" SG_ 1000 VC_SpecialPKG "VehCfg1_Pkt";
BA_ "FlexKomSigLaenge" SG_ 1000 VC_SpecialPKG 64;
BA_ "FlexKomSigStartPos" SG_ 1000 VC_SpecialPKG 7;
BA_ "FlexKomSID" SG_ 1000 VC_SpecialPKG 886;
BA_ "GenSigTimeout_ORC" SG_ 1000 VC_SpecialPKG 1750;
BA_ "GenSigTimeout_IC" SG_ 1000 VC_SpecialPKG 5250;
BA_ "GenSigStartValue" SG_ 1000 VC_SpecialPKG 255;
BA_ "FlexKomSigStartValue" SG_ 1000 VC_SpecialPKG "FFFF7FF0FF0FFF00h";
BA_ "GenSigCycleTime" SG_ 1000 VC_SpecialPKG 500;
BA_ "GenSigSendType" SG_ 1000 VC_SpecialPKG 5;
BA_ "GenSigSNA" SG_ 1000 VC_ShftrTyp "Fh";
BA_ "FlexKomIsMotorola" SG_ 1000 VC_ShftrTyp 1;
BA_ "FlexKomComment" SG_ 1000 VC_ShftrTyp "Vehicle Configuration 1 Packet";
BA_ "FlexKomSigName" SG_ 1000 VC_ShftrTyp "VehCfg1_Pkt";
BA_ "FlexKomSigLaenge" SG_ 1000 VC_ShftrTyp 64;
BA_ "FlexKomSigStartPos" SG_ 1000 VC_ShftrTyp 7;
BA_ "FlexKomSID" SG_ 1000 VC_ShftrTyp 886;
BA_ "GenSigTimeout_ESM" SG_ 1000 VC_ShftrTyp 5250;
BA_ "GenSigTimeout_IC" SG_ 1000 VC_ShftrTyp 5250;
BA_ "GenSigStartValue" SG_ 1000 VC_ShftrTyp 15;
BA_ "FlexKomSigStartValue" SG_ 1000 VC_ShftrTyp "FFFF7FF0FF0FFF00h";
BA_ "GenSigCycleTime" SG_ 1000 VC_ShftrTyp 500;
BA_ "GenSigSendType" SG_ 1000 VC_ShftrTyp 5;
BA_ "GenSigSNA" SG_ 1000 VC_SCR_Prsnt "0h";
BA_ "FlexKomIsMotorola" SG_ 1000 VC_SCR_Prsnt 1;
BA_ "FlexKomComment" SG_ 1000 VC_SCR_Prsnt "Vehicle Configuration 1 Packet";
BA_ "FlexKomSigName" SG_ 1000 VC_SCR_Prsnt "VehCfg1_Pkt";
BA_ "FlexKomSigLaenge" SG_ 1000 VC_SCR_Prsnt 64;
BA_ "FlexKomSigStartPos" SG_ 1000 VC_SCR_Prsnt 7;
BA_ "FlexKomSID" SG_ 1000 VC_SCR_Prsnt 886;
BA_ "GenSigTimeout_IC" SG_ 1000 VC_SCR_Prsnt 5250;
BA_ "FlexKomSigStartValue" SG_ 1000 VC_SCR_Prsnt "FFFF7FF0FF0FFF00h";
BA_ "GenSigCycleTime" SG_ 1000 VC_SCR_Prsnt 500;
BA_ "GenSigSendType" SG_ 1000 VC_SCR_Prsnt 5;
BA_ "GenSigSNA" SG_ 1000 VC_RVCM_Prsnt "0h";
BA_ "FlexKomIsMotorola" SG_ 1000 VC_RVCM_Prsnt 1;
BA_ "FlexKomComment" SG_ 1000 VC_RVCM_Prsnt "Vehicle Configuration 1 Packet";
BA_ "FlexKomSigName" SG_ 1000 VC_RVCM_Prsnt "VehCfg1_Pkt";
BA_ "FlexKomSigLaenge" SG_ 1000 VC_RVCM_Prsnt 64;
BA_ "FlexKomSigStartPos" SG_ 1000 VC_RVCM_Prsnt 7;
BA_ "FlexKomSID" SG_ 1000 VC_RVCM_Prsnt 886;
BA_ "FlexKomSigStartValue" SG_ 1000 VC_RVCM_Prsnt "FFFF7FF0FF0FFF00h";
BA_ "GenSigCycleTime" SG_ 1000 VC_RVCM_Prsnt 500;
BA_ "GenSigSendType" SG_ 1000 VC_RVCM_Prsnt 5;
BA_ "GenSigSNA" SG_ 1000 VC_RemStPrsnt "0h";
BA_ "FlexKomIsMotorola" SG_ 1000 VC_RemStPrsnt 1;
BA_ "FlexKomComment" SG_ 1000 VC_RemStPrsnt "Vehicle Configuration 1 Packet";
BA_ "FlexKomSigName" SG_ 1000 VC_RemStPrsnt "VehCfg1_Pkt";
BA_ "FlexKomSigLaenge" SG_ 1000 VC_RemStPrsnt 64;
BA_ "FlexKomSigStartPos" SG_ 1000 VC_RemStPrsnt 7;
BA_ "FlexKomSID" SG_ 1000 VC_RemStPrsnt 886;
BA_ "GenSigTimeout_IC" SG_ 1000 VC_RemStPrsnt 5250;
BA_ "FlexKomSigStartValue" SG_ 1000 VC_RemStPrsnt "FFFF7FF0FF0FFF00h";
BA_ "GenSigCycleTime" SG_ 1000 VC_RemStPrsnt 500;
BA_ "GenSigSendType" SG_ 1000 VC_RemStPrsnt 5;
BA_ "GenSigSNA" SG_ 1000 VC_PTS_DispTyp "7h";
BA_ "FlexKomIsMotorola" SG_ 1000 VC_PTS_DispTyp 1;
BA_ "FlexKomComment" SG_ 1000 VC_PTS_DispTyp "Vehicle Configuration 1 Packet";
BA_ "FlexKomSigName" SG_ 1000 VC_PTS_DispTyp "VehCfg1_Pkt";
BA_ "FlexKomSigLaenge" SG_ 1000 VC_PTS_DispTyp 64;
BA_ "FlexKomSigStartPos" SG_ 1000 VC_PTS_DispTyp 7;
BA_ "FlexKomSID" SG_ 1000 VC_PTS_DispTyp 886;
BA_ "GenSigTimeout_PTS" SG_ 1000 VC_PTS_DispTyp 2750;
BA_ "FlexKomSigStartValue" SG_ 1000 VC_PTS_DispTyp "FFFF7FF0FF0FFF00h";
BA_ "GenSigCycleTime" SG_ 1000 VC_PTS_DispTyp 500;
BA_ "GenSigSendType" SG_ 1000 VC_PTS_DispTyp 5;
BA_ "GenSigSNA" SG_ 1000 VC_PTS_Config "0h";
BA_ "FlexKomIsMotorola" SG_ 1000 VC_PTS_Config 1;
BA_ "FlexKomComment" SG_ 1000 VC_PTS_Config "Vehicle Configuration 1 Packet";
BA_ "FlexKomSigName" SG_ 1000 VC_PTS_Config "VehCfg1_Pkt";
BA_ "FlexKomSigLaenge" SG_ 1000 VC_PTS_Config 64;
BA_ "FlexKomSigStartPos" SG_ 1000 VC_PTS_Config 7;
BA_ "FlexKomSID" SG_ 1000 VC_PTS_Config 886;
BA_ "GenSigTimeout_PTS" SG_ 1000 VC_PTS_Config 2750;
BA_ "GenSigTimeout_IC" SG_ 1000 VC_PTS_Config 5250;
BA_ "FlexKomSigStartValue" SG_ 1000 VC_PTS_Config "FFFF7FF0FF0FFF00h";
BA_ "GenSigCycleTime" SG_ 1000 VC_PTS_Config 500;
BA_ "GenSigSendType" SG_ 1000 VC_PTS_Config 5;
BA_ "GenSigSNA" SG_ 1000 VC_PP_Prsnt "0h";
BA_ "FlexKomIsMotorola" SG_ 1000 VC_PP_Prsnt 1;
BA_ "FlexKomComment" SG_ 1000 VC_PP_Prsnt "Vehicle Configuration 1 Packet";
BA_ "FlexKomSigName" SG_ 1000 VC_PP_Prsnt "VehCfg1_Pkt";
BA_ "FlexKomSigLaenge" SG_ 1000 VC_PP_Prsnt 64;
BA_ "FlexKomSigStartPos" SG_ 1000 VC_PP_Prsnt 7;
BA_ "FlexKomSID" SG_ 1000 VC_PP_Prsnt 886;
BA_ "GenSigTimeout_IC" SG_ 1000 VC_PP_Prsnt 5250;
BA_ "FlexKomSigStartValue" SG_ 1000 VC_PP_Prsnt "FFFF7FF0FF0FFF00h";
BA_ "GenSigCycleTime" SG_ 1000 VC_PP_Prsnt 500;
BA_ "GenSigSendType" SG_ 1000 VC_PP_Prsnt 5;
BA_ "GenSigSNA" SG_ 1000 VC_MODEL_YEAR "3Fh";
BA_ "FlexKomIsMotorola" SG_ 1000 VC_MODEL_YEAR 1;
BA_ "FlexKomComment" SG_ 1000 VC_MODEL_YEAR "Vehicle Configuration 1 Packet";
BA_ "FlexKomSigName" SG_ 1000 VC_MODEL_YEAR "VehCfg1_Pkt";
BA_ "FlexKomSigLaenge" SG_ 1000 VC_MODEL_YEAR 64;
BA_ "FlexKomSigStartPos" SG_ 1000 VC_MODEL_YEAR 7;
BA_ "FlexKomSID" SG_ 1000 VC_MODEL_YEAR 886;
BA_ "GenSigTimeout_ORC" SG_ 1000 VC_MODEL_YEAR 1750;
BA_ "GenSigTimeout_ESM" SG_ 1000 VC_MODEL_YEAR 5250;
BA_ "GenSigTimeout_SCCM" SG_ 1000 VC_MODEL_YEAR 5250;
BA_ "GenSigTimeout_EPS" SG_ 1000 VC_MODEL_YEAR 5250;
BA_ "GenSigTimeout_IC" SG_ 1000 VC_MODEL_YEAR 5250;
BA_ "GenSigStartValue" SG_ 1000 VC_MODEL_YEAR 63;
BA_ "FlexKomSigStartValue" SG_ 1000 VC_MODEL_YEAR "FFFF7FF0FF0FFF00h";
BA_ "GenSigCycleTime" SG_ 1000 VC_MODEL_YEAR 500;
BA_ "GenSigSendType" SG_ 1000 VC_MODEL_YEAR 5;
BA_ "GenSigSNA" SG_ 1000 VC_MAX_VEH_SPD "FFh";
BA_ "FlexKomIsMotorola" SG_ 1000 VC_MAX_VEH_SPD 1;
BA_ "FlexKomComment" SG_ 1000 VC_MAX_VEH_SPD "Vehicle Configuration 1 Packet";
BA_ "FlexKomSigName" SG_ 1000 VC_MAX_VEH_SPD "VehCfg1_Pkt";
BA_ "FlexKomSigLaenge" SG_ 1000 VC_MAX_VEH_SPD 64;
BA_ "FlexKomSigStartPos" SG_ 1000 VC_MAX_VEH_SPD 7;
BA_ "FlexKomSID" SG_ 1000 VC_MAX_VEH_SPD 886;
BA_ "GenSigStartValue" SG_ 1000 VC_MAX_VEH_SPD 255;
BA_ "FlexKomSigStartValue" SG_ 1000 VC_MAX_VEH_SPD "FFFF7FF0FF0FFF00h";
BA_ "GenSigCycleTime" SG_ 1000 VC_MAX_VEH_SPD 500;
BA_ "GenSigSendType" SG_ 1000 VC_MAX_VEH_SPD 5;
BA_ "GenSigSNA" SG_ 1000 VC_LHD_RHD "3h";
BA_ "FlexKomIsMotorola" SG_ 1000 VC_LHD_RHD 1;
BA_ "FlexKomComment" SG_ 1000 VC_LHD_RHD "Vehicle Configuration 1 Packet";
BA_ "FlexKomSigName" SG_ 1000 VC_LHD_RHD "VehCfg1_Pkt";
BA_ "FlexKomSigLaenge" SG_ 1000 VC_LHD_RHD 64;
BA_ "FlexKomSigStartPos" SG_ 1000 VC_LHD_RHD 7;
BA_ "FlexKomSID" SG_ 1000 VC_LHD_RHD 886;
BA_ "GenSigTimeout_ORC" SG_ 1000 VC_LHD_RHD 1750;
BA_ "GenSigTimeout_ESM" SG_ 1000 VC_LHD_RHD 5250;
BA_ "GenSigTimeout_IC" SG_ 1000 VC_LHD_RHD 5250;
BA_ "GenSigStartValue" SG_ 1000 VC_LHD_RHD 3;
BA_ "FlexKomSigStartValue" SG_ 1000 VC_LHD_RHD "FFFF7FF0FF0FFF00h";
BA_ "GenSigCycleTime" SG_ 1000 VC_LHD_RHD 500;
BA_ "GenSigSendType" SG_ 1000 VC_LHD_RHD 5;
BA_ "GenSigSNA" SG_ 1000 VC_HdRstPrsnt "0h";
BA_ "FlexKomIsMotorola" SG_ 1000 VC_HdRstPrsnt 1;
BA_ "FlexKomComment" SG_ 1000 VC_HdRstPrsnt "Vehicle Configuration 1 Packet";
BA_ "FlexKomSigName" SG_ 1000 VC_HdRstPrsnt "VehCfg1_Pkt";
BA_ "FlexKomSigLaenge" SG_ 1000 VC_HdRstPrsnt 64;
BA_ "FlexKomSigStartPos" SG_ 1000 VC_HdRstPrsnt 7;
BA_ "FlexKomSID" SG_ 1000 VC_HdRstPrsnt 886;
BA_ "FlexKomSigStartValue" SG_ 1000 VC_HdRstPrsnt "FFFF7FF0FF0FFF00h";
BA_ "GenSigCycleTime" SG_ 1000 VC_HdRstPrsnt 500;
BA_ "GenSigSendType" SG_ 1000 VC_HdRstPrsnt 5;
BA_ "GenSigSNA" SG_ 1000 VC_HDC_Prsnt "0h";
BA_ "FlexKomIsMotorola" SG_ 1000 VC_HDC_Prsnt 1;
BA_ "FlexKomComment" SG_ 1000 VC_HDC_Prsnt "Vehicle Configuration 1 Packet";
BA_ "FlexKomSigName" SG_ 1000 VC_HDC_Prsnt "VehCfg1_Pkt";
BA_ "FlexKomSigLaenge" SG_ 1000 VC_HDC_Prsnt 64;
BA_ "FlexKomSigStartPos" SG_ 1000 VC_HDC_Prsnt 7;
BA_ "FlexKomSID" SG_ 1000 VC_HDC_Prsnt 886;
BA_ "GenSigTimeout_IC" SG_ 1000 VC_HDC_Prsnt 5250;
BA_ "FlexKomSigStartValue" SG_ 1000 VC_HDC_Prsnt "FFFF7FF0FF0FFF00h";
BA_ "GenSigCycleTime" SG_ 1000 VC_HDC_Prsnt 500;
BA_ "GenSigSendType" SG_ 1000 VC_HDC_Prsnt 5;
BA_ "GenSigSNA" SG_ 1000 VC_EmodePrsnt "0h";
BA_ "FlexKomIsMotorola" SG_ 1000 VC_EmodePrsnt 1;
BA_ "FlexKomComment" SG_ 1000 VC_EmodePrsnt "Vehicle Configuration 1 Packet";
BA_ "FlexKomSigName" SG_ 1000 VC_EmodePrsnt "VehCfg1_Pkt";
BA_ "FlexKomSigLaenge" SG_ 1000 VC_EmodePrsnt 64;
BA_ "FlexKomSigStartPos" SG_ 1000 VC_EmodePrsnt 7;
BA_ "FlexKomSID" SG_ 1000 VC_EmodePrsnt 886;
BA_ "FlexKomSigStartValue" SG_ 1000 VC_EmodePrsnt "FFFF7FF0FF0FFF00h";
BA_ "GenSigCycleTime" SG_ 1000 VC_EmodePrsnt 500;
BA_ "GenSigSendType" SG_ 1000 VC_EmodePrsnt 5;
BA_ "GenSigSNA" SG_ 1000 VC_COUNTRY "1Fh";
BA_ "FlexKomIsMotorola" SG_ 1000 VC_COUNTRY 1;
BA_ "FlexKomComment" SG_ 1000 VC_COUNTRY "Vehicle Configuration 1 Packet";
BA_ "FlexKomSigName" SG_ 1000 VC_COUNTRY "VehCfg1_Pkt";
BA_ "FlexKomSigLaenge" SG_ 1000 VC_COUNTRY 64;
BA_ "FlexKomSigStartPos" SG_ 1000 VC_COUNTRY 7;
BA_ "FlexKomSID" SG_ 1000 VC_COUNTRY 886;
BA_ "GenSigTimeout_ORC" SG_ 1000 VC_COUNTRY 1750;
BA_ "GenSigTimeout_ESM" SG_ 1000 VC_COUNTRY 5250;
BA_ "GenSigTimeout_SCCM" SG_ 1000 VC_COUNTRY 5250;
BA_ "GenSigTimeout_EPS" SG_ 1000 VC_COUNTRY 5250;
BA_ "GenSigTimeout_IC" SG_ 1000 VC_COUNTRY 5250;
BA_ "GenSigStartValue" SG_ 1000 VC_COUNTRY 31;
BA_ "FlexKomSigStartValue" SG_ 1000 VC_COUNTRY "FFFF7FF0FF0FFF00h";
BA_ "GenSigCycleTime" SG_ 1000 VC_COUNTRY 500;
BA_ "GenSigSendType" SG_ 1000 VC_COUNTRY 5;
BA_ "GenSigSNA" SG_ 1000 VC_CHMCM_Prsnt "0h";
BA_ "FlexKomIsMotorola" SG_ 1000 VC_CHMCM_Prsnt 1;
BA_ "FlexKomComment" SG_ 1000 VC_CHMCM_Prsnt "Vehicle Configuration 1 Packet";
BA_ "FlexKomSigName" SG_ 1000 VC_CHMCM_Prsnt "VehCfg1_Pkt";
BA_ "FlexKomSigLaenge" SG_ 1000 VC_CHMCM_Prsnt 64;
BA_ "FlexKomSigStartPos" SG_ 1000 VC_CHMCM_Prsnt 7;
BA_ "FlexKomSID" SG_ 1000 VC_CHMCM_Prsnt 886;
BA_ "FlexKomSigStartValue" SG_ 1000 VC_CHMCM_Prsnt "FFFF7FF0FF0FFF00h";
BA_ "GenSigCycleTime" SG_ 1000 VC_CHMCM_Prsnt 500;
BA_ "GenSigSendType" SG_ 1000 VC_CHMCM_Prsnt 5;
BA_ "GenSigSNA" SG_ 1000 VC_BODY_STYLE "Fh";
BA_ "FlexKomIsMotorola" SG_ 1000 VC_BODY_STYLE 1;
BA_ "FlexKomComment" SG_ 1000 VC_BODY_STYLE "Vehicle Configuration 1 Packet";
BA_ "FlexKomSigName" SG_ 1000 VC_BODY_STYLE "VehCfg1_Pkt";
BA_ "FlexKomSigLaenge" SG_ 1000 VC_BODY_STYLE 64;
BA_ "FlexKomSigStartPos" SG_ 1000 VC_BODY_STYLE 7;
BA_ "FlexKomSID" SG_ 1000 VC_BODY_STYLE 886;
BA_ "GenSigTimeout_ORC" SG_ 1000 VC_BODY_STYLE 1750;
BA_ "GenSigTimeout_ESM" SG_ 1000 VC_BODY_STYLE 5250;
BA_ "GenSigTimeout_SCCM" SG_ 1000 VC_BODY_STYLE 5250;
BA_ "GenSigTimeout_EPS" SG_ 1000 VC_BODY_STYLE 5250;
BA_ "GenSigTimeout_IC" SG_ 1000 VC_BODY_STYLE 5250;
BA_ "GenSigStartValue" SG_ 1000 VC_BODY_STYLE 15;
BA_ "FlexKomSigStartValue" SG_ 1000 VC_BODY_STYLE "FFFF7FF0FF0FFF00h";
BA_ "GenSigCycleTime" SG_ 1000 VC_BODY_STYLE 500;
BA_ "GenSigSendType" SG_ 1000 VC_BODY_STYLE 5;
BA_ "GenSigSNA" SG_ 1000 VC_AUTO_HB "0h";
BA_ "FlexKomIsMotorola" SG_ 1000 VC_AUTO_HB 1;
BA_ "FlexKomComment" SG_ 1000 VC_AUTO_HB "Vehicle Configuration 1 Packet";
BA_ "FlexKomSigName" SG_ 1000 VC_AUTO_HB "VehCfg1_Pkt";
BA_ "FlexKomSigLaenge" SG_ 1000 VC_AUTO_HB 64;
BA_ "FlexKomSigStartPos" SG_ 1000 VC_AUTO_HB 7;
BA_ "FlexKomSID" SG_ 1000 VC_AUTO_HB 886;
BA_ "GenSigTimeout_IC" SG_ 1000 VC_AUTO_HB 5250;
BA_ "FlexKomSigStartValue" SG_ 1000 VC_AUTO_HB "FFFF7FF0FF0FFF00h";
BA_ "GenSigCycleTime" SG_ 1000 VC_AUTO_HB 500;
BA_ "GenSigSendType" SG_ 1000 VC_AUTO_HB 5;
BA_ "GenMsgStartDelayTime" BO_ 996 10;
BA_ "GenMsgStartValue" BO_ 996 "0300000000000000h";
BA_ "GenMsgNrOfRepetitions" BO_ 996 2;
BA_ "GenMsgDelayTime" BO_ 996 20;
BA_ "GenMsgCycleTime" BO_ 996 2000;
BA_ "GenMsgSendType" BO_ 996 5;
BA_ "GenSigSNA" SG_ 996 NetCfg_VSIM_C "0h";
BA_ "FlexKomIsMotorola" SG_ 996 NetCfg_VSIM_C 1;
BA_ "FlexKomComment" SG_ 996 NetCfg_VSIM_C "Network ECU config data for Powertrain";
BA_ "FlexKomSigName" SG_ 996 NetCfg_VSIM_C "NET_CFG_DATA_PT";
BA_ "FlexKomSigLaenge" SG_ 996 NetCfg_VSIM_C 64;
BA_ "FlexKomSigStartPos" SG_ 996 NetCfg_VSIM_C 7;
BA_ "FlexKomSID" SG_ 996 NetCfg_VSIM_C 39;
BA_ "GenSigTimeout_IC" SG_ 996 NetCfg_VSIM_C 21000;
BA_ "FlexKomSigStartValue" SG_ 996 NetCfg_VSIM_C "0300000000000000h";
BA_ "GenSigCycleTime" SG_ 996 NetCfg_VSIM_C 2000;
BA_ "GenSigSendType" SG_ 996 NetCfg_VSIM_C 5;
BA_ "GenSigSNA" SG_ 996 NetCfg_TPM "0h";
BA_ "FlexKomIsMotorola" SG_ 996 NetCfg_TPM 1;
BA_ "FlexKomComment" SG_ 996 NetCfg_TPM "Network ECU config data for Powertrain";
BA_ "FlexKomSigName" SG_ 996 NetCfg_TPM "NET_CFG_DATA_PT";
BA_ "FlexKomSigLaenge" SG_ 996 NetCfg_TPM 64;
BA_ "FlexKomSigStartPos" SG_ 996 NetCfg_TPM 7;
BA_ "FlexKomSID" SG_ 996 NetCfg_TPM 39;
BA_ "GenSigTimeout_ORC" SG_ 996 NetCfg_TPM 7000;
BA_ "GenSigTimeout_IC" SG_ 996 NetCfg_TPM 21000;
BA_ "FlexKomSigStartValue" SG_ 996 NetCfg_TPM "0300000000000000h";
BA_ "GenSigCycleTime" SG_ 996 NetCfg_TPM 2000;
BA_ "GenSigSendType" SG_ 996 NetCfg_TPM 5;
BA_ "GenSigSNA" SG_ 996 NetCfg_TCM "0h";
BA_ "FlexKomIsMotorola" SG_ 996 NetCfg_TCM 1;
BA_ "FlexKomComment" SG_ 996 NetCfg_TCM "Network ECU config data for Powertrain";
BA_ "FlexKomSigName" SG_ 996 NetCfg_TCM "NET_CFG_DATA_PT";
BA_ "FlexKomSigLaenge" SG_ 996 NetCfg_TCM 64;
BA_ "FlexKomSigStartPos" SG_ 996 NetCfg_TCM 7;
BA_ "FlexKomSID" SG_ 996 NetCfg_TCM 39;
BA_ "GenSigTimeout_ORC" SG_ 996 NetCfg_TCM 7000;
BA_ "GenSigTimeout_ESM" SG_ 996 NetCfg_TCM 21000;
BA_ "GenSigTimeout_IC" SG_ 996 NetCfg_TCM 21000;
BA_ "FlexKomSigStartValue" SG_ 996 NetCfg_TCM "0300000000000000h";
BA_ "GenSigCycleTime" SG_ 996 NetCfg_TCM 2000;
BA_ "GenSigSendType" SG_ 996 NetCfg_TCM 5;
BA_ "GenSigSNA" SG_ 996 NetCfg_SCCM "0h";
BA_ "FlexKomIsMotorola" SG_ 996 NetCfg_SCCM 1;
BA_ "FlexKomComment" SG_ 996 NetCfg_SCCM "Network ECU config data for Powertrain";
BA_ "FlexKomSigName" SG_ 996 NetCfg_SCCM "NET_CFG_DATA_PT";
BA_ "FlexKomSigLaenge" SG_ 996 NetCfg_SCCM 64;
BA_ "FlexKomSigStartPos" SG_ 996 NetCfg_SCCM 7;
BA_ "FlexKomSID" SG_ 996 NetCfg_SCCM 39;
BA_ "GenSigTimeout_ORC" SG_ 996 NetCfg_SCCM 7000;
BA_ "GenSigTimeout_SCCM" SG_ 996 NetCfg_SCCM 21000;
BA_ "GenSigTimeout_EPS" SG_ 996 NetCfg_SCCM 21000;
BA_ "GenSigTimeout_IC" SG_ 996 NetCfg_SCCM 21000;
BA_ "FlexKomSigStartValue" SG_ 996 NetCfg_SCCM "0300000000000000h";
BA_ "GenSigCycleTime" SG_ 996 NetCfg_SCCM 2000;
BA_ "GenSigSendType" SG_ 996 NetCfg_SCCM 5;
BA_ "GenSigSNA" SG_ 996 NetCfg_RF_HUB "0h";
BA_ "FlexKomIsMotorola" SG_ 996 NetCfg_RF_HUB 1;
BA_ "FlexKomComment" SG_ 996 NetCfg_RF_HUB "Network ECU config data for Powertrain";
BA_ "FlexKomSigName" SG_ 996 NetCfg_RF_HUB "NET_CFG_DATA_PT";
BA_ "FlexKomSigLaenge" SG_ 996 NetCfg_RF_HUB 64;
BA_ "FlexKomSigStartPos" SG_ 996 NetCfg_RF_HUB 7;
BA_ "FlexKomSID" SG_ 996 NetCfg_RF_HUB 39;
BA_ "GenSigTimeout_IC" SG_ 996 NetCfg_RF_HUB 21000;
BA_ "FlexKomSigStartValue" SG_ 996 NetCfg_RF_HUB "0300000000000000h";
BA_ "GenSigCycleTime" SG_ 996 NetCfg_RF_HUB 2000;
BA_ "GenSigSendType" SG_ 996 NetCfg_RF_HUB 5;
BA_ "GenSigSNA" SG_ 996 NetCfg_PTS "0h";
BA_ "FlexKomIsMotorola" SG_ 996 NetCfg_PTS 1;
BA_ "FlexKomComment" SG_ 996 NetCfg_PTS "Network ECU config data for Powertrain";
BA_ "FlexKomSigName" SG_ 996 NetCfg_PTS "NET_CFG_DATA_PT";
BA_ "FlexKomSigLaenge" SG_ 996 NetCfg_PTS 64;
BA_ "FlexKomSigStartPos" SG_ 996 NetCfg_PTS 7;
BA_ "FlexKomSID" SG_ 996 NetCfg_PTS 39;
BA_ "GenSigTimeout_IC" SG_ 996 NetCfg_PTS 21000;
BA_ "FlexKomSigStartValue" SG_ 996 NetCfg_PTS "0300000000000000h";
BA_ "GenSigCycleTime" SG_ 996 NetCfg_PTS 2000;
BA_ "GenSigSendType" SG_ 996 NetCfg_PTS 5;
BA_ "GenSigSNA" SG_ 996 NetCfg_PASS_PT "0h";
BA_ "FlexKomIsMotorola" SG_ 996 NetCfg_PASS_PT 1;
BA_ "FlexKomComment" SG_ 996 NetCfg_PASS_PT "Network ECU config data for Powertrain";
BA_ "FlexKomSigName" SG_ 996 NetCfg_PASS_PT "NET_CFG_DATA_PT";
BA_ "FlexKomSigLaenge" SG_ 996 NetCfg_PASS_PT 64;
BA_ "FlexKomSigStartPos" SG_ 996 NetCfg_PASS_PT 7;
BA_ "FlexKomSID" SG_ 996 NetCfg_PASS_PT 39;
BA_ "GenSigTimeout_IC" SG_ 996 NetCfg_PASS_PT 21000;
BA_ "FlexKomSigStartValue" SG_ 996 NetCfg_PASS_PT "0300000000000000h";
BA_ "GenSigCycleTime" SG_ 996 NetCfg_PASS_PT 2000;
BA_ "GenSigSendType" SG_ 996 NetCfg_PASS_PT 5;
BA_ "GenSigSNA" SG_ 996 NetCfg_ORC "0h";
BA_ "FlexKomIsMotorola" SG_ 996 NetCfg_ORC 1;
BA_ "FlexKomComment" SG_ 996 NetCfg_ORC "Network ECU config data for Powertrain";
BA_ "FlexKomSigName" SG_ 996 NetCfg_ORC "NET_CFG_DATA_PT";
BA_ "FlexKomSigLaenge" SG_ 996 NetCfg_ORC 64;
BA_ "FlexKomSigStartPos" SG_ 996 NetCfg_ORC 7;
BA_ "FlexKomSID" SG_ 996 NetCfg_ORC 39;
BA_ "GenSigTimeout_OCM" SG_ 996 NetCfg_ORC 21000;
BA_ "GenSigTimeout_IC" SG_ 996 NetCfg_ORC 21000;
BA_ "FlexKomSigStartValue" SG_ 996 NetCfg_ORC "0300000000000000h";
BA_ "GenSigCycleTime" SG_ 996 NetCfg_ORC 2000;
BA_ "GenSigSendType" SG_ 996 NetCfg_ORC 5;
BA_ "GenSigSNA" SG_ 996 NetCfg_OCM "0h";
BA_ "FlexKomIsMotorola" SG_ 996 NetCfg_OCM 1;
BA_ "FlexKomComment" SG_ 996 NetCfg_OCM "Network ECU config data for Powertrain";
BA_ "FlexKomSigName" SG_ 996 NetCfg_OCM "NET_CFG_DATA_PT";
BA_ "FlexKomSigLaenge" SG_ 996 NetCfg_OCM 64;
BA_ "FlexKomSigStartPos" SG_ 996 NetCfg_OCM 7;
BA_ "FlexKomSID" SG_ 996 NetCfg_OCM 39;
BA_ "GenSigTimeout_ORC" SG_ 996 NetCfg_OCM 7000;
BA_ "FlexKomSigStartValue" SG_ 996 NetCfg_OCM "0300000000000000h";
BA_ "GenSigCycleTime" SG_ 996 NetCfg_OCM 2000;
BA_ "GenSigSendType" SG_ 996 NetCfg_OCM 5;
BA_ "GenSigSNA" SG_ 996 NetCfg_ITBM "0h";
BA_ "FlexKomIsMotorola" SG_ 996 NetCfg_ITBM 1;
BA_ "FlexKomComment" SG_ 996 NetCfg_ITBM "Network ECU config data for Powertrain";
BA_ "FlexKomSigName" SG_ 996 NetCfg_ITBM "NET_CFG_DATA_PT";
BA_ "FlexKomSigLaenge" SG_ 996 NetCfg_ITBM 64;
BA_ "FlexKomSigStartPos" SG_ 996 NetCfg_ITBM 7;
BA_ "FlexKomSID" SG_ 996 NetCfg_ITBM 39;
BA_ "GenSigTimeout_IC" SG_ 996 NetCfg_ITBM 21000;
BA_ "FlexKomSigStartValue" SG_ 996 NetCfg_ITBM "0300000000000000h";
BA_ "GenSigCycleTime" SG_ 996 NetCfg_ITBM 2000;
BA_ "GenSigSendType" SG_ 996 NetCfg_ITBM 5;
BA_ "GenSigSNA" SG_ 996 NetCfg_IC "0h";
BA_ "FlexKomIsMotorola" SG_ 996 NetCfg_IC 1;
BA_ "FlexKomComment" SG_ 996 NetCfg_IC "Network ECU config data for Powertrain";
BA_ "FlexKomSigName" SG_ 996 NetCfg_IC "NET_CFG_DATA_PT";
BA_ "FlexKomSigLaenge" SG_ 996 NetCfg_IC 64;
BA_ "FlexKomSigStartPos" SG_ 996 NetCfg_IC 7;
BA_ "FlexKomSID" SG_ 996 NetCfg_IC 39;
BA_ "GenSigTimeout_EPS" SG_ 996 NetCfg_IC 21000;
BA_ "GenSigTimeout_IC" SG_ 996 NetCfg_IC 21000;
BA_ "FlexKomSigStartValue" SG_ 996 NetCfg_IC "0300000000000000h";
BA_ "GenSigCycleTime" SG_ 996 NetCfg_IC 2000;
BA_ "GenSigSendType" SG_ 996 NetCfg_IC 5;
BA_ "GenSigSNA" SG_ 996 NetCfg_HCP "0h";
BA_ "FlexKomIsMotorola" SG_ 996 NetCfg_HCP 1;
BA_ "FlexKomComment" SG_ 996 NetCfg_HCP "Network ECU config data for Powertrain";
BA_ "FlexKomSigName" SG_ 996 NetCfg_HCP "NET_CFG_DATA_PT";
BA_ "FlexKomSigLaenge" SG_ 996 NetCfg_HCP 64;
BA_ "FlexKomSigStartPos" SG_ 996 NetCfg_HCP 7;
BA_ "FlexKomSID" SG_ 996 NetCfg_HCP 39;
BA_ "GenSigTimeout_ORC" SG_ 996 NetCfg_HCP 7000;
BA_ "FlexKomSigStartValue" SG_ 996 NetCfg_HCP "0300000000000000h";
BA_ "GenSigCycleTime" SG_ 996 NetCfg_HCP 2000;
BA_ "GenSigSendType" SG_ 996 NetCfg_HCP 5;
BA_ "GenSigSNA" SG_ 996 NetCfg_HaLF "0h";
BA_ "FlexKomIsMotorola" SG_ 996 NetCfg_HaLF 1;
BA_ "FlexKomComment" SG_ 996 NetCfg_HaLF "Network ECU config data for Powertrain";
BA_ "FlexKomSigName" SG_ 996 NetCfg_HaLF "NET_CFG_DATA_PT";
BA_ "FlexKomSigLaenge" SG_ 996 NetCfg_HaLF 64;
BA_ "FlexKomSigStartPos" SG_ 996 NetCfg_HaLF 7;
BA_ "FlexKomSID" SG_ 996 NetCfg_HaLF 39;
BA_ "GenSigTimeout_EPS" SG_ 996 NetCfg_HaLF 21000;
BA_ "FlexKomSigStartValue" SG_ 996 NetCfg_HaLF "0300000000000000h";
BA_ "GenSigCycleTime" SG_ 996 NetCfg_HaLF 2000;
BA_ "GenSigSendType" SG_ 996 NetCfg_HaLF 5;
BA_ "GenSigSNA" SG_ 996 NetCfg_FDCM "0h";
BA_ "FlexKomIsMotorola" SG_ 996 NetCfg_FDCM 1;
BA_ "FlexKomComment" SG_ 996 NetCfg_FDCM "Network ECU config data for Powertrain";
BA_ "FlexKomSigName" SG_ 996 NetCfg_FDCM "NET_CFG_DATA_PT";
BA_ "FlexKomSigLaenge" SG_ 996 NetCfg_FDCM 64;
BA_ "FlexKomSigStartPos" SG_ 996 NetCfg_FDCM 7;
BA_ "FlexKomSID" SG_ 996 NetCfg_FDCM 39;
BA_ "FlexKomSigStartValue" SG_ 996 NetCfg_FDCM "0300000000000000h";
BA_ "GenSigCycleTime" SG_ 996 NetCfg_FDCM 2000;
BA_ "GenSigSendType" SG_ 996 NetCfg_FDCM 5;
BA_ "GenSigSNA" SG_ 996 NetCfg_ESM "0h";
BA_ "FlexKomIsMotorola" SG_ 996 NetCfg_ESM 1;
BA_ "FlexKomComment" SG_ 996 NetCfg_ESM "Network ECU config data for Powertrain";
BA_ "FlexKomSigName" SG_ 996 NetCfg_ESM "NET_CFG_DATA_PT";
BA_ "FlexKomSigLaenge" SG_ 996 NetCfg_ESM 64;
BA_ "FlexKomSigStartPos" SG_ 996 NetCfg_ESM 7;
BA_ "FlexKomSID" SG_ 996 NetCfg_ESM 39;
BA_ "GenSigTimeout_IC" SG_ 996 NetCfg_ESM 21000;
BA_ "FlexKomSigStartValue" SG_ 996 NetCfg_ESM "0300000000000000h";
BA_ "GenSigCycleTime" SG_ 996 NetCfg_ESM 2000;
BA_ "GenSigSendType" SG_ 996 NetCfg_ESM 5;
BA_ "GenSigSNA" SG_ 996 NetCfg_ESL "0h";
BA_ "FlexKomIsMotorola" SG_ 996 NetCfg_ESL 1;
BA_ "FlexKomComment" SG_ 996 NetCfg_ESL "Network ECU config data for Powertrain";
BA_ "FlexKomSigName" SG_ 996 NetCfg_ESL "NET_CFG_DATA_PT";
BA_ "FlexKomSigLaenge" SG_ 996 NetCfg_ESL 64;
BA_ "FlexKomSigStartPos" SG_ 996 NetCfg_ESL 7;
BA_ "FlexKomSID" SG_ 996 NetCfg_ESL 39;
BA_ "FlexKomSigStartValue" SG_ 996 NetCfg_ESL "0300000000000000h";
BA_ "GenSigCycleTime" SG_ 996 NetCfg_ESL 2000;
BA_ "GenSigSendType" SG_ 996 NetCfg_ESL 5;
BA_ "GenSigSNA" SG_ 996 NetCfg_ESC "0h";
BA_ "FlexKomIsMotorola" SG_ 996 NetCfg_ESC 1;
BA_ "FlexKomComment" SG_ 996 NetCfg_ESC "Network ECU config data for Powertrain";
BA_ "FlexKomSigName" SG_ 996 NetCfg_ESC "NET_CFG_DATA_PT";
BA_ "FlexKomSigLaenge" SG_ 996 NetCfg_ESC 64;
BA_ "FlexKomSigStartPos" SG_ 996 NetCfg_ESC 7;
BA_ "FlexKomSID" SG_ 996 NetCfg_ESC 39;
BA_ "GenSigTimeout_ORC" SG_ 996 NetCfg_ESC 7000;
BA_ "GenSigTimeout_EPS" SG_ 996 NetCfg_ESC 21000;
BA_ "GenSigTimeout_IC" SG_ 996 NetCfg_ESC 21000;
BA_ "FlexKomSigStartValue" SG_ 996 NetCfg_ESC "0300000000000000h";
BA_ "GenSigCycleTime" SG_ 996 NetCfg_ESC 2000;
BA_ "GenSigSendType" SG_ 996 NetCfg_ESC 5;
BA_ "GenSigSNA" SG_ 996 NetCfg_EPS "0h";
BA_ "FlexKomIsMotorola" SG_ 996 NetCfg_EPS 1;
BA_ "FlexKomComment" SG_ 996 NetCfg_EPS "Network ECU config data for Powertrain";
BA_ "FlexKomSigName" SG_ 996 NetCfg_EPS "NET_CFG_DATA_PT";
BA_ "FlexKomSigLaenge" SG_ 996 NetCfg_EPS 64;
BA_ "FlexKomSigStartPos" SG_ 996 NetCfg_EPS 7;
BA_ "FlexKomSID" SG_ 996 NetCfg_EPS 39;
BA_ "GenSigTimeout_ORC" SG_ 996 NetCfg_EPS 7000;
BA_ "GenSigTimeout_IC" SG_ 996 NetCfg_EPS 21000;
BA_ "FlexKomSigStartValue" SG_ 996 NetCfg_EPS "0300000000000000h";
BA_ "GenSigCycleTime" SG_ 996 NetCfg_EPS 2000;
BA_ "GenSigSendType" SG_ 996 NetCfg_EPS 5;
BA_ "GenSigSNA" SG_ 996 NetCfg_EPPM "0h";
BA_ "FlexKomIsMotorola" SG_ 996 NetCfg_EPPM 1;
BA_ "FlexKomComment" SG_ 996 NetCfg_EPPM "Network ECU config data for Powertrain";
BA_ "FlexKomSigName" SG_ 996 NetCfg_EPPM "NET_CFG_DATA_PT";
BA_ "FlexKomSigLaenge" SG_ 996 NetCfg_EPPM 64;
BA_ "FlexKomSigStartPos" SG_ 996 NetCfg_EPPM 7;
BA_ "FlexKomSID" SG_ 996 NetCfg_EPPM 39;
BA_ "GenSigTimeout_ORC" SG_ 996 NetCfg_EPPM 7000;
BA_ "FlexKomSigStartValue" SG_ 996 NetCfg_EPPM "0300000000000000h";
BA_ "GenSigCycleTime" SG_ 996 NetCfg_EPPM 2000;
BA_ "GenSigSendType" SG_ 996 NetCfg_EPPM 5;
BA_ "GenSigSNA" SG_ 996 NetCfg_EPB "0h";
BA_ "FlexKomIsMotorola" SG_ 996 NetCfg_EPB 1;
BA_ "FlexKomComment" SG_ 996 NetCfg_EPB "Network ECU config data for Powertrain";
BA_ "FlexKomSigName" SG_ 996 NetCfg_EPB "NET_CFG_DATA_PT";
BA_ "FlexKomSigLaenge" SG_ 996 NetCfg_EPB 64;
BA_ "FlexKomSigStartPos" SG_ 996 NetCfg_EPB 7;
BA_ "FlexKomSID" SG_ 996 NetCfg_EPB 39;
BA_ "GenSigTimeout_ORC" SG_ 996 NetCfg_EPB 7000;
BA_ "FlexKomSigStartValue" SG_ 996 NetCfg_EPB "0300000000000000h";
BA_ "GenSigCycleTime" SG_ 996 NetCfg_EPB 2000;
BA_ "GenSigSendType" SG_ 996 NetCfg_EPB 5;
BA_ "GenSigSNA" SG_ 996 NetCfg_ELSD "0h";
BA_ "FlexKomIsMotorola" SG_ 996 NetCfg_ELSD 1;
BA_ "FlexKomComment" SG_ 996 NetCfg_ELSD "Network ECU config data for Powertrain";
BA_ "FlexKomSigName" SG_ 996 NetCfg_ELSD "NET_CFG_DATA_PT";
BA_ "FlexKomSigLaenge" SG_ 996 NetCfg_ELSD 64;
BA_ "FlexKomSigStartPos" SG_ 996 NetCfg_ELSD 7;
BA_ "FlexKomSID" SG_ 996 NetCfg_ELSD 39;
BA_ "GenSigTimeout_IC" SG_ 996 NetCfg_ELSD 21000;
BA_ "FlexKomSigStartValue" SG_ 996 NetCfg_ELSD "0300000000000000h";
BA_ "GenSigCycleTime" SG_ 996 NetCfg_ELSD 2000;
BA_ "GenSigSendType" SG_ 996 NetCfg_ELSD 5;
BA_ "GenSigSNA" SG_ 996 NetCfg_ECM "0h";
BA_ "FlexKomIsMotorola" SG_ 996 NetCfg_ECM 1;
BA_ "FlexKomComment" SG_ 996 NetCfg_ECM "Network ECU config data for Powertrain";
BA_ "FlexKomSigName" SG_ 996 NetCfg_ECM "NET_CFG_DATA_PT";
BA_ "FlexKomSigLaenge" SG_ 996 NetCfg_ECM 64;
BA_ "FlexKomSigStartPos" SG_ 996 NetCfg_ECM 7;
BA_ "FlexKomSID" SG_ 996 NetCfg_ECM 39;
BA_ "GenSigTimeout_OCM" SG_ 996 NetCfg_ECM 21000;
BA_ "GenSigTimeout_ORC" SG_ 996 NetCfg_ECM 7000;
BA_ "GenSigTimeout_EPS" SG_ 996 NetCfg_ECM 21000;
BA_ "GenSigTimeout_IC" SG_ 996 NetCfg_ECM 21000;
BA_ "FlexKomSigStartValue" SG_ 996 NetCfg_ECM "0300000000000000h";
BA_ "GenSigCycleTime" SG_ 996 NetCfg_ECM 2000;
BA_ "GenSigSendType" SG_ 996 NetCfg_ECM 5;
BA_ "GenSigSNA" SG_ 996 NetCfg_DTCM "0h";
BA_ "FlexKomIsMotorola" SG_ 996 NetCfg_DTCM 1;
BA_ "FlexKomComment" SG_ 996 NetCfg_DTCM "Network ECU config data for Powertrain";
BA_ "FlexKomSigName" SG_ 996 NetCfg_DTCM "NET_CFG_DATA_PT";
BA_ "FlexKomSigLaenge" SG_ 996 NetCfg_DTCM 64;
BA_ "FlexKomSigStartPos" SG_ 996 NetCfg_DTCM 7;
BA_ "FlexKomSID" SG_ 996 NetCfg_DTCM 39;
BA_ "GenSigTimeout_ORC" SG_ 996 NetCfg_DTCM 7000;
BA_ "GenSigTimeout_IC" SG_ 996 NetCfg_DTCM 21000;
BA_ "FlexKomSigStartValue" SG_ 996 NetCfg_DTCM "0300000000000000h";
BA_ "GenSigCycleTime" SG_ 996 NetCfg_DTCM 2000;
BA_ "GenSigSendType" SG_ 996 NetCfg_DTCM 5;
BA_ "GenSigSNA" SG_ 996 NetCfg_DASM "0h";
BA_ "FlexKomIsMotorola" SG_ 996 NetCfg_DASM 1;
BA_ "FlexKomComment" SG_ 996 NetCfg_DASM "Network ECU config data for Powertrain";
BA_ "FlexKomSigName" SG_ 996 NetCfg_DASM "NET_CFG_DATA_PT";
BA_ "FlexKomSigLaenge" SG_ 996 NetCfg_DASM 64;
BA_ "FlexKomSigStartPos" SG_ 996 NetCfg_DASM 7;
BA_ "FlexKomSID" SG_ 996 NetCfg_DASM 39;
BA_ "GenSigTimeout_ORC" SG_ 996 NetCfg_DASM 7000;
BA_ "GenSigTimeout_IC" SG_ 996 NetCfg_DASM 21000;
BA_ "FlexKomSigStartValue" SG_ 996 NetCfg_DASM "0300000000000000h";
BA_ "GenSigCycleTime" SG_ 996 NetCfg_DASM 2000;
BA_ "GenSigSendType" SG_ 996 NetCfg_DASM 5;
BA_ "GenSigSNA" SG_ 996 NetCfg_CBC_PT "0h";
BA_ "FlexKomIsMotorola" SG_ 996 NetCfg_CBC_PT 1;
BA_ "FlexKomComment" SG_ 996 NetCfg_CBC_PT "Network ECU config data for Powertrain";
BA_ "FlexKomSigName" SG_ 996 NetCfg_CBC_PT "NET_CFG_DATA_PT";
BA_ "FlexKomSigLaenge" SG_ 996 NetCfg_CBC_PT 64;
BA_ "FlexKomSigStartPos" SG_ 996 NetCfg_CBC_PT 7;
BA_ "FlexKomSID" SG_ 996 NetCfg_CBC_PT 39;
BA_ "GenSigTimeout_OCM" SG_ 996 NetCfg_CBC_PT 21000;
BA_ "GenSigTimeout_ORC" SG_ 996 NetCfg_CBC_PT 7000;
BA_ "GenSigTimeout_EPS" SG_ 996 NetCfg_CBC_PT 21000;
BA_ "GenSigTimeout_IC" SG_ 996 NetCfg_CBC_PT 21000;
BA_ "FlexKomSigStartValue" SG_ 996 NetCfg_CBC_PT "0300000000000000h";
BA_ "GenSigCycleTime" SG_ 996 NetCfg_CBC_PT 2000;
BA_ "GenSigSendType" SG_ 996 NetCfg_CBC_PT 5;
BA_ "FlexKomComment" SG_ 996 NetCfg_BSMO "Network ECU config data for Powertrain";
BA_ "GenSigSendType" SG_ 996 NetCfg_BSMO 5;
BA_ "GenSigCycleTime" SG_ 996 NetCfg_BSMO 2000;
BA_ "FlexKomSigStartValue" SG_ 996 NetCfg_BSMO "0300000000000000h";
BA_ "FlexKomSID" SG_ 996 NetCfg_BSMO 39;
BA_ "FlexKomSigStartPos" SG_ 996 NetCfg_BSMO 7;
BA_ "FlexKomSigLaenge" SG_ 996 NetCfg_BSMO 64;
BA_ "FlexKomSigName" SG_ 996 NetCfg_BSMO "NET_CFG_DATA_PT";
BA_ "FlexKomIsMotorola" SG_ 996 NetCfg_BSMO 1;
BA_ "GenSigSNA" SG_ 996 NetCfg_BSMO "0h";
BA_ "GenSigSNA" SG_ 996 NetCfg_ASCM "0h";
BA_ "FlexKomIsMotorola" SG_ 996 NetCfg_ASCM 1;
BA_ "FlexKomComment" SG_ 996 NetCfg_ASCM "Network ECU config data for Powertrain";
BA_ "FlexKomSigName" SG_ 996 NetCfg_ASCM "NET_CFG_DATA_PT";
BA_ "FlexKomSigLaenge" SG_ 996 NetCfg_ASCM 64;
BA_ "FlexKomSigStartPos" SG_ 996 NetCfg_ASCM 7;
BA_ "FlexKomSID" SG_ 996 NetCfg_ASCM 39;
BA_ "GenSigTimeout_IC" SG_ 996 NetCfg_ASCM 21000;
BA_ "FlexKomSigStartValue" SG_ 996 NetCfg_ASCM "0300000000000000h";
BA_ "GenSigCycleTime" SG_ 996 NetCfg_ASCM 2000;
BA_ "GenSigSendType" SG_ 996 NetCfg_ASCM 5;
BA_ "GenSigSNA" SG_ 996 NetCfg_ANC "0h";
BA_ "FlexKomIsMotorola" SG_ 996 NetCfg_ANC 1;
BA_ "FlexKomComment" SG_ 996 NetCfg_ANC "Network ECU config data for Powertrain";
BA_ "FlexKomSigName" SG_ 996 NetCfg_ANC "NET_CFG_DATA_PT";
BA_ "FlexKomSigLaenge" SG_ 996 NetCfg_ANC 64;
BA_ "FlexKomSigStartPos" SG_ 996 NetCfg_ANC 7;
BA_ "FlexKomSID" SG_ 996 NetCfg_ANC 39;
BA_ "FlexKomSigStartValue" SG_ 996 NetCfg_ANC "0300000000000000h";
BA_ "GenSigCycleTime" SG_ 996 NetCfg_ANC 2000;
BA_ "GenSigSendType" SG_ 996 NetCfg_ANC 5;
BA_ "GenSigSNA" SG_ 996 NetCfg_AHLM "0h";
BA_ "FlexKomIsMotorola" SG_ 996 NetCfg_AHLM 1;
BA_ "FlexKomComment" SG_ 996 NetCfg_AHLM "Network ECU config data for Powertrain";
BA_ "FlexKomSigName" SG_ 996 NetCfg_AHLM "NET_CFG_DATA_PT";
BA_ "FlexKomSigLaenge" SG_ 996 NetCfg_AHLM 64;
BA_ "FlexKomSigStartPos" SG_ 996 NetCfg_AHLM 7;
BA_ "FlexKomSID" SG_ 996 NetCfg_AHLM 39;
BA_ "GenSigTimeout_IC" SG_ 996 NetCfg_AHLM 21000;
BA_ "FlexKomSigStartValue" SG_ 996 NetCfg_AHLM "0300000000000000h";
BA_ "GenSigCycleTime" SG_ 996 NetCfg_AHLM 2000;
BA_ "GenSigSendType" SG_ 996 NetCfg_AHLM 5;
BA_ "GenSigSNA" SG_ 996 NetCfg_AFLS "0h";
BA_ "FlexKomIsMotorola" SG_ 996 NetCfg_AFLS 1;
BA_ "FlexKomComment" SG_ 996 NetCfg_AFLS "Network ECU config data for Powertrain";
BA_ "FlexKomSigName" SG_ 996 NetCfg_AFLS "NET_CFG_DATA_PT";
BA_ "FlexKomSigLaenge" SG_ 996 NetCfg_AFLS 64;
BA_ "FlexKomSigStartPos" SG_ 996 NetCfg_AFLS 7;
BA_ "FlexKomSID" SG_ 996 NetCfg_AFLS 39;
BA_ "GenSigTimeout_IC" SG_ 996 NetCfg_AFLS 21000;
BA_ "FlexKomSigStartValue" SG_ 996 NetCfg_AFLS "0300000000000000h";
BA_ "GenSigCycleTime" SG_ 996 NetCfg_AFLS 2000;
BA_ "GenSigSendType" SG_ 996 NetCfg_AFLS 5;
BA_ "GenSigSNA" SG_ 996 NetCfg_ADCM "0h";
BA_ "FlexKomIsMotorola" SG_ 996 NetCfg_ADCM 1;
BA_ "FlexKomComment" SG_ 996 NetCfg_ADCM "Network ECU config data for Powertrain";
BA_ "FlexKomSigName" SG_ 996 NetCfg_ADCM "NET_CFG_DATA_PT";
BA_ "FlexKomSigLaenge" SG_ 996 NetCfg_ADCM 64;
BA_ "FlexKomSigStartPos" SG_ 996 NetCfg_ADCM 7;
BA_ "FlexKomSID" SG_ 996 NetCfg_ADCM 39;
BA_ "GenSigTimeout_ORC" SG_ 996 NetCfg_ADCM 7000;
BA_ "GenSigTimeout_IC" SG_ 996 NetCfg_ADCM 21000;
BA_ "FlexKomSigStartValue" SG_ 996 NetCfg_ADCM "0300000000000000h";
BA_ "GenSigCycleTime" SG_ 996 NetCfg_ADCM 2000;
BA_ "GenSigSendType" SG_ 996 NetCfg_ADCM 5;
BA_ "GenSigSNA" SG_ 996 NetCfg_ACC "0h";
BA_ "FlexKomIsMotorola" SG_ 996 NetCfg_ACC 1;
BA_ "FlexKomComment" SG_ 996 NetCfg_ACC "Network ECU config data for Powertrain";
BA_ "FlexKomSigName" SG_ 996 NetCfg_ACC "NET_CFG_DATA_PT";
BA_ "FlexKomSigLaenge" SG_ 996 NetCfg_ACC 64;
BA_ "FlexKomSigStartPos" SG_ 996 NetCfg_ACC 7;
BA_ "FlexKomSID" SG_ 996 NetCfg_ACC 39;
BA_ "GenSigTimeout_IC" SG_ 996 NetCfg_ACC 21000;
BA_ "FlexKomSigStartValue" SG_ 996 NetCfg_ACC "0300000000000000h";
BA_ "GenSigCycleTime" SG_ 996 NetCfg_ACC 2000;
BA_ "GenSigSendType" SG_ 996 NetCfg_ACC 5;
BA_ "GenSigSNA" SG_ 996 NET_CFG_STAT_PT "3h";
BA_ "FlexKomIsMotorola" SG_ 996 NET_CFG_STAT_PT 1;
BA_ "FlexKomComment" SG_ 996 NET_CFG_STAT_PT "Network ECU config data for Powertrain";
BA_ "FlexKomSigName" SG_ 996 NET_CFG_STAT_PT "NET_CFG_DATA_PT";
BA_ "FlexKomSigLaenge" SG_ 996 NET_CFG_STAT_PT 64;
BA_ "FlexKomSigStartPos" SG_ 996 NET_CFG_STAT_PT 7;
BA_ "FlexKomSID" SG_ 996 NET_CFG_STAT_PT 39;
BA_ "GenSigTimeout_OCM" SG_ 996 NET_CFG_STAT_PT 21000;
BA_ "GenSigTimeout_ORC" SG_ 996 NET_CFG_STAT_PT 7000;
BA_ "GenSigTimeout_ESM" SG_ 996 NET_CFG_STAT_PT 21000;
BA_ "GenSigTimeout_EPS" SG_ 996 NET_CFG_STAT_PT 21000;
BA_ "GenSigTimeout_IC" SG_ 996 NET_CFG_STAT_PT 21000;
BA_ "GenSigStartValue" SG_ 996 NET_CFG_STAT_PT 3;
BA_ "FlexKomSigStartValue" SG_ 996 NET_CFG_STAT_PT "0300000000000000h";
BA_ "GenSigCycleTime" SG_ 996 NET_CFG_STAT_PT 2000;
BA_ "GenSigSendType" SG_ 996 NET_CFG_STAT_PT 5;
BA_ "GenMsgStartDelayTime" BO_ 995 20;
BA_ "GenMsgStartValue" BO_ 995 "0300000000000000h";
BA_ "GenMsgNrOfRepetitions" BO_ 995 2;
BA_ "GenMsgDelayTime" BO_ 995 20;
BA_ "GenMsgCycleTime" BO_ 995 2000;
BA_ "GenMsgSendType" BO_ 995 5;
BA_ "GenSigSNA" SG_ 995 NetCfg_VTM "0h";
BA_ "FlexKomIsMotorola" SG_ 995 NetCfg_VTM 1;
BA_ "FlexKomComment" SG_ 995 NetCfg_VTM "Network ECU config data for interior";
BA_ "FlexKomSigName" SG_ 995 NetCfg_VTM "NET_CFG_DATA_INT";
BA_ "FlexKomSigLaenge" SG_ 995 NetCfg_VTM 64;
BA_ "FlexKomSigStartPos" SG_ 995 NetCfg_VTM 7;
BA_ "FlexKomSID" SG_ 995 NetCfg_VTM 38;
BA_ "GenSigTimeout_RF_HUB" SG_ 995 NetCfg_VTM 21000;
BA_ "FlexKomSigStartValue" SG_ 995 NetCfg_VTM "0300000000000000h";
BA_ "GenSigCycleTime" SG_ 995 NetCfg_VTM 2000;
BA_ "GenSigSendType" SG_ 995 NetCfg_VTM 5;
BA_ "GenSigSNA" SG_ 995 NetCfg_VSIM "0h";
BA_ "FlexKomIsMotorola" SG_ 995 NetCfg_VSIM 1;
BA_ "FlexKomComment" SG_ 995 NetCfg_VSIM "Network ECU config data for interior";
BA_ "FlexKomSigName" SG_ 995 NetCfg_VSIM "NET_CFG_DATA_INT";
BA_ "FlexKomSigLaenge" SG_ 995 NetCfg_VSIM 64;
BA_ "FlexKomSigStartPos" SG_ 995 NetCfg_VSIM 7;
BA_ "FlexKomSID" SG_ 995 NetCfg_VSIM 38;
BA_ "GenSigTimeout_IC" SG_ 995 NetCfg_VSIM 21000;
BA_ "GenSigTimeout_RF_HUB" SG_ 995 NetCfg_VSIM 21000;
BA_ "FlexKomSigStartValue" SG_ 995 NetCfg_VSIM "0300000000000000h";
BA_ "GenSigCycleTime" SG_ 995 NetCfg_VSIM 2000;
BA_ "GenSigSendType" SG_ 995 NetCfg_VSIM 5;
BA_ "GenSigSNA" SG_ 995 NetCfg_VRM "0h";
BA_ "FlexKomIsMotorola" SG_ 995 NetCfg_VRM 1;
BA_ "FlexKomComment" SG_ 995 NetCfg_VRM "Network ECU config data for interior";
BA_ "FlexKomSigName" SG_ 995 NetCfg_VRM "NET_CFG_DATA_INT";
BA_ "FlexKomSigLaenge" SG_ 995 NetCfg_VRM 64;
BA_ "FlexKomSigStartPos" SG_ 995 NetCfg_VRM 7;
BA_ "FlexKomSID" SG_ 995 NetCfg_VRM 38;
BA_ "GenSigTimeout_RF_HUB" SG_ 995 NetCfg_VRM 21000;
BA_ "FlexKomSigStartValue" SG_ 995 NetCfg_VRM "0300000000000000h";
BA_ "GenSigCycleTime" SG_ 995 NetCfg_VRM 2000;
BA_ "GenSigSendType" SG_ 995 NetCfg_VRM 5;
BA_ "GenSigSNA" SG_ 995 NetCfg_VES3_I "0h";
BA_ "FlexKomIsMotorola" SG_ 995 NetCfg_VES3_I 1;
BA_ "FlexKomComment" SG_ 995 NetCfg_VES3_I "Network ECU config data for interior";
BA_ "FlexKomSigName" SG_ 995 NetCfg_VES3_I "NET_CFG_DATA_INT";
BA_ "FlexKomSigLaenge" SG_ 995 NetCfg_VES3_I 64;
BA_ "FlexKomSigStartPos" SG_ 995 NetCfg_VES3_I 7;
BA_ "FlexKomSID" SG_ 995 NetCfg_VES3_I 38;
BA_ "GenSigTimeout_RF_HUB" SG_ 995 NetCfg_VES3_I 21000;
BA_ "FlexKomSigStartValue" SG_ 995 NetCfg_VES3_I "0300000000000000h";
BA_ "GenSigCycleTime" SG_ 995 NetCfg_VES3_I 2000;
BA_ "GenSigSendType" SG_ 995 NetCfg_VES3_I 5;
BA_ "GenSigSNA" SG_ 995 NetCfg_VES2_I "0h";
BA_ "FlexKomIsMotorola" SG_ 995 NetCfg_VES2_I 1;
BA_ "FlexKomComment" SG_ 995 NetCfg_VES2_I "Network ECU config data for interior";
BA_ "FlexKomSigName" SG_ 995 NetCfg_VES2_I "NET_CFG_DATA_INT";
BA_ "FlexKomSigLaenge" SG_ 995 NetCfg_VES2_I 64;
BA_ "FlexKomSigStartPos" SG_ 995 NetCfg_VES2_I 7;
BA_ "FlexKomSID" SG_ 995 NetCfg_VES2_I 38;
BA_ "GenSigTimeout_RF_HUB" SG_ 995 NetCfg_VES2_I 21000;
BA_ "FlexKomSigStartValue" SG_ 995 NetCfg_VES2_I "0300000000000000h";
BA_ "GenSigCycleTime" SG_ 995 NetCfg_VES2_I 2000;
BA_ "GenSigSendType" SG_ 995 NetCfg_VES2_I 5;
BA_ "GenSigSendType" SG_ 995 NetCfg_TTM 5;
BA_ "GenSigCycleTime" SG_ 995 NetCfg_TTM 2000;
BA_ "FlexKomSigStartValue" SG_ 995 NetCfg_TTM "0300000000000000h";
BA_ "GenSigTimeout_RF_HUB" SG_ 995 NetCfg_TTM 21000;
BA_ "FlexKomSID" SG_ 995 NetCfg_TTM 38;
BA_ "FlexKomSigStartPos" SG_ 995 NetCfg_TTM 7;
BA_ "FlexKomSigLaenge" SG_ 995 NetCfg_TTM 64;
BA_ "FlexKomSigName" SG_ 995 NetCfg_TTM "NET_CFG_DATA_INT";
BA_ "FlexKomIsMotorola" SG_ 995 NetCfg_TTM 1;
BA_ "GenSigSNA" SG_ 995 NetCfg_TTM "0h";
BA_ "FlexKomComment" SG_ 995 NetCfg_TTM "Network ECU config data for interior";
BA_ "GenSigSNA" SG_ 995 NetCfg_TMM "0h";
BA_ "FlexKomIsMotorola" SG_ 995 NetCfg_TMM 1;
BA_ "FlexKomComment" SG_ 995 NetCfg_TMM "Network ECU config data for interior";
BA_ "FlexKomSigName" SG_ 995 NetCfg_TMM "NET_CFG_DATA_INT";
BA_ "FlexKomSigLaenge" SG_ 995 NetCfg_TMM 64;
BA_ "FlexKomSigStartPos" SG_ 995 NetCfg_TMM 7;
BA_ "FlexKomSID" SG_ 995 NetCfg_TMM 38;
BA_ "GenSigTimeout_RF_HUB" SG_ 995 NetCfg_TMM 21000;
BA_ "FlexKomSigStartValue" SG_ 995 NetCfg_TMM "0300000000000000h";
BA_ "GenSigCycleTime" SG_ 995 NetCfg_TMM 2000;
BA_ "GenSigSendType" SG_ 995 NetCfg_TMM 5;
BA_ "GenSigSNA" SG_ 995 NetCfg_TGW "0h";
BA_ "FlexKomIsMotorola" SG_ 995 NetCfg_TGW 1;
BA_ "FlexKomComment" SG_ 995 NetCfg_TGW "Network ECU config data for interior";
BA_ "FlexKomSigName" SG_ 995 NetCfg_TGW "NET_CFG_DATA_INT";
BA_ "FlexKomSigLaenge" SG_ 995 NetCfg_TGW 64;
BA_ "FlexKomSigStartPos" SG_ 995 NetCfg_TGW 7;
BA_ "FlexKomSID" SG_ 995 NetCfg_TGW 38;
BA_ "GenSigTimeout_IC" SG_ 995 NetCfg_TGW 21000;
BA_ "GenSigTimeout_RF_HUB" SG_ 995 NetCfg_TGW 21000;
BA_ "FlexKomSigStartValue" SG_ 995 NetCfg_TGW "0300000000000000h";
BA_ "GenSigCycleTime" SG_ 995 NetCfg_TGW 2000;
BA_ "GenSigSendType" SG_ 995 NetCfg_TGW 5;
BA_ "GenSigSNA" SG_ 995 NetCfg_TBM "0h";
BA_ "FlexKomIsMotorola" SG_ 995 NetCfg_TBM 1;
BA_ "FlexKomComment" SG_ 995 NetCfg_TBM "Network ECU config data for interior";
BA_ "FlexKomSigName" SG_ 995 NetCfg_TBM "NET_CFG_DATA_INT";
BA_ "FlexKomSigLaenge" SG_ 995 NetCfg_TBM 64;
BA_ "FlexKomSigStartPos" SG_ 995 NetCfg_TBM 7;
BA_ "FlexKomSID" SG_ 995 NetCfg_TBM 38;
BA_ "GenSigTimeout_RF_HUB" SG_ 995 NetCfg_TBM 21000;
BA_ "FlexKomSigStartValue" SG_ 995 NetCfg_TBM "0300000000000000h";
BA_ "GenSigCycleTime" SG_ 995 NetCfg_TBM 2000;
BA_ "GenSigSendType" SG_ 995 NetCfg_TBM 5;
BA_ "GenSigSNA" SG_ 995 NetCfg_RBSS "0h";
BA_ "FlexKomIsMotorola" SG_ 995 NetCfg_RBSS 1;
BA_ "FlexKomComment" SG_ 995 NetCfg_RBSS "Network ECU config data for interior";
BA_ "FlexKomSigName" SG_ 995 NetCfg_RBSS "NET_CFG_DATA_INT";
BA_ "FlexKomSigLaenge" SG_ 995 NetCfg_RBSS 64;
BA_ "FlexKomSigStartPos" SG_ 995 NetCfg_RBSS 7;
BA_ "FlexKomSID" SG_ 995 NetCfg_RBSS 38;
BA_ "GenSigTimeout_RF_HUB" SG_ 995 NetCfg_RBSS 21000;
BA_ "FlexKomSigStartValue" SG_ 995 NetCfg_RBSS "0300000000000000h";
BA_ "GenSigCycleTime" SG_ 995 NetCfg_RBSS 2000;
BA_ "GenSigSendType" SG_ 995 NetCfg_RBSS 5;
BA_ "GenSigSNA" SG_ 995 NetCfg_RBC "0h";
BA_ "FlexKomIsMotorola" SG_ 995 NetCfg_RBC 1;
BA_ "FlexKomComment" SG_ 995 NetCfg_RBC "Network ECU config data for interior";
BA_ "FlexKomSigName" SG_ 995 NetCfg_RBC "NET_CFG_DATA_INT";
BA_ "FlexKomSigLaenge" SG_ 995 NetCfg_RBC 64;
BA_ "FlexKomSigStartPos" SG_ 995 NetCfg_RBC 7;
BA_ "FlexKomSID" SG_ 995 NetCfg_RBC 38;
BA_ "GenSigTimeout_IC" SG_ 995 NetCfg_RBC 21000;
BA_ "GenSigTimeout_RF_HUB" SG_ 995 NetCfg_RBC 21000;
BA_ "FlexKomSigStartValue" SG_ 995 NetCfg_RBC "0300000000000000h";
BA_ "GenSigCycleTime" SG_ 995 NetCfg_RBC 2000;
BA_ "GenSigSendType" SG_ 995 NetCfg_RBC 5;
BA_ "GenSigSNA" SG_ 995 NetCfg_PTCM "0h";
BA_ "FlexKomIsMotorola" SG_ 995 NetCfg_PTCM 1;
BA_ "FlexKomComment" SG_ 995 NetCfg_PTCM "Network ECU config data for interior";
BA_ "FlexKomSigName" SG_ 995 NetCfg_PTCM "NET_CFG_DATA_INT";
BA_ "FlexKomSigLaenge" SG_ 995 NetCfg_PTCM 64;
BA_ "FlexKomSigStartPos" SG_ 995 NetCfg_PTCM 7;
BA_ "FlexKomSID" SG_ 995 NetCfg_PTCM 38;
BA_ "GenSigTimeout_IC" SG_ 995 NetCfg_PTCM 21000;
BA_ "GenSigTimeout_RF_HUB" SG_ 995 NetCfg_PTCM 21000;
BA_ "FlexKomSigStartValue" SG_ 995 NetCfg_PTCM "0300000000000000h";
BA_ "GenSigCycleTime" SG_ 995 NetCfg_PTCM 2000;
BA_ "GenSigSendType" SG_ 995 NetCfg_PTCM 5;
BA_ "GenSigSNA" SG_ 995 NetCfg_PSD_RT "0h";
BA_ "FlexKomIsMotorola" SG_ 995 NetCfg_PSD_RT 1;
BA_ "FlexKomComment" SG_ 995 NetCfg_PSD_RT "Network ECU config data for interior";
BA_ "FlexKomSigName" SG_ 995 NetCfg_PSD_RT "NET_CFG_DATA_INT";
BA_ "FlexKomSigLaenge" SG_ 995 NetCfg_PSD_RT 64;
BA_ "FlexKomSigStartPos" SG_ 995 NetCfg_PSD_RT 7;
BA_ "FlexKomSID" SG_ 995 NetCfg_PSD_RT 38;
BA_ "GenSigTimeout_IC" SG_ 995 NetCfg_PSD_RT 21000;
BA_ "GenSigTimeout_RF_HUB" SG_ 995 NetCfg_PSD_RT 21000;
BA_ "FlexKomSigStartValue" SG_ 995 NetCfg_PSD_RT "0300000000000000h";
BA_ "GenSigCycleTime" SG_ 995 NetCfg_PSD_RT 2000;
BA_ "GenSigSendType" SG_ 995 NetCfg_PSD_RT 5;
BA_ "GenSigSNA" SG_ 995 NetCfg_PSD_LT "0h";
BA_ "FlexKomIsMotorola" SG_ 995 NetCfg_PSD_LT 1;
BA_ "FlexKomComment" SG_ 995 NetCfg_PSD_LT "Network ECU config data for interior";
BA_ "FlexKomSigName" SG_ 995 NetCfg_PSD_LT "NET_CFG_DATA_INT";
BA_ "FlexKomSigLaenge" SG_ 995 NetCfg_PSD_LT 64;
BA_ "FlexKomSigStartPos" SG_ 995 NetCfg_PSD_LT 7;
BA_ "FlexKomSID" SG_ 995 NetCfg_PSD_LT 38;
BA_ "GenSigTimeout_IC" SG_ 995 NetCfg_PSD_LT 21000;
BA_ "GenSigTimeout_RF_HUB" SG_ 995 NetCfg_PSD_LT 21000;
BA_ "FlexKomSigStartValue" SG_ 995 NetCfg_PSD_LT "0300000000000000h";
BA_ "GenSigCycleTime" SG_ 995 NetCfg_PSD_LT 2000;
BA_ "GenSigSendType" SG_ 995 NetCfg_PSD_LT 5;
BA_ "GenSigSNA" SG_ 995 NetCfg_PLG "0h";
BA_ "FlexKomIsMotorola" SG_ 995 NetCfg_PLG 1;
BA_ "FlexKomComment" SG_ 995 NetCfg_PLG "Network ECU config data for interior";
BA_ "FlexKomSigName" SG_ 995 NetCfg_PLG "NET_CFG_DATA_INT";
BA_ "FlexKomSigLaenge" SG_ 995 NetCfg_PLG 64;
BA_ "FlexKomSigStartPos" SG_ 995 NetCfg_PLG 7;
BA_ "FlexKomSID" SG_ 995 NetCfg_PLG 38;
BA_ "GenSigTimeout_IC" SG_ 995 NetCfg_PLG 21000;
BA_ "GenSigTimeout_RF_HUB" SG_ 995 NetCfg_PLG 21000;
BA_ "FlexKomSigStartValue" SG_ 995 NetCfg_PLG "0300000000000000h";
BA_ "GenSigCycleTime" SG_ 995 NetCfg_PLG 2000;
BA_ "GenSigSendType" SG_ 995 NetCfg_PLG 5;
BA_ "GenSigSNA" SG_ 995 NetCfg_MSM_PASS "0h";
BA_ "FlexKomIsMotorola" SG_ 995 NetCfg_MSM_PASS 1;
BA_ "FlexKomComment" SG_ 995 NetCfg_MSM_PASS "Network ECU config data for interior";
BA_ "FlexKomSigName" SG_ 995 NetCfg_MSM_PASS "NET_CFG_DATA_INT";
BA_ "FlexKomSigLaenge" SG_ 995 NetCfg_MSM_PASS 64;
BA_ "FlexKomSigStartPos" SG_ 995 NetCfg_MSM_PASS 7;
BA_ "FlexKomSID" SG_ 995 NetCfg_MSM_PASS 38;
BA_ "GenSigTimeout_RF_HUB" SG_ 995 NetCfg_MSM_PASS 21000;
BA_ "FlexKomSigStartValue" SG_ 995 NetCfg_MSM_PASS "0300000000000000h";
BA_ "GenSigCycleTime" SG_ 995 NetCfg_MSM_PASS 2000;
BA_ "GenSigSendType" SG_ 995 NetCfg_MSM_PASS 5;
BA_ "GenSigSNA" SG_ 995 NetCfg_MSM "0h";
BA_ "FlexKomIsMotorola" SG_ 995 NetCfg_MSM 1;
BA_ "FlexKomComment" SG_ 995 NetCfg_MSM "Network ECU config data for interior";
BA_ "FlexKomSigName" SG_ 995 NetCfg_MSM "NET_CFG_DATA_INT";
BA_ "FlexKomSigLaenge" SG_ 995 NetCfg_MSM 64;
BA_ "FlexKomSigStartPos" SG_ 995 NetCfg_MSM 7;
BA_ "FlexKomSID" SG_ 995 NetCfg_MSM 38;
BA_ "GenSigTimeout_IC" SG_ 995 NetCfg_MSM 21000;
BA_ "GenSigTimeout_RF_HUB" SG_ 995 NetCfg_MSM 21000;
BA_ "FlexKomSigStartValue" SG_ 995 NetCfg_MSM "0300000000000000h";
BA_ "GenSigCycleTime" SG_ 995 NetCfg_MSM 2000;
BA_ "GenSigSendType" SG_ 995 NetCfg_MSM 5;
BA_ "GenSigSNA" SG_ 995 NetCfg_ITM "0h";
BA_ "FlexKomIsMotorola" SG_ 995 NetCfg_ITM 1;
BA_ "FlexKomComment" SG_ 995 NetCfg_ITM "Network ECU config data for interior";
BA_ "FlexKomSigName" SG_ 995 NetCfg_ITM "NET_CFG_DATA_INT";
BA_ "FlexKomSigLaenge" SG_ 995 NetCfg_ITM 64;
BA_ "FlexKomSigStartPos" SG_ 995 NetCfg_ITM 7;
BA_ "FlexKomSID" SG_ 995 NetCfg_ITM 38;
BA_ "GenSigTimeout_IC" SG_ 995 NetCfg_ITM 21000;
BA_ "GenSigTimeout_RF_HUB" SG_ 995 NetCfg_ITM 21000;
BA_ "FlexKomSigStartValue" SG_ 995 NetCfg_ITM "0300000000000000h";
BA_ "GenSigCycleTime" SG_ 995 NetCfg_ITM 2000;
BA_ "GenSigSendType" SG_ 995 NetCfg_ITM 5;
BA_ "GenSigSNA" SG_ 995 NetCfg_ICS_R "0h";
BA_ "FlexKomIsMotorola" SG_ 995 NetCfg_ICS_R 1;
BA_ "FlexKomComment" SG_ 995 NetCfg_ICS_R "Network ECU config data for interior";
BA_ "FlexKomSigName" SG_ 995 NetCfg_ICS_R "NET_CFG_DATA_INT";
BA_ "FlexKomSigLaenge" SG_ 995 NetCfg_ICS_R 64;
BA_ "FlexKomSigStartPos" SG_ 995 NetCfg_ICS_R 7;
BA_ "FlexKomSID" SG_ 995 NetCfg_ICS_R 38;
BA_ "GenSigTimeout_RF_HUB" SG_ 995 NetCfg_ICS_R 21000;
BA_ "FlexKomSigStartValue" SG_ 995 NetCfg_ICS_R "0300000000000000h";
BA_ "GenSigCycleTime" SG_ 995 NetCfg_ICS_R 2000;
BA_ "GenSigSendType" SG_ 995 NetCfg_ICS_R 5;
BA_ "GenSigSNA" SG_ 995 NetCfg_ICS_I "0h";
BA_ "FlexKomIsMotorola" SG_ 995 NetCfg_ICS_I 1;
BA_ "FlexKomComment" SG_ 995 NetCfg_ICS_I "Network ECU config data for interior";
BA_ "FlexKomSigName" SG_ 995 NetCfg_ICS_I "NET_CFG_DATA_INT";
BA_ "FlexKomSigLaenge" SG_ 995 NetCfg_ICS_I 64;
BA_ "FlexKomSigStartPos" SG_ 995 NetCfg_ICS_I 7;
BA_ "FlexKomSID" SG_ 995 NetCfg_ICS_I 38;
BA_ "GenSigTimeout_RF_HUB" SG_ 995 NetCfg_ICS_I 21000;
BA_ "FlexKomSigStartValue" SG_ 995 NetCfg_ICS_I "0300000000000000h";
BA_ "GenSigCycleTime" SG_ 995 NetCfg_ICS_I 2000;
BA_ "GenSigSendType" SG_ 995 NetCfg_ICS_I 5;
BA_ "GenSigSNA" SG_ 995 NetCfg_HVAC_R "0h";
BA_ "FlexKomIsMotorola" SG_ 995 NetCfg_HVAC_R 1;
BA_ "FlexKomComment" SG_ 995 NetCfg_HVAC_R "Network ECU config data for interior";
BA_ "FlexKomSigName" SG_ 995 NetCfg_HVAC_R "NET_CFG_DATA_INT";
BA_ "FlexKomSigLaenge" SG_ 995 NetCfg_HVAC_R 64;
BA_ "FlexKomSigStartPos" SG_ 995 NetCfg_HVAC_R 7;
BA_ "FlexKomSID" SG_ 995 NetCfg_HVAC_R 38;
BA_ "GenSigTimeout_RF_HUB" SG_ 995 NetCfg_HVAC_R 21000;
BA_ "FlexKomSigStartValue" SG_ 995 NetCfg_HVAC_R "0300000000000000h";
BA_ "GenSigCycleTime" SG_ 995 NetCfg_HVAC_R 2000;
BA_ "GenSigSendType" SG_ 995 NetCfg_HVAC_R 5;
BA_ "GenSigSNA" SG_ 995 NetCfg_HVAC "0h";
BA_ "FlexKomIsMotorola" SG_ 995 NetCfg_HVAC 1;
BA_ "FlexKomComment" SG_ 995 NetCfg_HVAC "Network ECU config data for interior";
BA_ "FlexKomSigName" SG_ 995 NetCfg_HVAC "NET_CFG_DATA_INT";
BA_ "FlexKomSigLaenge" SG_ 995 NetCfg_HVAC 64;
BA_ "FlexKomSigStartPos" SG_ 995 NetCfg_HVAC 7;
BA_ "FlexKomSID" SG_ 995 NetCfg_HVAC 38;
BA_ "GenSigTimeout_IC" SG_ 995 NetCfg_HVAC 21000;
BA_ "GenSigTimeout_RF_HUB" SG_ 995 NetCfg_HVAC 21000;
BA_ "FlexKomSigStartValue" SG_ 995 NetCfg_HVAC "0300000000000000h";
BA_ "GenSigCycleTime" SG_ 995 NetCfg_HVAC 2000;
BA_ "GenSigSendType" SG_ 995 NetCfg_HVAC 5;
BA_ "GenSigSNA" SG_ 995 NetCfg_HFM_CTM "0h";
BA_ "FlexKomIsMotorola" SG_ 995 NetCfg_HFM_CTM 1;
BA_ "FlexKomComment" SG_ 995 NetCfg_HFM_CTM "Network ECU config data for interior";
BA_ "FlexKomSigName" SG_ 995 NetCfg_HFM_CTM "NET_CFG_DATA_INT";
BA_ "FlexKomSigLaenge" SG_ 995 NetCfg_HFM_CTM 64;
BA_ "FlexKomSigStartPos" SG_ 995 NetCfg_HFM_CTM 7;
BA_ "FlexKomSID" SG_ 995 NetCfg_HFM_CTM 38;
BA_ "GenSigTimeout_RF_HUB" SG_ 995 NetCfg_HFM_CTM 21000;
BA_ "FlexKomSigStartValue" SG_ 995 NetCfg_HFM_CTM "0300000000000000h";
BA_ "GenSigCycleTime" SG_ 995 NetCfg_HFM_CTM 2000;
BA_ "GenSigSendType" SG_ 995 NetCfg_HFM_CTM 5;
BA_ "GenSigSNA" SG_ 995 NetCfg_FSM "0h";
BA_ "FlexKomIsMotorola" SG_ 995 NetCfg_FSM 1;
BA_ "FlexKomComment" SG_ 995 NetCfg_FSM "Network ECU config data for interior";
BA_ "FlexKomSigName" SG_ 995 NetCfg_FSM "NET_CFG_DATA_INT";
BA_ "FlexKomSigLaenge" SG_ 995 NetCfg_FSM 64;
BA_ "FlexKomSigStartPos" SG_ 995 NetCfg_FSM 7;
BA_ "FlexKomSID" SG_ 995 NetCfg_FSM 38;
BA_ "GenSigTimeout_IC" SG_ 995 NetCfg_FSM 21000;
BA_ "GenSigTimeout_RF_HUB" SG_ 995 NetCfg_FSM 21000;
BA_ "FlexKomSigStartValue" SG_ 995 NetCfg_FSM "0300000000000000h";
BA_ "GenSigCycleTime" SG_ 995 NetCfg_FSM 2000;
BA_ "GenSigSendType" SG_ 995 NetCfg_FSM 5;
BA_ "GenSigSNA" SG_ 995 NetCfg_DVD_CDM "0h";
BA_ "FlexKomIsMotorola" SG_ 995 NetCfg_DVD_CDM 1;
BA_ "FlexKomComment" SG_ 995 NetCfg_DVD_CDM "Network ECU config data for interior";
BA_ "FlexKomSigName" SG_ 995 NetCfg_DVD_CDM "NET_CFG_DATA_INT";
BA_ "FlexKomSigLaenge" SG_ 995 NetCfg_DVD_CDM 64;
BA_ "FlexKomSigStartPos" SG_ 995 NetCfg_DVD_CDM 7;
BA_ "FlexKomSID" SG_ 995 NetCfg_DVD_CDM 38;
BA_ "GenSigTimeout_RF_HUB" SG_ 995 NetCfg_DVD_CDM 21000;
BA_ "FlexKomSigStartValue" SG_ 995 NetCfg_DVD_CDM "0300000000000000h";
BA_ "GenSigCycleTime" SG_ 995 NetCfg_DVD_CDM 2000;
BA_ "GenSigSendType" SG_ 995 NetCfg_DVD_CDM 5;
BA_ "GenSigSNA" SG_ 995 NetCfg_DTV "0h";
BA_ "FlexKomIsMotorola" SG_ 995 NetCfg_DTV 1;
BA_ "FlexKomComment" SG_ 995 NetCfg_DTV "Network ECU config data for interior";
BA_ "FlexKomSigName" SG_ 995 NetCfg_DTV "NET_CFG_DATA_INT";
BA_ "FlexKomSigLaenge" SG_ 995 NetCfg_DTV 64;
BA_ "FlexKomSigStartPos" SG_ 995 NetCfg_DTV 7;
BA_ "FlexKomSID" SG_ 995 NetCfg_DTV 38;
BA_ "GenSigTimeout_RF_HUB" SG_ 995 NetCfg_DTV 21000;
BA_ "FlexKomSigStartValue" SG_ 995 NetCfg_DTV "0300000000000000h";
BA_ "GenSigCycleTime" SG_ 995 NetCfg_DTV 2000;
BA_ "GenSigSendType" SG_ 995 NetCfg_DTV 5;
BA_ "GenSigSNA" SG_ 995 NetCfg_DCSD "0h";
BA_ "FlexKomIsMotorola" SG_ 995 NetCfg_DCSD 1;
BA_ "FlexKomComment" SG_ 995 NetCfg_DCSD "Network ECU config data for interior";
BA_ "FlexKomSigName" SG_ 995 NetCfg_DCSD "NET_CFG_DATA_INT";
BA_ "FlexKomSigLaenge" SG_ 995 NetCfg_DCSD 64;
BA_ "FlexKomSigStartPos" SG_ 995 NetCfg_DCSD 7;
BA_ "FlexKomSID" SG_ 995 NetCfg_DCSD 38;
BA_ "GenSigTimeout_RF_HUB" SG_ 995 NetCfg_DCSD 21000;
BA_ "FlexKomSigStartValue" SG_ 995 NetCfg_DCSD "0300000000000000h";
BA_ "GenSigCycleTime" SG_ 995 NetCfg_DCSD 2000;
BA_ "GenSigSendType" SG_ 995 NetCfg_DCSD 5;
BA_ "GenSigSNA" SG_ 995 NetCfg_DCM_RR "0h";
BA_ "FlexKomIsMotorola" SG_ 995 NetCfg_DCM_RR 1;
BA_ "FlexKomComment" SG_ 995 NetCfg_DCM_RR "Network ECU config data for interior";
BA_ "FlexKomSigName" SG_ 995 NetCfg_DCM_RR "NET_CFG_DATA_INT";
BA_ "FlexKomSigLaenge" SG_ 995 NetCfg_DCM_RR 64;
BA_ "FlexKomSigStartPos" SG_ 995 NetCfg_DCM_RR 7;
BA_ "FlexKomSID" SG_ 995 NetCfg_DCM_RR 38;
BA_ "GenSigTimeout_IC" SG_ 995 NetCfg_DCM_RR 21000;
BA_ "GenSigTimeout_RF_HUB" SG_ 995 NetCfg_DCM_RR 21000;
BA_ "FlexKomSigStartValue" SG_ 995 NetCfg_DCM_RR "0300000000000000h";
BA_ "GenSigCycleTime" SG_ 995 NetCfg_DCM_RR 2000;
BA_ "GenSigSendType" SG_ 995 NetCfg_DCM_RR 5;
BA_ "GenSigSNA" SG_ 995 NetCfg_DCM_RL "0h";
BA_ "FlexKomIsMotorola" SG_ 995 NetCfg_DCM_RL 1;
BA_ "FlexKomComment" SG_ 995 NetCfg_DCM_RL "Network ECU config data for interior";
BA_ "FlexKomSigName" SG_ 995 NetCfg_DCM_RL "NET_CFG_DATA_INT";
BA_ "FlexKomSigLaenge" SG_ 995 NetCfg_DCM_RL 64;
BA_ "FlexKomSigStartPos" SG_ 995 NetCfg_DCM_RL 7;
BA_ "FlexKomSID" SG_ 995 NetCfg_DCM_RL 38;
BA_ "GenSigTimeout_IC" SG_ 995 NetCfg_DCM_RL 21000;
BA_ "GenSigTimeout_RF_HUB" SG_ 995 NetCfg_DCM_RL 21000;
BA_ "FlexKomSigStartValue" SG_ 995 NetCfg_DCM_RL "0300000000000000h";
BA_ "GenSigCycleTime" SG_ 995 NetCfg_DCM_RL 2000;
BA_ "GenSigSendType" SG_ 995 NetCfg_DCM_RL 5;
BA_ "GenSigSNA" SG_ 995 NetCfg_DCM_PASS "0h";
BA_ "FlexKomIsMotorola" SG_ 995 NetCfg_DCM_PASS 1;
BA_ "FlexKomComment" SG_ 995 NetCfg_DCM_PASS "Network ECU config data for interior";
BA_ "FlexKomSigName" SG_ 995 NetCfg_DCM_PASS "NET_CFG_DATA_INT";
BA_ "FlexKomSigLaenge" SG_ 995 NetCfg_DCM_PASS 64;
BA_ "FlexKomSigStartPos" SG_ 995 NetCfg_DCM_PASS 7;
BA_ "FlexKomSID" SG_ 995 NetCfg_DCM_PASS 38;
BA_ "GenSigTimeout_IC" SG_ 995 NetCfg_DCM_PASS 21000;
BA_ "GenSigTimeout_RF_HUB" SG_ 995 NetCfg_DCM_PASS 21000;
BA_ "FlexKomSigStartValue" SG_ 995 NetCfg_DCM_PASS "0300000000000000h";
BA_ "GenSigCycleTime" SG_ 995 NetCfg_DCM_PASS 2000;
BA_ "GenSigSendType" SG_ 995 NetCfg_DCM_PASS 5;
BA_ "GenSigSNA" SG_ 995 NetCfg_DCM_DR "0h";
BA_ "FlexKomIsMotorola" SG_ 995 NetCfg_DCM_DR 1;
BA_ "FlexKomComment" SG_ 995 NetCfg_DCM_DR "Network ECU config data for interior";
BA_ "FlexKomSigName" SG_ 995 NetCfg_DCM_DR "NET_CFG_DATA_INT";
BA_ "FlexKomSigLaenge" SG_ 995 NetCfg_DCM_DR 64;
BA_ "FlexKomSigStartPos" SG_ 995 NetCfg_DCM_DR 7;
BA_ "FlexKomSID" SG_ 995 NetCfg_DCM_DR 38;
BA_ "GenSigTimeout_IC" SG_ 995 NetCfg_DCM_DR 21000;
BA_ "GenSigTimeout_RF_HUB" SG_ 995 NetCfg_DCM_DR 21000;
BA_ "FlexKomSigStartValue" SG_ 995 NetCfg_DCM_DR "0300000000000000h";
BA_ "GenSigCycleTime" SG_ 995 NetCfg_DCM_DR 2000;
BA_ "GenSigSendType" SG_ 995 NetCfg_DCM_DR 5;
BA_ "GenSigSNA" SG_ 995 NetCfg_CVPM "0h";
BA_ "FlexKomIsMotorola" SG_ 995 NetCfg_CVPM 1;
BA_ "FlexKomComment" SG_ 995 NetCfg_CVPM "Network ECU config data for interior";
BA_ "FlexKomSigName" SG_ 995 NetCfg_CVPM "NET_CFG_DATA_INT";
BA_ "FlexKomSigLaenge" SG_ 995 NetCfg_CVPM 64;
BA_ "FlexKomSigStartPos" SG_ 995 NetCfg_CVPM 7;
BA_ "FlexKomSID" SG_ 995 NetCfg_CVPM 38;
BA_ "GenSigTimeout_RF_HUB" SG_ 995 NetCfg_CVPM 21000;
BA_ "FlexKomSigStartValue" SG_ 995 NetCfg_CVPM "0300000000000000h";
BA_ "GenSigCycleTime" SG_ 995 NetCfg_CVPM 2000;
BA_ "GenSigSendType" SG_ 995 NetCfg_CVPM 5;
BA_ "GenSigSNA" SG_ 995 NetCfg_CSWM "0h";
BA_ "FlexKomIsMotorola" SG_ 995 NetCfg_CSWM 1;
BA_ "FlexKomComment" SG_ 995 NetCfg_CSWM "Network ECU config data for interior";
BA_ "FlexKomSigName" SG_ 995 NetCfg_CSWM "NET_CFG_DATA_INT";
BA_ "FlexKomSigLaenge" SG_ 995 NetCfg_CSWM 64;
BA_ "FlexKomSigStartPos" SG_ 995 NetCfg_CSWM 7;
BA_ "FlexKomSID" SG_ 995 NetCfg_CSWM 38;
BA_ "GenSigTimeout_IC" SG_ 995 NetCfg_CSWM 21000;
BA_ "GenSigTimeout_RF_HUB" SG_ 995 NetCfg_CSWM 21000;
BA_ "FlexKomSigStartValue" SG_ 995 NetCfg_CSWM "0300000000000000h";
BA_ "GenSigCycleTime" SG_ 995 NetCfg_CSWM 2000;
BA_ "GenSigSendType" SG_ 995 NetCfg_CSWM 5;
BA_ "GenSigSNA" SG_ 995 NetCfg_CRSM "0h";
BA_ "FlexKomIsMotorola" SG_ 995 NetCfg_CRSM 1;
BA_ "FlexKomComment" SG_ 995 NetCfg_CRSM "Network ECU config data for interior";
BA_ "FlexKomSigName" SG_ 995 NetCfg_CRSM "NET_CFG_DATA_INT";
BA_ "FlexKomSigLaenge" SG_ 995 NetCfg_CRSM 64;
BA_ "FlexKomSigStartPos" SG_ 995 NetCfg_CRSM 7;
BA_ "FlexKomSID" SG_ 995 NetCfg_CRSM 38;
BA_ "GenSigTimeout_RF_HUB" SG_ 995 NetCfg_CRSM 21000;
BA_ "FlexKomSigStartValue" SG_ 995 NetCfg_CRSM "0300000000000000h";
BA_ "GenSigCycleTime" SG_ 995 NetCfg_CRSM 2000;
BA_ "GenSigSendType" SG_ 995 NetCfg_CRSM 5;
BA_ "GenSigSNA" SG_ 995 NetCfg_CLOCK "0h";
BA_ "FlexKomIsMotorola" SG_ 995 NetCfg_CLOCK 1;
BA_ "FlexKomComment" SG_ 995 NetCfg_CLOCK "Network ECU config data for interior";
BA_ "FlexKomSigName" SG_ 995 NetCfg_CLOCK "NET_CFG_DATA_INT";
BA_ "FlexKomSigLaenge" SG_ 995 NetCfg_CLOCK 64;
BA_ "FlexKomSigStartPos" SG_ 995 NetCfg_CLOCK 7;
BA_ "FlexKomSID" SG_ 995 NetCfg_CLOCK 38;
BA_ "GenSigTimeout_RF_HUB" SG_ 995 NetCfg_CLOCK 21000;
BA_ "FlexKomSigStartValue" SG_ 995 NetCfg_CLOCK "0300000000000000h";
BA_ "GenSigCycleTime" SG_ 995 NetCfg_CLOCK 2000;
BA_ "GenSigSendType" SG_ 995 NetCfg_CLOCK 5;
BA_ "GenSigSNA" SG_ 995 NetCfg_CBC_IN "0h";
BA_ "FlexKomIsMotorola" SG_ 995 NetCfg_CBC_IN 1;
BA_ "FlexKomComment" SG_ 995 NetCfg_CBC_IN "Network ECU config data for interior";
BA_ "FlexKomSigName" SG_ 995 NetCfg_CBC_IN "NET_CFG_DATA_INT";
BA_ "FlexKomSigLaenge" SG_ 995 NetCfg_CBC_IN 64;
BA_ "FlexKomSigStartPos" SG_ 995 NetCfg_CBC_IN 7;
BA_ "FlexKomSID" SG_ 995 NetCfg_CBC_IN 38;
BA_ "GenSigTimeout_IC" SG_ 995 NetCfg_CBC_IN 21000;
BA_ "GenSigTimeout_RF_HUB" SG_ 995 NetCfg_CBC_IN 21000;
BA_ "FlexKomSigStartValue" SG_ 995 NetCfg_CBC_IN "0300000000000000h";
BA_ "GenSigCycleTime" SG_ 995 NetCfg_CBC_IN 2000;
BA_ "GenSigSendType" SG_ 995 NetCfg_CBC_IN 5;
BA_ "GenSigSNA" SG_ 995 NetCfg_BSM "0h";
BA_ "FlexKomIsMotorola" SG_ 995 NetCfg_BSM 1;
BA_ "FlexKomComment" SG_ 995 NetCfg_BSM "Network ECU config data for interior";
BA_ "FlexKomSigName" SG_ 995 NetCfg_BSM "NET_CFG_DATA_INT";
BA_ "FlexKomSigLaenge" SG_ 995 NetCfg_BSM 64;
BA_ "FlexKomSigStartPos" SG_ 995 NetCfg_BSM 7;
BA_ "FlexKomSID" SG_ 995 NetCfg_BSM 38;
BA_ "GenSigTimeout_IC" SG_ 995 NetCfg_BSM 21000;
BA_ "GenSigTimeout_RF_HUB" SG_ 995 NetCfg_BSM 21000;
BA_ "FlexKomSigStartValue" SG_ 995 NetCfg_BSM "0300000000000000h";
BA_ "GenSigCycleTime" SG_ 995 NetCfg_BSM 2000;
BA_ "GenSigSendType" SG_ 995 NetCfg_BSM 5;
BA_ "GenSigSNA" SG_ 995 NetCfg_ANC_I "0h";
BA_ "FlexKomIsMotorola" SG_ 995 NetCfg_ANC_I 1;
BA_ "FlexKomComment" SG_ 995 NetCfg_ANC_I "Network ECU config data for interior";
BA_ "FlexKomSigName" SG_ 995 NetCfg_ANC_I "NET_CFG_DATA_INT";
BA_ "FlexKomSigLaenge" SG_ 995 NetCfg_ANC_I 64;
BA_ "FlexKomSigStartPos" SG_ 995 NetCfg_ANC_I 7;
BA_ "FlexKomSID" SG_ 995 NetCfg_ANC_I 38;
BA_ "GenSigTimeout_RF_HUB" SG_ 995 NetCfg_ANC_I 21000;
BA_ "FlexKomSigStartValue" SG_ 995 NetCfg_ANC_I "0300000000000000h";
BA_ "GenSigCycleTime" SG_ 995 NetCfg_ANC_I 2000;
BA_ "GenSigSendType" SG_ 995 NetCfg_ANC_I 5;
BA_ "GenSigSNA" SG_ 995 NetCfg_AMP_I "0h";
BA_ "FlexKomIsMotorola" SG_ 995 NetCfg_AMP_I 1;
BA_ "FlexKomComment" SG_ 995 NetCfg_AMP_I "Network ECU config data for interior";
BA_ "FlexKomSigName" SG_ 995 NetCfg_AMP_I "NET_CFG_DATA_INT";
BA_ "FlexKomSigLaenge" SG_ 995 NetCfg_AMP_I 64;
BA_ "FlexKomSigStartPos" SG_ 995 NetCfg_AMP_I 7;
BA_ "FlexKomSID" SG_ 995 NetCfg_AMP_I 38;
BA_ "GenSigTimeout_RF_HUB" SG_ 995 NetCfg_AMP_I 21000;
BA_ "FlexKomSigStartValue" SG_ 995 NetCfg_AMP_I "0300000000000000h";
BA_ "GenSigCycleTime" SG_ 995 NetCfg_AMP_I 2000;
BA_ "GenSigSendType" SG_ 995 NetCfg_AMP_I 5;
BA_ "GenSigSNA" SG_ 995 NET_CFG_STAT_INT "3h";
BA_ "FlexKomIsMotorola" SG_ 995 NET_CFG_STAT_INT 1;
BA_ "FlexKomComment" SG_ 995 NET_CFG_STAT_INT "Network ECU config data for interior";
BA_ "FlexKomSigName" SG_ 995 NET_CFG_STAT_INT "NET_CFG_DATA_INT";
BA_ "FlexKomSigLaenge" SG_ 995 NET_CFG_STAT_INT 64;
BA_ "FlexKomSigStartPos" SG_ 995 NET_CFG_STAT_INT 7;
BA_ "FlexKomSID" SG_ 995 NET_CFG_STAT_INT 38;
BA_ "GenSigTimeout_IC" SG_ 995 NET_CFG_STAT_INT 21000;
BA_ "GenSigTimeout_RF_HUB" SG_ 995 NET_CFG_STAT_INT 21000;
BA_ "GenSigStartValue" SG_ 995 NET_CFG_STAT_INT 3;
BA_ "FlexKomSigStartValue" SG_ 995 NET_CFG_STAT_INT "0300000000000000h";
BA_ "GenSigCycleTime" SG_ 995 NET_CFG_STAT_INT 2000;
BA_ "GenSigSendType" SG_ 995 NET_CFG_STAT_INT 5;
VAL_ 1026 WakeupRsn_IC 255 "SNA" 1 "IGN" 0 "NETWORK" ;
VAL_ 1026 WakeupCnt_IC 255 "SNA" ;
VAL_ 1026 Nw_Id_IC 255 "SNA" 2 "AUDIO_TELE" 1 "BODY" 0 "POWERTRAIN" ;
VAL_ 1026 NM_Ud_Srv_IC 255 "NO_USER_DATA" 15 "AWAKE_BC" 2 "WAKEUP_SA" ;
VAL_ 1026 NM_Ud_Launch_IC 63 "SNA" 4 "BROADCAST" ;
VAL_ 1026 NM_Successor_IC 255 "SNA" ;
VAL_ 1026 NM_Mode_IC 255 "SNA" 254 "ALIVE" 253 "RING" 252 "LHOM" ;
VAL_ 1025 WakeupRsn_CBC 25 "ELCM" 24 "REFUEL" 255 "SNA" 23 "CON_LAMP_LD" 22 "CARGO_SW" 21 "PD_SW" 20 "HL_SW" 19 "BRK_SW" 18 "SS_SW" 17 "HAZARD_SW" 16 "PASS_LK_SW" 15 "DRV_LK_SW" 14 "TK_FG_SW" 13 "HRD_TOP_STEALTH" 12 "HOOD_AJAR" 11 "FG_AJAR" 10 "TLG_AJAR" 9 "R_R_AJAR" 8 "L_R_AJAR" 7 "PSG_AJAR" 6 "DRV_AJAR" 5 "LIN_THREE" 4 "LIN_TWO" 3 "LIN_ONE" 2 "CAN_I" 1 "CAN_C" 0 "NETWORK" ;
VAL_ 1025 WakeupCnt_CBC 255 "SNA" ;
VAL_ 1025 Nw_Id_CBC 255 "SNA" 2 "AUDIO_TELE" 1 "BODY" 0 "POWERTRAIN" ;
VAL_ 1025 NM_Ud_Srv_CBC 255 "NO_USER_DATA" 15 "AWAKE_BC" 2 "WAKEUP_SA" ;
VAL_ 1025 NM_Ud_Launch_CBC 63 "SNA" 4 "BROADCAST" ;
VAL_ 1025 NM_Successor_CBC 255 "SNA" ;
VAL_ 1025 NM_Mode_CBC 255 "SNA" 254 "ALIVE" 253 "RING" 252 "LHOM" ;
VAL_ 1024 WakeupRsn_RF_HUB 255 "SNA" 10 "CLUTCH" 9 "TIMER" 8 "RESET" 7 "RF_INPUT" 6 "AP5" 5 "AP4" 4 "AP3" 3 "AP2" 2 "AP1" 1 "SSB" 0 "NETWORK" ;
VAL_ 1024 WakeupCnt_RF_HUB 255 "SNA" ;
VAL_ 1024 Nw_Id_RF_HUB 255 "SNA" 2 "AUDIO_TELE" 1 "BODY" 0 "POWERTRAIN" ;
VAL_ 1024 NM_Ud_Srv_RF_HUB 255 "NO_USER_DATA" 15 "AWAKE_BC" 2 "WAKEUP_SA" ;
VAL_ 1024 NM_Ud_Launch_RF_HUB 63 "SNA" 4 "BROADCAST" ;
VAL_ 1024 NM_Successor_RF_HUB 255 "SNA" ;
VAL_ 1024 NM_Mode_RF_HUB 255 "SNA" 254 "ALIVE" 253 "RING" 252 "LHOM" ;
VAL_ 1015 EC_ECUCfg8_Stat 3 "SNA" 2 "REQUEST_DATA" 1 "PROGAMMED" 0 "NA" ;
VAL_ 1014 EC_ECUCfg7_Stat 3 "SNA" 2 "REQUEST_DATA" 1 "PROGAMMED" 0 "NA" ;
VAL_ 1013 EC_ECUCfg6_Stat 3 "SNA" 2 "REQUEST_DATA" 1 "PROGAMMED" 0 "NA" ;
VAL_ 1012 EC_ECUCfg5_Stat 3 "SNA" 2 "REQUEST_DATA" 1 "PROGAMMED" 0 "NA" ;
VAL_ 1011 EC_ECUCfg4_Stat 3 "SNA" 2 "REQUEST_DATA" 1 "PROGAMMED" 0 "NA" ;
VAL_ 1010 EC_ECUCfg3_Stat 3 "SNA" 2 "REQUEST_DATA" 1 "PROGAMMED" 0 "NA" ;
VAL_ 1009 EC_ECUCfg2_Stat 3 "SNA" 2 "REQUEST_DATA" 1 "PROGAMMED" 0 "NA" ;
VAL_ 1008 EC_ECUCfg1_Stat 3 "SNA" 2 "REQUEST_DATA" 1 "PROGAMMED" 0 "NA" ;
VAL_ 1003 VC_VehCfg4_Stat 3 "SNA" 2 "REQUEST_DATA" 1 "PROGAMMED" 0 "NA" ;
VAL_ 1003 VC_TIRE_CIRCUMF 65535 "SNA" ;
VAL_ 1003 VC_TCASE_LO_RATIO 65535 "SNA" ;
VAL_ 1003 VC_TCASE_HI_RATIO 16383 "SNA" ;
VAL_ 1003 VC_AXLE_RATIO 65535 "SNA" ;
VAL_ 1002 VC_WIN_EXPR_FEAT 3 "WIN_EXPR_NN" 2 "WIN_EXPR_ALL" 1 "WIN_EXPR_FT" 0 "WIN_EXPR_DRV" ;
VAL_ 1002 VC_WHL_BASE 3 "SNA" 2 "XLONG" 1 "LONG" 0 "SHORT" ;
VAL_ 1002 VC_VehCfg3_Stat 3 "SNA" 2 "REQUEST_DATA" 1 "PROGAMMED" 0 "NA" ;
VAL_ 1002 VC_VEH_BRAND 15 "SNA" 12 "RAM" 11 "MASERATI" 10 "LANCIA" 9 "FIAT" 8 "ALPHA" 7 "FREIGHTLINER" 6 "VOLKSWAGEN" 5 "MITSUBISHI" 4 "MERCEDES_BENZ" 3 "JEEP" 2 "DODGE" 1 "CHRYSLER" ;
VAL_ 1002 VC_TcaseTyp 15 "Tcase_256_3022" 14 "Tcase_156" 13 "Tcase_BW4440" 12 "Tcase_MAS_ATC" 11 "Tcase_273" 10 "BW4447_49_WS" 9 "Tcase_243" 8 "BW4447_WOS" 7 "Tcase_241" 6 "Tcase_246" 5 "Tcase_BW4446" 4 "Tcase_BW4444" 3 "Tcase_253_1522" 2 "BW4445_46_48_WS" 1 "TCASE_143_144" 0 "NOT_PRSNT" ;
VAL_ 1002 VC_Liftgate_Trunk 3 "SNA" 2 "MANUAL_LG" 1 "PLG" 0 "TRUNK" ;
VAL_ 1002 VC_HVAC_Config 15 "SNA" 6 "2_ZN_MTC_p_RR" 5 "2_ZN_ATC_p_RR" 4 "2_ZN_ATC" 3 "2_ZN_MTC" 2 "1_ZN_ATC" 1 "1_ZN_MTC_p_RR" 0 "1_ZN_MTC" ;
VAL_ 1002 VC_FUEL_CAP 255 "SNA" ;
VAL_ 1002 VC_ChassisType 127 "SNA" ;
VAL_ 1001 VC_VehCfg2_Stat 3 "SNA" 2 "REQUEST_DATA" 1 "PROGAMMED" 0 "NA" ;
VAL_ 1001 VC_SpecialPKG_IC 255 "SNA" 247 "VARVATOS" 246 "DODGE_100" 27 "RAM_1500" 26 "PWGN_Laramie" 25 "SPORT" 24 "HD_DX" 23 "POWERWAGON" 22 "ORT" 21 "MOSSY_OAK" 20 "LIMITED" 19 "LONESTAR" 18 "LONGHORN" 17 "BIGHORN" 16 "LARAMIE" 8 "Scat" 7 "Shaker" 6 "Hellcat" 5 "MOPAR" 4 "PKG_SUPERBEE" 3 "PKG_BEATS" 2 "PKG_300S" 1 "PKG_70JP" 0 "NONE" ;
VAL_ 1001 VC_ShftInd_Prsnt 3 "PGSI" 2 "PSI" 1 "GSI" 0 "NONE" ;
VAL_ 1001 VC_PwrIvtrTyp 2 "LchSw" 1 "MtrySw" 0 "NoPwrIvtr" ;
VAL_ 1001 VC_MaxLdPressRrTr 255 "SNA" ;
VAL_ 1001 VC_MaxLdPressFtTr 255 "SNA" ;
VAL_ 1001 VC_MaseratiMd 3 "SNA" 2 "RACE" 1 "GTS" 0 "NORMAL" ;
VAL_ 1001 VC_LgtLdPressRrTr 255 "SNA" ;
VAL_ 1001 VC_LgtLdPressFtTr 255 "SNA" ;
VAL_ 1000 VC_XWD 3 "4WD" 2 "ALLWD" 1 "2RR" 0 "2FT" ;
VAL_ 1000 VC_VehCfg1_Stat 3 "SNA" 2 "REQUEST_DATA" 1 "PROGAMMED" 0 "NA" ;
VAL_ 1000 VC_VEH_LINE 255 "SNA" 83 "VEH_UT" 82 "VEH_UF" 81 "VEH_KL" 80 "VEH_PF" 53 "VEH_DT" 52 "VEH_WL" 51 "VEH_RA" 50 "VEH_M157" 49 "VEH_JL" 48 "VEH_DF" 47 "VEH_WS" 46 "VEH_M161" 45 "VEH_RU" 44 "VEH_LA" 43 "VEH_ZD" 42 "VEH_M156" 41 "VEH_LD" 39 "VEH_DX" 35 "VEH_WD" 34 "VEH_DJ" 33 "VEH_DP" 32 "VEH_DD" 31 "VEH_D2" 29 "VEH_DS" 22 "VEH_JC" 2 "VEH_LX" 1 "VEH_WK" 0 "VEH_NONE" ;
VAL_ 1000 VC_SpecialPKG 255 "SNA" 0 "NONE" ;
VAL_ 1000 VC_ShftrTyp 15 "SNA" 14 "TYPE_PS5" 13 "TYPE_MS7" 12 "TYPE_MS7S" 11 "TYPE_RS4" 10 "TYPE_MS7M156" 9 "TYPE_MS7D" 8 "TYPE_ERS4ESW" 7 "TYPE_RS5L" 6 "TYPE_RS5S" 5 "TYPE_RS5M" 4 "TYPE_AS5" 3 "TYPE_ERS5" 2 "TYPE_AS4" 1 "TYPE_ERS4" 0 "TYPE_NA" ;
VAL_ 1000 VC_PTS_DispTyp 7 "SNA" 2 "AUDIO_DISP" 1 "CCN_DISP" 0 "HEAD_DISP" ;
VAL_ 1000 VC_PTS_Config 3 "SEMI" 1 "FRT_REAR" 0 "REAR" ;
VAL_ 1000 VC_MODEL_YEAR 63 "SNA" ;
VAL_ 1000 VC_MAX_VEH_SPD 255 "SNA" ;
VAL_ 1000 VC_LHD_RHD 3 "SNA" 2 "RHD" 1 "LHD" 0 "NA" ;
VAL_ 1000 VC_COUNTRY 31 "COUNTRY_SNA" 21 "ECE" 20 "S_KOR" 17 "EGYPT" 16 "CHINA" 15 "BRZ" 14 "MEX" 13 "VEN" 12 "GULF" 11 "IND" 10 "AUS" 9 "MLY" 8 "SWISS" 7 "GER" 6 "JPN" 5 "GB" 4 "CND" 3 "EU" 2 "USA" 0 "ROW" ;
VAL_ 1000 VC_BODY_STYLE 15 "BODY_SNA" 8 "BODY_4DMP" 7 "BODY_4DP" 6 "BODY_2DP" 5 "BODY_4DH" 4 "BODY_WAGON" 3 "BODY_CONV" 2 "BODY_2DS" 1 "BODY_4DS" 0 "BODY_NONE" ;
VAL_ 996 NET_CFG_STAT_PT 3 "SNA" 2 "REQUEST_DATA" 1 "PROGAMMED" 0 "NA" ;
VAL_ 995 NET_CFG_STAT_INT 3 "SNA" 2 "REQUEST_DATA" 1 "PROGAMMED" 0 "NA" ;
